[part 5 of 5: packages /POWERTRAIN to /SYSTEM]
AUTOSAR XML (schema 3.2.2)
package /POWERTRAIN  (continued)
  can cluster POWERTRAIN:  (continued)
    physical channel POWERTRAIN  (continued)
      frame NM_ECM_AR: id 0x558, from ECM, frame-length=8, can-addressing-mode=STANDARD  # Network Management
        nm pdu NM_ECM_AR: length=64, nm-cbv-position=0, nm-nid-position=8, nm-user-data-length=6  # Network Management
          signal Awake_Afterrun_Actv: start 26, 1 bit, little-endian, data-type=DC_BOOL, init-value=XDIS_h5tcyk98kzbgrc5svasomeyt/lfalse, transfer-property=PENDING  # Wachhalten für Nachlauf aktiv / Stay awake for afterrun active
          signal Awake_CCP_Actv: start 29, 1 bit, little-endian, data-type=DC_BOOL, init-value=XDIS_h5tcyk98kzbgrc5svasomeyt/lfalse, transfer-property=PENDING  # Wachhalten für CCP-Messtechnik aktiv / Stay awake for CCP measurement active
          signal Awake_Diag_Actv: start 24, 1 bit, little-endian, data-type=DC_BOOL, init-value=XDIS_h5tcyk98kzbgrc5svasomeyt/lfalse, transfer-property=PENDING  # Wachhalten für Diagnose aktiv / Stay awake for diagnostics active
          signal Awake_ECP3_Afterrun: start 30, 1 bit, little-endian, data-type=DC_BOOL, init-value=XDIS_h5tcyk98kzbgrc5svasomeyt/lfalse, transfer-property=PENDING  # Wachhalten für ECP3 Nachlauf / Stay awake for ECP3 afterrun
          signal Awake_ECP4_Afterrun: start 31, 1 bit, little-endian, data-type=DC_BOOL, init-value=XDIS_h5tcyk98kzbgrc5svasomeyt/lfalse, transfer-property=PENDING  # Wachhalten für ECP4 Nachlauf / Stay awake for ECP4 afterrun
          signal Awake_EngFan_Actv: start 27, 1 bit, little-endian, data-type=DC_BOOL, init-value=XDIS_h5tcyk98kzbgrc5svasomeyt/lfalse, transfer-property=PENDING  # Wachhalten für Motorlüfter aktiv / Stay awake for engine fan active
          signal Awake_EngRestart: start 28, 1 bit, little-endian, data-type=DC_BOOL, init-value=XDIS_h5tcyk98kzbgrc5svasomeyt/lfalse, transfer-property=PENDING  # Wachhalten für Motor-Wiederholstart / Stay awake for engine restart
          signal Awake_Ignition_On: start 25, 1 bit, little-endian, data-type=DC_BOOL, init-value=XDIS_h5tcyk98kzbgrc5svasomeyt/lfalse, transfer-property=PENDING  # Wachhalten für Zündung eingeschaltet / Stay awake for ignition on
          signal Awake_NwSt: start 34, 1 bit, little-endian, data-type=DC_BOOL, init-value=XDIS_h5tcyk98kzbgrc5svasomeyt/lfalse, transfer-property=PENDING  # Wachhalten für Netzwerkstartphase / Stay awake for network startup
          signal Awake_SensDiag_Actv: start 33, 1 bit, little-endian, data-type=DC_BOOL, init-value=XDIS_h5tcyk98kzbgrc5svasomeyt/lfalse, transfer-property=PENDING  # Wachhalten für Sensordiagnose / Stay awake for sensor diagnostics active
          signal Awake_TankPressDiag_Actv: start 32, 1 bit, little-endian, data-type=DC_BOOL, init-value=XDIS_h5tcyk98kzbgrc5svasomeyt/lfalse, transfer-property=PENDING  # Modus 15: Wachhalten für Tankpresse Diagnose aktiv / Mode 15: Stay awake for tank press diagnostics active
          signal NM_ActvWakeup: start 4, 1 bit, little-endian, data-type=XDIS_8zznnqbxnga51x5ej9fjpu597, init-value=XDIS_5un2e5dvr5cfu5m0829mn2f54/lfalse, transfer-property=PENDING  # Active Wakeup Bit
          signal NM_Coord_Id: start 1, 2 bit, little-endian, data-type=XDIS_ag9ggh2r04cqwuwmmjm5ytd7y, init-value=XDIS_9kvl7kybe3ytco3yjv5uyh4l/l0, transfer-property=PENDING  # NM Coordinator ID
          signal NM_Coord_SleepRdy: start 3, 1 bit, little-endian, data-type=XDIS_3jji6ucrc8il6b9sf0gioatpa, init-value=XDIS_bxrvh10jawmlothu6ak0oeoq1/lfalse, transfer-property=PENDING  # NM Coordinator Sleep Ready Bit
          signal NM_PartNw_Info: start 6, 1 bit, little-endian, data-type=XDIS_8anm4jlkd5rjz5a4dj8p5z2aw, init-value=XDIS_4setjwl49z8hlvz1qf446y4u9/lfalse, transfer-property=PENDING  # Partial Network Information Bit
          signal NM_RepeatMsg_Rq: start 0, 1 bit, little-endian, data-type=XDIS_ey4gzz3x4s3pbgmamj990b7l5, init-value=XDIS_28el54ybfxmt2nm5z16pi8wul/lfalse, transfer-property=PENDING  # Repeat Message Request
          signal NM_SrcNode_Id: start 8, 8 bit, little-endian, data-type=XDIS_dgxq2p852kecqaamwh1cpsgat, init-value=XDIS_atkxru0u5pzxs91gr5r6s45de/l0, transfer-property=PENDING  # Source Node Identifier
          signal WakeupRsn_ECM: start 16, 8 bit, little-endian, data-type=c08_WakeupRsn_ECM, init-value=XDIS_3y4lg9s0dpmmrleq719wxccpi/l255, transfer-property=PENDING  # Weckgrund / Wakeup reason
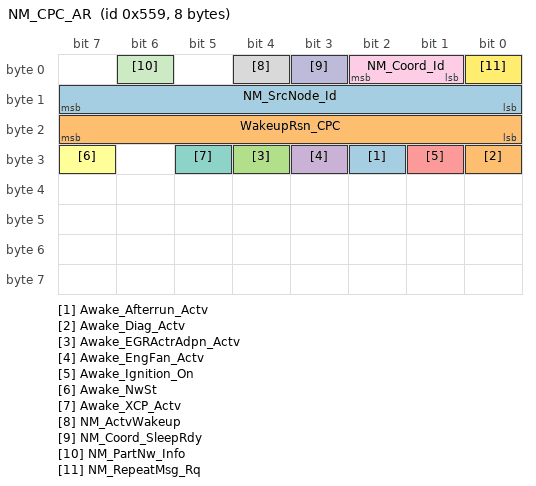
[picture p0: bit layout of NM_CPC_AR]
      frame NM_CPC_AR: id 0x559, from CPC, frame-length=8, can-addressing-mode=STANDARD  # Network Management
        nm pdu NM_CPC_AR: length=64, nm-cbv-position=0, nm-nid-position=8, nm-user-data-length=6  # Network Management
          signal Awake_Afterrun_Actv: start 26, 1 bit, little-endian, data-type=DC_BOOL, init-value=XDIS_h5tcyk98kzbgrc5svasomeyt/lfalse, transfer-property=PENDING  # Wachhalten für Nachlauf aktiv / Stay awake for afterrun active
          signal Awake_Diag_Actv: start 24, 1 bit, little-endian, data-type=DC_BOOL, init-value=XDIS_h5tcyk98kzbgrc5svasomeyt/lfalse, transfer-property=PENDING  # Wachhalten für Diagnose aktiv / Stay awake for diagnostics active
          signal Awake_EGRActrAdpn_Actv: start 28, 1 bit, little-endian, data-type=DC_BOOL, init-value=XDIS_h5tcyk98kzbgrc5svasomeyt/lfalse, transfer-property=PENDING  # Wachhalten für AGR-AktuatorAdaption aktiv / Stay awake for EGR actuator adaptation active
          signal Awake_EngFan_Actv: start 27, 1 bit, little-endian, data-type=DC_BOOL, init-value=XDIS_h5tcyk98kzbgrc5svasomeyt/lfalse, transfer-property=PENDING  # Wachhalten für Motorlüfter aktiv / Stay awake for engine fan active
          signal Awake_Ignition_On: start 25, 1 bit, little-endian, data-type=DC_BOOL, init-value=XDIS_h5tcyk98kzbgrc5svasomeyt/lfalse, transfer-property=PENDING  # Wachhalten für Zündung eingeschaltet / Stay awake for ignition on
          signal Awake_NwSt: start 31, 1 bit, little-endian, data-type=DC_BOOL, init-value=XDIS_h5tcyk98kzbgrc5svasomeyt/lfalse, transfer-property=PENDING  # Wachhalten für Netzwerkstartphase / Stay awake for network startup
          signal Awake_XCP_Actv: start 29, 1 bit, little-endian, data-type=DC_BOOL, init-value=XDIS_h5tcyk98kzbgrc5svasomeyt/lfalse, transfer-property=PENDING  # Wachhalten für XCP-Messung aktiv / Stay awake for XCP measurement active
          signal NM_ActvWakeup: start 4, 1 bit, little-endian, data-type=XDIS_8zznnqbxnga51x5ej9fjpu597, init-value=XDIS_5un2e5dvr5cfu5m0829mn2f54/lfalse, transfer-property=PENDING  # Active Wakeup Bit
          signal NM_Coord_Id: start 1, 2 bit, little-endian, data-type=XDIS_ag9ggh2r04cqwuwmmjm5ytd7y, init-value=XDIS_9kvl7kybe3ytco3yjv5uyh4l/l0, transfer-property=PENDING  # NM Coordinator ID
          signal NM_Coord_SleepRdy: start 3, 1 bit, little-endian, data-type=XDIS_3jji6ucrc8il6b9sf0gioatpa, init-value=XDIS_bxrvh10jawmlothu6ak0oeoq1/lfalse, transfer-property=PENDING  # NM Coordinator Sleep Ready Bit
          signal NM_PartNw_Info: start 6, 1 bit, little-endian, data-type=XDIS_8anm4jlkd5rjz5a4dj8p5z2aw, init-value=XDIS_4setjwl49z8hlvz1qf446y4u9/lfalse, transfer-property=PENDING  # Partial Network Information Bit
          signal NM_RepeatMsg_Rq: start 0, 1 bit, little-endian, data-type=XDIS_ey4gzz3x4s3pbgmamj990b7l5, init-value=XDIS_28el54ybfxmt2nm5z16pi8wul/lfalse, transfer-property=PENDING  # Repeat Message Request
          signal NM_SrcNode_Id: start 8, 8 bit, little-endian, data-type=XDIS_dgxq2p852kecqaamwh1cpsgat, init-value=XDIS_atkxru0u5pzxs91gr5r6s45de/l0, transfer-property=PENDING  # Source Node Identifier
          signal WakeupRsn_CPC: start 16, 8 bit, little-endian, data-type=c08_WakeupRsn_CPC, init-value=XDIS_zfdazignwfnolwf6r1u16rwh/l255, transfer-property=PENDING  # Weckgrund / Wakeup reason
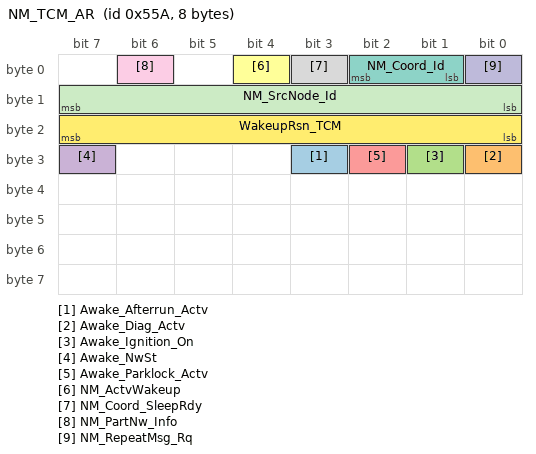
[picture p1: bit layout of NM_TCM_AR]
      frame NM_TCM_AR: id 0x55A, from TCM, frame-length=8, can-addressing-mode=STANDARD  # Network Management
        nm pdu NM_TCM_AR: length=64, nm-cbv-position=0, nm-nid-position=8, nm-user-data-length=6  # Network Management
          signal Awake_Afterrun_Actv: start 27, 1 bit, little-endian, data-type=DC_BOOL, init-value=XDIS_h5tcyk98kzbgrc5svasomeyt/lfalse, transfer-property=PENDING  # Wachhalten für Nachlauf aktiv / Stay awake for afterrun active
          signal Awake_Diag_Actv: start 24, 1 bit, little-endian, data-type=DC_BOOL, init-value=XDIS_h5tcyk98kzbgrc5svasomeyt/lfalse, transfer-property=PENDING  # Wachhalten für Diagnose aktiv / Stay awake for diagnostics active
          signal Awake_Ignition_On: start 25, 1 bit, little-endian, data-type=DC_BOOL, init-value=XDIS_h5tcyk98kzbgrc5svasomeyt/lfalse, transfer-property=PENDING  # Wachhalten für Zündung eingeschaltet / Stay awake for ignition on
          signal Awake_NwSt: start 31, 1 bit, little-endian, data-type=DC_BOOL, init-value=XDIS_h5tcyk98kzbgrc5svasomeyt/lfalse, transfer-property=PENDING  # Wachhalten für Netzwerkstartphase / Stay awake for network startup
          signal Awake_Parklock_Actv: start 26, 1 bit, little-endian, data-type=DC_BOOL, init-value=XDIS_h5tcyk98kzbgrc5svasomeyt/lfalse, transfer-property=PENDING  # Wachhalten für Parklock / Stay awake for moving the Parklock
          signal NM_ActvWakeup: start 4, 1 bit, little-endian, data-type=XDIS_8zznnqbxnga51x5ej9fjpu597, init-value=XDIS_5un2e5dvr5cfu5m0829mn2f54/lfalse, transfer-property=PENDING  # Active Wakeup Bit
          signal NM_Coord_Id: start 1, 2 bit, little-endian, data-type=XDIS_ag9ggh2r04cqwuwmmjm5ytd7y, init-value=XDIS_9kvl7kybe3ytco3yjv5uyh4l/l0, transfer-property=PENDING  # NM Coordinator ID
          signal NM_Coord_SleepRdy: start 3, 1 bit, little-endian, data-type=XDIS_3jji6ucrc8il6b9sf0gioatpa, init-value=XDIS_bxrvh10jawmlothu6ak0oeoq1/lfalse, transfer-property=PENDING  # NM Coordinator Sleep Ready Bit
          signal NM_PartNw_Info: start 6, 1 bit, little-endian, data-type=XDIS_8anm4jlkd5rjz5a4dj8p5z2aw, init-value=XDIS_4setjwl49z8hlvz1qf446y4u9/lfalse, transfer-property=PENDING  # Partial Network Information Bit
          signal NM_RepeatMsg_Rq: start 0, 1 bit, little-endian, data-type=XDIS_ey4gzz3x4s3pbgmamj990b7l5, init-value=XDIS_28el54ybfxmt2nm5z16pi8wul/lfalse, transfer-property=PENDING  # Repeat Message Request
          signal NM_SrcNode_Id: start 8, 8 bit, little-endian, data-type=XDIS_dgxq2p852kecqaamwh1cpsgat, init-value=XDIS_atkxru0u5pzxs91gr5r6s45de/l0, transfer-property=PENDING  # Source Node Identifier
          signal WakeupRsn_TCM: start 16, 8 bit, little-endian, data-type=c08_WakeupRsn_TCM, init-value=XDIS_e4uet9j8xwkldgba4oq2381xs/l255, transfer-property=PENDING  # Weckgrund / Wakeup reason
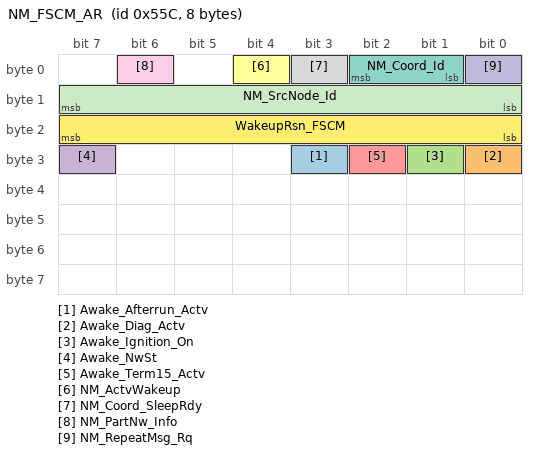
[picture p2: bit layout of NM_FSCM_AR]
      frame NM_FSCM_AR: id 0x55C, from FSCM, frame-length=8, can-addressing-mode=STANDARD  # Network Management
        nm pdu NM_FSCM_AR: length=64, nm-cbv-position=0, nm-nid-position=8, nm-user-data-length=6  # Network Management
          signal Awake_Afterrun_Actv: start 27, 1 bit, little-endian, data-type=DC_BOOL, init-value=XDIS_h5tcyk98kzbgrc5svasomeyt/lfalse, transfer-property=PENDING  # Wachhalten für Nachlauf aktiv / Stay awake for afterrun active
          signal Awake_Diag_Actv: start 24, 1 bit, little-endian, data-type=DC_BOOL, init-value=XDIS_h5tcyk98kzbgrc5svasomeyt/lfalse, transfer-property=PENDING  # Wachhalten für Diagnose aktiv / Stay awake for diagnostics active
          signal Awake_Ignition_On: start 25, 1 bit, little-endian, data-type=DC_BOOL, init-value=XDIS_h5tcyk98kzbgrc5svasomeyt/lfalse, transfer-property=PENDING  # Wachhalten für Zündung eingeschaltet / Stay awake for ignition on
          signal Awake_NwSt: start 31, 1 bit, little-endian, data-type=DC_BOOL, init-value=XDIS_h5tcyk98kzbgrc5svasomeyt/lfalse, transfer-property=PENDING  # Wachhalten für Netzwerkstartphase / Stay awake for network startup
          signal Awake_Term15_Actv: start 26, 1 bit, little-endian, data-type=DC_BOOL, init-value=XDIS_h5tcyk98kzbgrc5svasomeyt/lfalse, transfer-property=PENDING  # Wachhalten für Klemme 15 aktiv / Stay awake for terminal 15 active
          signal NM_ActvWakeup: start 4, 1 bit, little-endian, data-type=XDIS_8zznnqbxnga51x5ej9fjpu597, init-value=XDIS_5un2e5dvr5cfu5m0829mn2f54/lfalse, transfer-property=PENDING  # Active Wakeup Bit
          signal NM_Coord_Id: start 1, 2 bit, little-endian, data-type=XDIS_ag9ggh2r04cqwuwmmjm5ytd7y, init-value=XDIS_9kvl7kybe3ytco3yjv5uyh4l/l0, transfer-property=PENDING  # NM Coordinator ID
          signal NM_Coord_SleepRdy: start 3, 1 bit, little-endian, data-type=XDIS_3jji6ucrc8il6b9sf0gioatpa, init-value=XDIS_bxrvh10jawmlothu6ak0oeoq1/lfalse, transfer-property=PENDING  # NM Coordinator Sleep Ready Bit
          signal NM_PartNw_Info: start 6, 1 bit, little-endian, data-type=XDIS_8anm4jlkd5rjz5a4dj8p5z2aw, init-value=XDIS_4setjwl49z8hlvz1qf446y4u9/lfalse, transfer-property=PENDING  # Partial Network Information Bit
          signal NM_RepeatMsg_Rq: start 0, 1 bit, little-endian, data-type=XDIS_ey4gzz3x4s3pbgmamj990b7l5, init-value=XDIS_28el54ybfxmt2nm5z16pi8wul/lfalse, transfer-property=PENDING  # Repeat Message Request
          signal NM_SrcNode_Id: start 8, 8 bit, little-endian, data-type=XDIS_dgxq2p852kecqaamwh1cpsgat, init-value=XDIS_atkxru0u5pzxs91gr5r6s45de/l0, transfer-property=PENDING  # Source Node Identifier
          signal WakeupRsn_FSCM: start 16, 8 bit, little-endian, data-type=c08_WakeupRsn_FSCM, init-value=XDIS_c1uleirk2bcioplgr7prkm23d/l255, transfer-property=PENDING  # Weckgrund / Wakeup reason
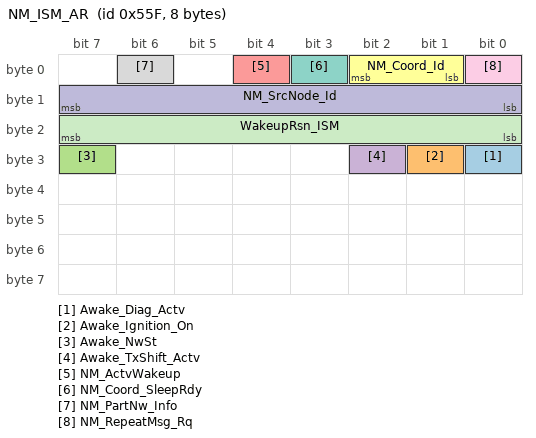
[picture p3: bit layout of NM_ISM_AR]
      frame NM_ISM_AR: id 0x55F, from ISM, frame-length=8, can-addressing-mode=STANDARD  # Network Management
        nm pdu NM_ISM_AR: length=64, nm-cbv-position=0, nm-nid-position=8, nm-user-data-length=6  # Network Management
          signal Awake_Diag_Actv: start 24, 1 bit, little-endian, data-type=DC_BOOL, init-value=XDIS_h5tcyk98kzbgrc5svasomeyt/lfalse, transfer-property=PENDING  # Wachhalten für Diagnose aktiv / Stay awake for diagnostics active
          signal Awake_Ignition_On: start 25, 1 bit, little-endian, data-type=DC_BOOL, init-value=XDIS_h5tcyk98kzbgrc5svasomeyt/lfalse, transfer-property=PENDING  # Wachhalten für Zündung eingeschaltet / Stay awake for ignition on
          signal Awake_NwSt: start 31, 1 bit, little-endian, data-type=DC_BOOL, init-value=XDIS_h5tcyk98kzbgrc5svasomeyt/lfalse, transfer-property=PENDING  # Wachhalten für Netzwerkstartphase / Stay awake for network startup
          signal Awake_TxShift_Actv: start 26, 1 bit, little-endian, data-type=DC_BOOL, init-value=XDIS_h5tcyk98kzbgrc5svasomeyt/lfalse, transfer-property=PENDING  # Wachhalten für Getriebe-Schaltvorgang aktiv / Stay awake for transmission shifting active
          signal NM_ActvWakeup: start 4, 1 bit, little-endian, data-type=XDIS_8zznnqbxnga51x5ej9fjpu597, init-value=XDIS_5un2e5dvr5cfu5m0829mn2f54/lfalse, transfer-property=PENDING  # Active Wakeup Bit
          signal NM_Coord_Id: start 1, 2 bit, little-endian, data-type=XDIS_ag9ggh2r04cqwuwmmjm5ytd7y, init-value=XDIS_9kvl7kybe3ytco3yjv5uyh4l/l0, transfer-property=PENDING  # NM Coordinator ID
          signal NM_Coord_SleepRdy: start 3, 1 bit, little-endian, data-type=XDIS_3jji6ucrc8il6b9sf0gioatpa, init-value=XDIS_bxrvh10jawmlothu6ak0oeoq1/lfalse, transfer-property=PENDING  # NM Coordinator Sleep Ready Bit
          signal NM_PartNw_Info: start 6, 1 bit, little-endian, data-type=XDIS_8anm4jlkd5rjz5a4dj8p5z2aw, init-value=XDIS_4setjwl49z8hlvz1qf446y4u9/lfalse, transfer-property=PENDING  # Partial Network Information Bit
          signal NM_RepeatMsg_Rq: start 0, 1 bit, little-endian, data-type=XDIS_ey4gzz3x4s3pbgmamj990b7l5, init-value=XDIS_28el54ybfxmt2nm5z16pi8wul/lfalse, transfer-property=PENDING  # Repeat Message Request
          signal NM_SrcNode_Id: start 8, 8 bit, little-endian, data-type=XDIS_dgxq2p852kecqaamwh1cpsgat, init-value=XDIS_atkxru0u5pzxs91gr5r6s45de/l0, transfer-property=PENDING  # Source Node Identifier
          signal WakeupRsn_ISM: start 16, 8 bit, little-endian, data-type=c08_WakeupRsn_ISM, init-value=XDIS_2o0otao352rw44tj5bta4i007/l255, transfer-property=PENDING  # Weckgrund / Wakeup reason
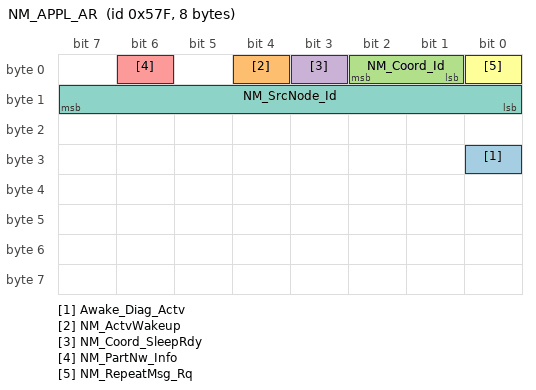
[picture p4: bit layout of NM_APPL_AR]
      frame NM_APPL_AR: id 0x57F, to ASX CPC DRVU ECM FSCM ISM TCM, frame-length=8, can-addressing-mode=STANDARD, rx-identifier-range={lower-can-id=1280, upper-can-id=1407}
        nm pdu NM_APPL_AR: length=64, nm-cbv-position=0, nm-nid-position=8, nm-user-data-length=6  # Network Management
          signal Awake_Diag_Actv: start 24, 1 bit, little-endian, data-type=DC_BOOL, init-value=XDIS_h5tcyk98kzbgrc5svasomeyt/lfalse, transfer-property=PENDING  # Wachhalten für Diagnose aktiv / Stay awake for diagnostics active
          signal NM_ActvWakeup: start 4, 1 bit, little-endian, data-type=XDIS_8zznnqbxnga51x5ej9fjpu597, init-value=XDIS_5un2e5dvr5cfu5m0829mn2f54/lfalse, transfer-property=PENDING  # Active Wakeup Bit
          signal NM_Coord_Id: start 1, 2 bit, little-endian, data-type=XDIS_ag9ggh2r04cqwuwmmjm5ytd7y, init-value=XDIS_9kvl7kybe3ytco3yjv5uyh4l/l0, transfer-property=PENDING  # NM Coordinator ID
          signal NM_Coord_SleepRdy: start 3, 1 bit, little-endian, data-type=XDIS_3jji6ucrc8il6b9sf0gioatpa, init-value=XDIS_bxrvh10jawmlothu6ak0oeoq1/lfalse, transfer-property=PENDING  # NM Coordinator Sleep Ready Bit
          signal NM_PartNw_Info: start 6, 1 bit, little-endian, data-type=XDIS_8anm4jlkd5rjz5a4dj8p5z2aw, init-value=XDIS_4setjwl49z8hlvz1qf446y4u9/lfalse, transfer-property=PENDING  # Partial Network Information Bit
          signal NM_RepeatMsg_Rq: start 0, 1 bit, little-endian, data-type=XDIS_ey4gzz3x4s3pbgmamj990b7l5, init-value=XDIS_28el54ybfxmt2nm5z16pi8wul/lfalse, transfer-property=PENDING  # Repeat Message Request
          signal NM_SrcNode_Id: start 8, 8 bit, little-endian, data-type=XDIS_dgxq2p852kecqaamwh1cpsgat, init-value=XDIS_atkxru0u5pzxs91gr5r6s45de/l0, transfer-property=PENDING  # Source Node Identifier
      frame DIAG_RS_ASX: id 0x5AA, from ASX, to CPC, frame-length=8, can-addressing-mode=STANDARD  # Diagnoseantwort / Diagnostic Response
        n pdu DIAG_RS_ASX: length=64, unused-bit-pattern=0  # Diagnose Antwort / Diagnostic Response
      frame DIAG_RS_FFAP: id 0x5DC, from FFAP_STAR_2, to CPC, frame-length=8, can-addressing-mode=STANDARD  # Diagnoseantwort / Diagnostic Response
        n pdu DIAG_RS_FFAP: length=64, unused-bit-pattern=0  # Diagnose Antwort / Diagnostic Response
      frame DIAG_RS_AWD: id 0x5DE, to CPC, frame-length=8, can-addressing-mode=STANDARD  # Diagnoseantwort / Diagnostic Response
        n pdu DIAG_RS_AWD: length=64, unused-bit-pattern=0  # Diagnose Antwort / Diagnostic Response
      frame DIAG_RS_ISM: id 0x5DF, from ISM, to CPC, frame-length=8, can-addressing-mode=STANDARD  # Diagnoseantwort / Diagnostic Response
        n pdu DIAG_RS_ISM: length=64, unused-bit-pattern=0  # Diagnose-Response / Diagnostic Response
      frame DIAG_RQ_ASX: id 0x62A, from CPC, to ASX, frame-length=8, can-addressing-mode=STANDARD  # Diagnose Anfrage / Diagnostic Request
        n pdu DIAG_RQ_ASX: length=64, unused-bit-pattern=0  # Diagnose Anfrage / Diagnostic Request
      frame DIAG_RQ_FFAP: id 0x65C, from CPC, to FFAP_STAR_2, frame-length=8, can-addressing-mode=STANDARD  # Diagnose Anfrage / Diagnostic Request
        n pdu DIAG_RQ_FFAP: length=64, unused-bit-pattern=0  # Diagnose Anfrage / Diagnostic Request
      frame DIAG_RQ_AWD: id 0x65E, from CPC, frame-length=8, can-addressing-mode=STANDARD  # Diagnose Anfrage / Diagnostic Request
        n pdu DIAG_RQ_AWD: length=64, unused-bit-pattern=0  # Diagnose Anfrage / Diagnostic Request
      frame DIAG_RQ_ISM: id 0x65F, from CPC, to ISM, frame-length=8, can-addressing-mode=STANDARD  # Diagnoseanfrage / Diagnostic Request
        n pdu DIAG_RQ_ISM: length=64, unused-bit-pattern=0  # Diagnose-Request / Diagnostic Request
      frame DIAG_RQ_TCM: id 0x7E1, from CPC, to TCM, frame-length=8, can-addressing-mode=STANDARD  # Diagnoseanfrage / Diagnostic Request
        n pdu DIAG_RQ_TCM: length=64, unused-bit-pattern=0  # Diagnoseanfrage / Diagnostic Request
      frame DIAG_RQ_FSCM: id 0x7E3, from CPC, to FSCM, frame-length=8, can-addressing-mode=STANDARD  # Diagnoseanfrage / Diagnostic Request
        n pdu DIAG_RQ_FSCM: length=64, unused-bit-pattern=0  # Diagnoseanfrage / Diagnostic Request
      frame DIAG_RS_TCM: id 0x7E9, from TCM, to CPC, frame-length=8, can-addressing-mode=STANDARD  # Diagnoseantwort / Diagnostic Response
        n pdu DIAG_RS_TCM: length=64, unused-bit-pattern=0  # Diagnoseantwort / Diagnostic Response
      frame DIAG_RS_FSCM: id 0x7EB, from FSCM, to CPC, frame-length=8, can-addressing-mode=STANDARD  # Diagnoseantwort / Diagnostic Response
        n pdu DIAG_RS_FSCM: length=64, unused-bit-pattern=0  # Diagnoseantwort / Diagnostic Response
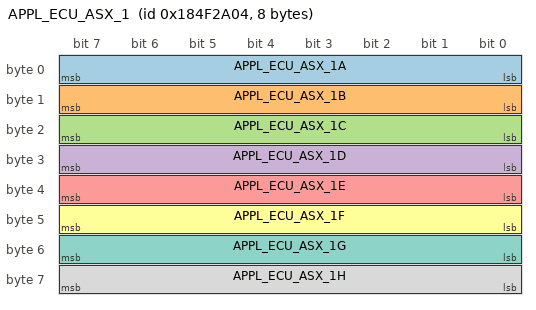
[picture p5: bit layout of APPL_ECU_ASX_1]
      frame APPL_ECU_ASX_1: id 0x184F2A04, to ASX, frame-length=8, can-addressing-mode=EXTENDED
        pdu APPL_ECU_ASX_1: length=64, unused-bit-pattern=0, event-controlled-timing=number-of-repeats=0, minimum-delay=0.0050  # Applikation zu Steuergerät / Application to ECU
          signal APPL_ECU_ASX_1A: start 0, 8 bit, little-endian, data-type=c08_UInt_SNA_na, init-value=XDIS_2kt9ss9xytkqyzr4359iyexvi/l0, to ASX  # Applikation zu Steuergerät / Application to ECU
          signal APPL_ECU_ASX_1B: start 8, 8 bit, little-endian, data-type=c08_UInt_SNA_na, init-value=XDIS_2kt9ss9xytkqyzr4359iyexvi/l0, to ASX  # Applikation zu Steuergerät / Application to ECU
          signal APPL_ECU_ASX_1C: start 16, 8 bit, little-endian, data-type=c08_UInt_SNA_na, init-value=XDIS_2kt9ss9xytkqyzr4359iyexvi/l0, to ASX  # Applikation zu Steuergerät / Application to ECU
          signal APPL_ECU_ASX_1D: start 24, 8 bit, little-endian, data-type=c08_UInt_SNA_na, init-value=XDIS_2kt9ss9xytkqyzr4359iyexvi/l0, to ASX  # Applikation zu Steuergerät / Application to ECU
          signal APPL_ECU_ASX_1E: start 32, 8 bit, little-endian, data-type=c08_UInt_SNA_na, init-value=XDIS_2kt9ss9xytkqyzr4359iyexvi/l0, to ASX  # Applikation zu Steuergerät / Application to ECU
          signal APPL_ECU_ASX_1F: start 40, 8 bit, little-endian, data-type=c08_UInt_SNA_na, init-value=XDIS_2kt9ss9xytkqyzr4359iyexvi/l0, to ASX  # Applikation zu Steuergerät / Application to ECU
          signal APPL_ECU_ASX_1G: start 48, 8 bit, little-endian, data-type=c08_UInt_SNA_na, init-value=XDIS_2kt9ss9xytkqyzr4359iyexvi/l0, to ASX  # Applikation zu Steuergerät / Application to ECU
          signal APPL_ECU_ASX_1H: start 56, 8 bit, little-endian, data-type=c08_UInt_SNA_na, init-value=XDIS_2kt9ss9xytkqyzr4359iyexvi/l0, to ASX  # Applikation zu Steuergerät / Application to ECU
          signal APPL_ECU_ASX_1_5v54k457m0s1vt3vxsj5u865a: little-endian, system-signal=[APPL_ECU_ASX_1A, APPL_ECU_ASX_1B, APPL_ECU_ASX_1C, APPL_ECU_ASX_1D, APPL_ECU_ASX_1E, APPL_ECU_ASX_1F, APPL_ECU_ASX_1G, APPL_ECU_ASX_1H], transfer-property=TRIGGERED, to ASX  # Applikation zu Steuergerät (degraded) / Application to ECU (degraded)
      frame DIAGX_RQ_TCM_OBD: id 0x18DA5AF1, from CPC, to TCM, frame-length=8, can-addressing-mode=EXTENDED  # Diagnoseanfrage OBD / Diagnostic Request OBD
        n pdu DIAGX_RQ_TCM_OBD: length=64, unused-bit-pattern=0  # Diagnoseanfrage OBD / Diagnostic Request OBD
      frame DIAGX_RQ_FSCM_OBD: id 0x18DA5CF1, from CPC, to FSCM, frame-length=8, can-addressing-mode=EXTENDED  # Diagnoseanfrage OBD / Diagnostic Request OBD
        n pdu DIAGX_RQ_FSCM_OBD: length=64, unused-bit-pattern=0  # Diagnoseanfrage OBD / Diagnostic Request OBD
      frame DIAGX_RS_TCM_OBD: id 0x18DAF15A, from TCM, to CPC, frame-length=8, can-addressing-mode=EXTENDED  # Diagnoseantwort OBD / Diagnostic Response OBD
        n pdu DIAGX_RS_TCM_OBD: length=64, unused-bit-pattern=0  # Diagnoseantwort OBD / Diagnostic Response OBD
      frame DIAGX_RS_FSCM_OBD: id 0x18DAF15C, from FSCM, to CPC, frame-length=8, can-addressing-mode=EXTENDED  # Diagnoseantwort OBD / Diagnostic Response OBD
        n pdu DIAGX_RS_FSCM_OBD: length=64, unused-bit-pattern=0  # Diagnoseantwort OBD / Diagnostic Response OBD
      frame DIAGX_RQ_GLOBAL_OBD: id 0x18DB33F1, from CPC, to FSCM TCM, frame-length=8, can-addressing-mode=EXTENDED  # Funktionale Diagnose Anfrage (OBD) / Functional Diagnostic Request (OBD)
        n pdu DIAGX_RQ_GLOBAL_OBD: length=64, unused-bit-pattern=0  # Funktionaler Diagnose-Request (OBD) / Functional Diagnostic Request (OBD)
      frame ROE_ASX: id 0x18EF2A00, from ASX, to CPC, frame-length=8, can-addressing-mode=EXTENDED  # RoE lite
        pdu ROE_ASX: length=64, unused-bit-pattern=0, event-controlled-timing=number-of-repeats=0, minimum-delay=0.2  # RoE-lite / RoE lite
          signal ROE_DTC_ASX: start 32, 24 bit, little-endian, data-type=c24_0_16777215_1_SNA_na, init-value=XDIS_d00a2pwsicon8afnf0ovtodtq/l0, to CPC  # Fehlercode RoE-lite / RoE lite diagnostic trouble code
          signal ROE_DTC_Stat_ASX: start 56, 8 bit, little-endian, data-type=c08_0_255_1_SNA_na, init-value=XDIS_e83grhz0aqm1yaa82ns55ebek/l0, to CPC  # Fehlercode-Status RoE-lite / RoE lite diagnostic trouble code state
          signal ROE_Header_ASX: start 0, 32 bit, little-endian, data-type=c32_0_4294967295_1_SNA_na, init-value=l940295, to CPC  # Header RoE-lite / RoE lite header
          signal ROE_ASX_bh0k1l31zxyeftblxvt1o8neg: little-endian, system-signal=[ROE_DTC_ASX, ROE_DTC_Stat_ASX, ROE_Header_ASX], transfer-property=TRIGGERED, to CPC  # RoE-lite (degraded) / RoE lite (degraded)
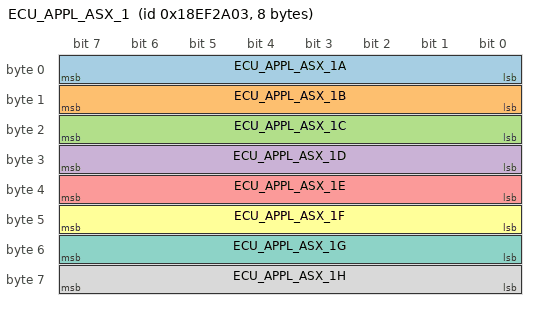
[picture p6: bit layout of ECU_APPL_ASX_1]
      frame ECU_APPL_ASX_1: id 0x18EF2A03, from ASX, frame-length=8, can-addressing-mode=EXTENDED
        pdu ECU_APPL_ASX_1: length=64, unused-bit-pattern=0, event-controlled-timing=number-of-repeats=0, minimum-delay=0.0050  # Applikation zu Steuergerät / Application to ECU
          signal ECU_APPL_ASX_1A: start 0, 8 bit, little-endian, data-type=c08_UInt_SNA_na, init-value=XDIS_2kt9ss9xytkqyzr4359iyexvi/l0  # Applikation zu Steuergerät / Application to ECU
          signal ECU_APPL_ASX_1B: start 8, 8 bit, little-endian, data-type=c08_UInt_SNA_na, init-value=XDIS_2kt9ss9xytkqyzr4359iyexvi/l0  # Applikation zu Steuergerät / Application to ECU
          signal ECU_APPL_ASX_1C: start 16, 8 bit, little-endian, data-type=c08_UInt_SNA_na, init-value=XDIS_2kt9ss9xytkqyzr4359iyexvi/l0  # Applikation zu Steuergerät / Application to ECU
          signal ECU_APPL_ASX_1D: start 24, 8 bit, little-endian, data-type=c08_UInt_SNA_na, init-value=XDIS_2kt9ss9xytkqyzr4359iyexvi/l0  # Applikation zu Steuergerät / Application to ECU
          signal ECU_APPL_ASX_1E: start 32, 8 bit, little-endian, data-type=c08_UInt_SNA_na, init-value=XDIS_2kt9ss9xytkqyzr4359iyexvi/l0  # Applikation zu Steuergerät / Application to ECU
          signal ECU_APPL_ASX_1F: start 40, 8 bit, little-endian, data-type=c08_UInt_SNA_na, init-value=XDIS_2kt9ss9xytkqyzr4359iyexvi/l0  # Applikation zu Steuergerät / Application to ECU
          signal ECU_APPL_ASX_1G: start 48, 8 bit, little-endian, data-type=c08_UInt_SNA_na, init-value=XDIS_2kt9ss9xytkqyzr4359iyexvi/l0  # Applikation zu Steuergerät / Application to ECU
          signal ECU_APPL_ASX_1H: start 56, 8 bit, little-endian, data-type=c08_UInt_SNA_na, init-value=XDIS_2kt9ss9xytkqyzr4359iyexvi/l0  # Applikation zu Steuergerät / Application to ECU
          signal ECU_APPL_ASX_1_3be5jsdyicsypdagrm44msol0: little-endian, system-signal=[ECU_APPL_ASX_1A, ECU_APPL_ASX_1B, ECU_APPL_ASX_1C, ECU_APPL_ASX_1D, ECU_APPL_ASX_1E, ECU_APPL_ASX_1F, ECU_APPL_ASX_1G, ECU_APPL_ASX_1H], transfer-property=TRIGGERED  # Applikation zu Steuergerät (degraded) / Application to ECU (degraded)
      frame ROE_TCM: id 0x18EF5A00, from TCM, to CPC, frame-length=8, can-addressing-mode=EXTENDED  # RoE lite
        pdu ROE_TCM: length=64, unused-bit-pattern=0, event-controlled-timing=number-of-repeats=0, minimum-delay=0.2  # RoE-lite / RoE lite
          signal ROE_DTC_Stat_TCM: start 56, 8 bit, little-endian, data-type=c08_0_255_1_SNA_na, init-value=XDIS_e83grhz0aqm1yaa82ns55ebek/l0, to CPC  # Fehlercode-Status RoE-lite / RoE lite diagnostic trouble code state
          signal ROE_DTC_TCM: start 32, 24 bit, little-endian, data-type=c24_0_16777215_1_SNA_na, init-value=XDIS_d00a2pwsicon8afnf0ovtodtq/l0, to CPC  # Fehlercode RoE-lite / RoE lite diagnostic trouble code
          signal ROE_Header_TCM: start 0, 32 bit, little-endian, data-type=c32_0_4294967295_1_SNA_na, init-value=l940295, to CPC  # Header RoE-lite / RoE lite header
          signal ROE_TCM_7sr2csz1sd5kgujzog3cttxu0: little-endian, system-signal=[ROE_DTC_Stat_TCM, ROE_DTC_TCM, ROE_Header_TCM], transfer-property=TRIGGERED, to CPC  # RoE-lite (degraded) / RoE lite (degraded)
      frame XCP_Rq_TCM: id 0x18EF5A01, from CPC, to TCM, frame-length=8, can-addressing-mode=EXTENDED
        user defined i pdu XCP_Rq_TCM: length=64, unused-bit-pattern=0, cdd-type=XCP  # XCP-Anforderung / Extended calibration protocol request
      frame XCP_Rs_TCM: id 0x18EF5A02, from TCM, to CPC, frame-length=8, can-addressing-mode=EXTENDED
        user defined i pdu XCP_Rs_TCM: length=64, unused-bit-pattern=0, cdd-type=XCP  # XCP-Anforderung / Extended calibration protocol response
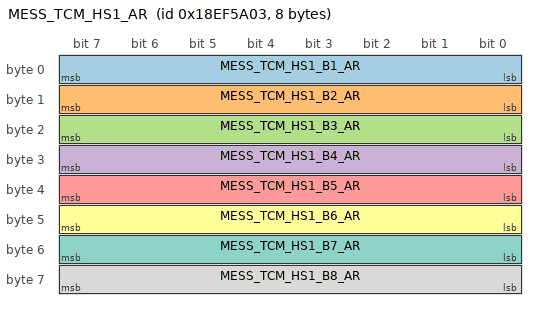
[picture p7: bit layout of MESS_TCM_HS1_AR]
      frame MESS_TCM_HS1_AR: id 0x18EF5A03, to TCM, frame-length=8, can-addressing-mode=EXTENDED  # TCM_HS1_AR
        pdu MESS_TCM_HS1_AR: length=64, unused-bit-pattern=0, event-controlled-timing=number-of-repeats=0, minimum-delay=0.0050
          signal MESS_TCM_HS1_B1_AR: start 0, 8 bit, little-endian, data-type=c08_UInt_SNA_na, init-value=XDIS_2kt9ss9xytkqyzr4359iyexvi/l0, to TCM
          signal MESS_TCM_HS1_B2_AR: start 8, 8 bit, little-endian, data-type=c08_UInt_SNA_na, init-value=XDIS_2kt9ss9xytkqyzr4359iyexvi/l0, to TCM
          signal MESS_TCM_HS1_B3_AR: start 16, 8 bit, little-endian, data-type=c08_UInt_SNA_na, init-value=XDIS_2kt9ss9xytkqyzr4359iyexvi/l0, to TCM
          signal MESS_TCM_HS1_B4_AR: start 24, 8 bit, little-endian, data-type=c08_UInt_SNA_na, init-value=XDIS_2kt9ss9xytkqyzr4359iyexvi/l0, to TCM
          signal MESS_TCM_HS1_B5_AR: start 32, 8 bit, little-endian, data-type=c08_UInt_SNA_na, init-value=XDIS_2kt9ss9xytkqyzr4359iyexvi/l0, to TCM
          signal MESS_TCM_HS1_B6_AR: start 40, 8 bit, little-endian, data-type=c08_UInt_SNA_na, init-value=XDIS_2kt9ss9xytkqyzr4359iyexvi/l0, to TCM
          signal MESS_TCM_HS1_B7_AR: start 48, 8 bit, little-endian, data-type=c08_UInt_SNA_na, init-value=XDIS_2kt9ss9xytkqyzr4359iyexvi/l0, to TCM
          signal MESS_TCM_HS1_B8_AR: start 56, 8 bit, little-endian, data-type=c08_UInt_SNA_na, init-value=XDIS_2kt9ss9xytkqyzr4359iyexvi/l0, to TCM
          signal Mess_TCM_HS1_AR_5jqztx9cjivblmvl1y06ch5be: little-endian, system-signal=[MESS_TCM_HS1_B1_AR, MESS_TCM_HS1_B2_AR, MESS_TCM_HS1_B3_AR, MESS_TCM_HS1_B4_AR, MESS_TCM_HS1_B5_AR, MESS_TCM_HS1_B6_AR, MESS_TCM_HS1_B7_AR, MESS_TCM_HS1_B8_AR], transfer-property=TRIGGERED, to TCM  # Messdaten (degraded) / Measurement data (degraded)
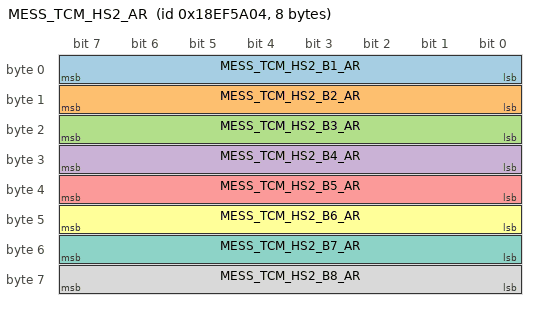
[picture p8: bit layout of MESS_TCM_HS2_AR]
      frame MESS_TCM_HS2_AR: id 0x18EF5A04, to TCM, frame-length=8, can-addressing-mode=EXTENDED  # TCM_HS2_AR
        pdu MESS_TCM_HS2_AR: length=64, unused-bit-pattern=0, event-controlled-timing=number-of-repeats=0, minimum-delay=0.0050
          signal MESS_TCM_HS2_B1_AR: start 0, 8 bit, little-endian, data-type=c08_UInt_SNA_na, init-value=XDIS_2kt9ss9xytkqyzr4359iyexvi/l0, to TCM
          signal MESS_TCM_HS2_B2_AR: start 8, 8 bit, little-endian, data-type=c08_UInt_SNA_na, init-value=XDIS_2kt9ss9xytkqyzr4359iyexvi/l0, to TCM
          signal MESS_TCM_HS2_B3_AR: start 16, 8 bit, little-endian, data-type=c08_UInt_SNA_na, init-value=XDIS_2kt9ss9xytkqyzr4359iyexvi/l0, to TCM
          signal MESS_TCM_HS2_B4_AR: start 24, 8 bit, little-endian, data-type=c08_UInt_SNA_na, init-value=XDIS_2kt9ss9xytkqyzr4359iyexvi/l0, to TCM
          signal MESS_TCM_HS2_B5_AR: start 32, 8 bit, little-endian, data-type=c08_UInt_SNA_na, init-value=XDIS_2kt9ss9xytkqyzr4359iyexvi/l0, to TCM
          signal MESS_TCM_HS2_B6_AR: start 40, 8 bit, little-endian, data-type=c08_UInt_SNA_na, init-value=XDIS_2kt9ss9xytkqyzr4359iyexvi/l0, to TCM
          signal MESS_TCM_HS2_B7_AR: start 48, 8 bit, little-endian, data-type=c08_UInt_SNA_na, init-value=XDIS_2kt9ss9xytkqyzr4359iyexvi/l0, to TCM
          signal MESS_TCM_HS2_B8_AR: start 56, 8 bit, little-endian, data-type=c08_UInt_SNA_na, init-value=XDIS_2kt9ss9xytkqyzr4359iyexvi/l0, to TCM
          signal Mess_TCM_HS2_AR_dcm84cc8pxh7e5mqxg338wu8c: little-endian, system-signal=[MESS_TCM_HS2_B1_AR, MESS_TCM_HS2_B2_AR, MESS_TCM_HS2_B3_AR, MESS_TCM_HS2_B4_AR, MESS_TCM_HS2_B5_AR, MESS_TCM_HS2_B6_AR, MESS_TCM_HS2_B7_AR, MESS_TCM_HS2_B8_AR], transfer-property=TRIGGERED, to TCM  # Messdaten (degraded) / Measurement data (degraded)
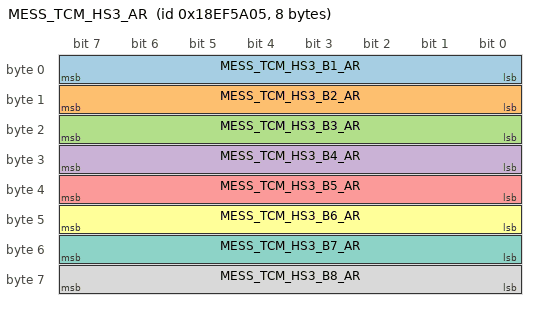
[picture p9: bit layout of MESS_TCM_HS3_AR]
      frame MESS_TCM_HS3_AR: id 0x18EF5A05, to TCM, frame-length=8, can-addressing-mode=EXTENDED  # TCM_HS3_AR
        pdu MESS_TCM_HS3_AR: length=64, unused-bit-pattern=0, event-controlled-timing=number-of-repeats=0, minimum-delay=0.0050
          signal MESS_TCM_HS3_B1_AR: start 0, 8 bit, little-endian, data-type=c08_UInt_SNA_na, init-value=XDIS_2kt9ss9xytkqyzr4359iyexvi/l0, to TCM
          signal MESS_TCM_HS3_B2_AR: start 8, 8 bit, little-endian, data-type=c08_UInt_SNA_na, init-value=XDIS_2kt9ss9xytkqyzr4359iyexvi/l0, to TCM
          signal MESS_TCM_HS3_B3_AR: start 16, 8 bit, little-endian, data-type=c08_UInt_SNA_na, init-value=XDIS_2kt9ss9xytkqyzr4359iyexvi/l0, to TCM
          signal MESS_TCM_HS3_B4_AR: start 24, 8 bit, little-endian, data-type=c08_UInt_SNA_na, init-value=XDIS_2kt9ss9xytkqyzr4359iyexvi/l0, to TCM
          signal MESS_TCM_HS3_B5_AR: start 32, 8 bit, little-endian, data-type=c08_UInt_SNA_na, init-value=XDIS_2kt9ss9xytkqyzr4359iyexvi/l0, to TCM
          signal MESS_TCM_HS3_B6_AR: start 40, 8 bit, little-endian, data-type=c08_UInt_SNA_na, init-value=XDIS_2kt9ss9xytkqyzr4359iyexvi/l0, to TCM
          signal MESS_TCM_HS3_B7_AR: start 48, 8 bit, little-endian, data-type=c08_UInt_SNA_na, init-value=XDIS_2kt9ss9xytkqyzr4359iyexvi/l0, to TCM
          signal MESS_TCM_HS3_B8_AR: start 56, 8 bit, little-endian, data-type=c08_UInt_SNA_na, init-value=XDIS_2kt9ss9xytkqyzr4359iyexvi/l0, to TCM
          signal Mess_TCM_HS3_AR_4inwpjw806k3gbdnjph7rqf10: little-endian, system-signal=[MESS_TCM_HS3_B1_AR, MESS_TCM_HS3_B2_AR, MESS_TCM_HS3_B3_AR, MESS_TCM_HS3_B4_AR, MESS_TCM_HS3_B5_AR, MESS_TCM_HS3_B6_AR, MESS_TCM_HS3_B7_AR, MESS_TCM_HS3_B8_AR], transfer-property=TRIGGERED, to TCM  # Messdaten (degraded) / Measurement data (degraded)
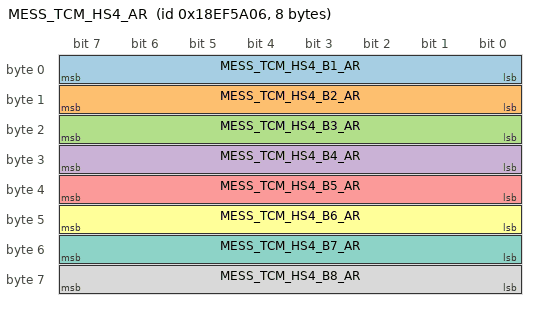
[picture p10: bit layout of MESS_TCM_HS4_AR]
      frame MESS_TCM_HS4_AR: id 0x18EF5A06, to TCM, frame-length=8, can-addressing-mode=EXTENDED  # TCM_HS4_AR
        pdu MESS_TCM_HS4_AR: length=64, unused-bit-pattern=0, event-controlled-timing=number-of-repeats=0, minimum-delay=0.0050
          signal MESS_TCM_HS4_B1_AR: start 0, 8 bit, little-endian, data-type=c08_UInt_SNA_na, init-value=XDIS_2kt9ss9xytkqyzr4359iyexvi/l0, to TCM
          signal MESS_TCM_HS4_B2_AR: start 8, 8 bit, little-endian, data-type=c08_UInt_SNA_na, init-value=XDIS_2kt9ss9xytkqyzr4359iyexvi/l0, to TCM
          signal MESS_TCM_HS4_B3_AR: start 16, 8 bit, little-endian, data-type=c08_UInt_SNA_na, init-value=XDIS_2kt9ss9xytkqyzr4359iyexvi/l0, to TCM
          signal MESS_TCM_HS4_B4_AR: start 24, 8 bit, little-endian, data-type=c08_UInt_SNA_na, init-value=XDIS_2kt9ss9xytkqyzr4359iyexvi/l0, to TCM
          signal MESS_TCM_HS4_B5_AR: start 32, 8 bit, little-endian, data-type=c08_UInt_SNA_na, init-value=XDIS_2kt9ss9xytkqyzr4359iyexvi/l0, to TCM
          signal MESS_TCM_HS4_B6_AR: start 40, 8 bit, little-endian, data-type=c08_UInt_SNA_na, init-value=XDIS_2kt9ss9xytkqyzr4359iyexvi/l0, to TCM
          signal MESS_TCM_HS4_B7_AR: start 48, 8 bit, little-endian, data-type=c08_UInt_SNA_na, init-value=XDIS_2kt9ss9xytkqyzr4359iyexvi/l0, to TCM
          signal MESS_TCM_HS4_B8_AR: start 56, 8 bit, little-endian, data-type=c08_UInt_SNA_na, init-value=XDIS_2kt9ss9xytkqyzr4359iyexvi/l0, to TCM
          signal Mess_TCM_HS4_AR_evfdhru5bsxezwntb7pz0kz0s: little-endian, system-signal=[MESS_TCM_HS4_B1_AR, MESS_TCM_HS4_B2_AR, MESS_TCM_HS4_B3_AR, MESS_TCM_HS4_B4_AR, MESS_TCM_HS4_B5_AR, MESS_TCM_HS4_B6_AR, MESS_TCM_HS4_B7_AR, MESS_TCM_HS4_B8_AR], transfer-property=TRIGGERED, to TCM  # Messdaten (degraded) / Measurement data (degraded)
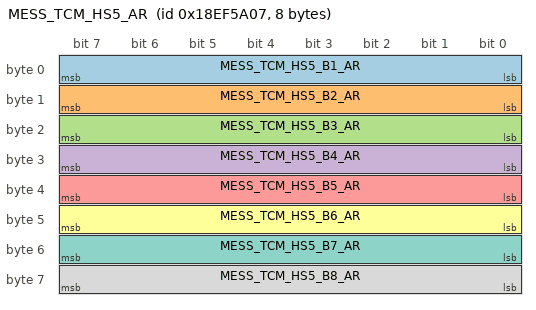
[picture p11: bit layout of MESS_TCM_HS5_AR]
      frame MESS_TCM_HS5_AR: id 0x18EF5A07, to TCM, frame-length=8, can-addressing-mode=EXTENDED  # TCM_HS5_AR
        pdu MESS_TCM_HS5_AR: length=64, unused-bit-pattern=0, event-controlled-timing=number-of-repeats=0, minimum-delay=0.0050
          signal MESS_TCM_HS5_B1_AR: start 0, 8 bit, little-endian, data-type=c08_UInt_SNA_na, init-value=XDIS_2kt9ss9xytkqyzr4359iyexvi/l0, to TCM
          signal MESS_TCM_HS5_B2_AR: start 8, 8 bit, little-endian, data-type=c08_UInt_SNA_na, init-value=XDIS_2kt9ss9xytkqyzr4359iyexvi/l0, to TCM
          signal MESS_TCM_HS5_B3_AR: start 16, 8 bit, little-endian, data-type=c08_UInt_SNA_na, init-value=XDIS_2kt9ss9xytkqyzr4359iyexvi/l0, to TCM
          signal MESS_TCM_HS5_B4_AR: start 24, 8 bit, little-endian, data-type=c08_UInt_SNA_na, init-value=XDIS_2kt9ss9xytkqyzr4359iyexvi/l0, to TCM
          signal MESS_TCM_HS5_B5_AR: start 32, 8 bit, little-endian, data-type=c08_UInt_SNA_na, init-value=XDIS_2kt9ss9xytkqyzr4359iyexvi/l0, to TCM
          signal MESS_TCM_HS5_B6_AR: start 40, 8 bit, little-endian, data-type=c08_UInt_SNA_na, init-value=XDIS_2kt9ss9xytkqyzr4359iyexvi/l0, to TCM
          signal MESS_TCM_HS5_B7_AR: start 48, 8 bit, little-endian, data-type=c08_UInt_SNA_na, init-value=XDIS_2kt9ss9xytkqyzr4359iyexvi/l0, to TCM
          signal MESS_TCM_HS5_B8_AR: start 56, 8 bit, little-endian, data-type=c08_UInt_SNA_na, init-value=XDIS_2kt9ss9xytkqyzr4359iyexvi/l0, to TCM
          signal Mess_TCM_HS5_AR_3ytjcfdv9pweydld67zsc9n63: little-endian, system-signal=[MESS_TCM_HS5_B1_AR, MESS_TCM_HS5_B2_AR, MESS_TCM_HS5_B3_AR, MESS_TCM_HS5_B4_AR, MESS_TCM_HS5_B5_AR, MESS_TCM_HS5_B6_AR, MESS_TCM_HS5_B7_AR, MESS_TCM_HS5_B8_AR], transfer-property=TRIGGERED, to TCM  # Messdaten (degraded) / Measurement data (degraded)
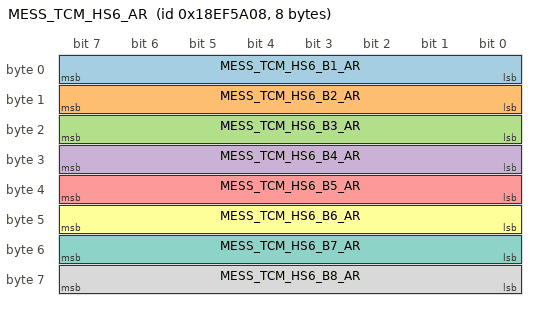
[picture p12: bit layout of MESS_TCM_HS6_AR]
      frame MESS_TCM_HS6_AR: id 0x18EF5A08, to TCM, frame-length=8, can-addressing-mode=EXTENDED  # TCM_HS6_AR
        pdu MESS_TCM_HS6_AR: length=64, unused-bit-pattern=0, event-controlled-timing=number-of-repeats=0, minimum-delay=0.0050
          signal MESS_TCM_HS6_B1_AR: start 0, 8 bit, little-endian, data-type=c08_UInt_SNA_na, init-value=XDIS_2kt9ss9xytkqyzr4359iyexvi/l0, to TCM
          signal MESS_TCM_HS6_B2_AR: start 8, 8 bit, little-endian, data-type=c08_UInt_SNA_na, init-value=XDIS_2kt9ss9xytkqyzr4359iyexvi/l0, to TCM
          signal MESS_TCM_HS6_B3_AR: start 16, 8 bit, little-endian, data-type=c08_UInt_SNA_na, init-value=XDIS_2kt9ss9xytkqyzr4359iyexvi/l0, to TCM
          signal MESS_TCM_HS6_B4_AR: start 24, 8 bit, little-endian, data-type=c08_UInt_SNA_na, init-value=XDIS_2kt9ss9xytkqyzr4359iyexvi/l0, to TCM
          signal MESS_TCM_HS6_B5_AR: start 32, 8 bit, little-endian, data-type=c08_UInt_SNA_na, init-value=XDIS_2kt9ss9xytkqyzr4359iyexvi/l0, to TCM
          signal MESS_TCM_HS6_B6_AR: start 40, 8 bit, little-endian, data-type=c08_UInt_SNA_na, init-value=XDIS_2kt9ss9xytkqyzr4359iyexvi/l0, to TCM
          signal MESS_TCM_HS6_B7_AR: start 48, 8 bit, little-endian, data-type=c08_UInt_SNA_na, init-value=XDIS_2kt9ss9xytkqyzr4359iyexvi/l0, to TCM
          signal MESS_TCM_HS6_B8_AR: start 56, 8 bit, little-endian, data-type=c08_UInt_SNA_na, init-value=XDIS_2kt9ss9xytkqyzr4359iyexvi/l0, to TCM
          signal Mess_TCM_HS6_AR_3s9ru3zfu2enkfu9f6dni9y9y: little-endian, system-signal=[MESS_TCM_HS6_B1_AR, MESS_TCM_HS6_B2_AR, MESS_TCM_HS6_B3_AR, MESS_TCM_HS6_B4_AR, MESS_TCM_HS6_B5_AR, MESS_TCM_HS6_B6_AR, MESS_TCM_HS6_B7_AR, MESS_TCM_HS6_B8_AR], transfer-property=TRIGGERED, to TCM  # Messdaten (degraded) / Measurement data (degraded)
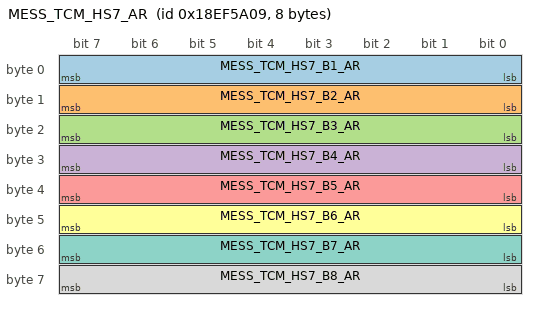
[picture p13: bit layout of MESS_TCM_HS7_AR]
      frame MESS_TCM_HS7_AR: id 0x18EF5A09, to TCM, frame-length=8, can-addressing-mode=EXTENDED  # TCM_HS7_AR
        pdu MESS_TCM_HS7_AR: length=64, unused-bit-pattern=0, event-controlled-timing=number-of-repeats=0, minimum-delay=0.0050
          signal MESS_TCM_HS7_B1_AR: start 0, 8 bit, little-endian, data-type=c08_UInt_SNA_na, init-value=XDIS_2kt9ss9xytkqyzr4359iyexvi/l0, to TCM
          signal MESS_TCM_HS7_B2_AR: start 8, 8 bit, little-endian, data-type=c08_UInt_SNA_na, init-value=XDIS_2kt9ss9xytkqyzr4359iyexvi/l0, to TCM
          signal MESS_TCM_HS7_B3_AR: start 16, 8 bit, little-endian, data-type=c08_UInt_SNA_na, init-value=XDIS_2kt9ss9xytkqyzr4359iyexvi/l0, to TCM
          signal MESS_TCM_HS7_B4_AR: start 24, 8 bit, little-endian, data-type=c08_UInt_SNA_na, init-value=XDIS_2kt9ss9xytkqyzr4359iyexvi/l0, to TCM
          signal MESS_TCM_HS7_B5_AR: start 32, 8 bit, little-endian, data-type=c08_UInt_SNA_na, init-value=XDIS_2kt9ss9xytkqyzr4359iyexvi/l0, to TCM
          signal MESS_TCM_HS7_B6_AR: start 40, 8 bit, little-endian, data-type=c08_UInt_SNA_na, init-value=XDIS_2kt9ss9xytkqyzr4359iyexvi/l0, to TCM
          signal MESS_TCM_HS7_B7_AR: start 48, 8 bit, little-endian, data-type=c08_UInt_SNA_na, init-value=XDIS_2kt9ss9xytkqyzr4359iyexvi/l0, to TCM
          signal MESS_TCM_HS7_B8_AR: start 56, 8 bit, little-endian, data-type=c08_UInt_SNA_na, init-value=XDIS_2kt9ss9xytkqyzr4359iyexvi/l0, to TCM
          signal Mess_TCM_HS7_AR_3mznt49qdhynqladaleqa672k: little-endian, system-signal=[MESS_TCM_HS7_B1_AR, MESS_TCM_HS7_B2_AR, MESS_TCM_HS7_B3_AR, MESS_TCM_HS7_B4_AR, MESS_TCM_HS7_B5_AR, MESS_TCM_HS7_B6_AR, MESS_TCM_HS7_B7_AR, MESS_TCM_HS7_B8_AR], transfer-property=TRIGGERED, to TCM  # Messdaten (degraded) / Measurement data (degraded)
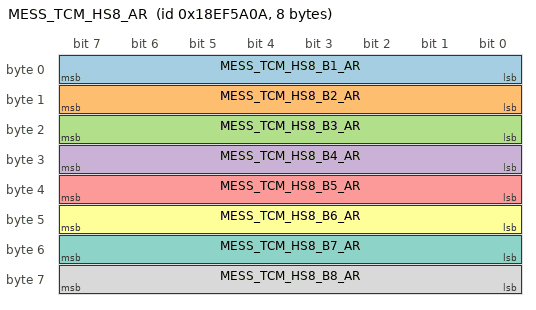
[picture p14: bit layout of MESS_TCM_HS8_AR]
      frame MESS_TCM_HS8_AR: id 0x18EF5A0A, to TCM, frame-length=8, can-addressing-mode=EXTENDED  # TCM_HS8_AR
        pdu MESS_TCM_HS8_AR: length=64, unused-bit-pattern=0, event-controlled-timing=number-of-repeats=0, minimum-delay=0.0050
          signal MESS_TCM_HS8_B1_AR: start 0, 8 bit, little-endian, data-type=c08_UInt_SNA_na, init-value=XDIS_2kt9ss9xytkqyzr4359iyexvi/l0, to TCM
          signal MESS_TCM_HS8_B2_AR: start 8, 8 bit, little-endian, data-type=c08_UInt_SNA_na, init-value=XDIS_2kt9ss9xytkqyzr4359iyexvi/l0, to TCM
          signal MESS_TCM_HS8_B3_AR: start 16, 8 bit, little-endian, data-type=c08_UInt_SNA_na, init-value=XDIS_2kt9ss9xytkqyzr4359iyexvi/l0, to TCM
          signal MESS_TCM_HS8_B4_AR: start 24, 8 bit, little-endian, data-type=c08_UInt_SNA_na, init-value=XDIS_2kt9ss9xytkqyzr4359iyexvi/l0, to TCM
          signal MESS_TCM_HS8_B5_AR: start 32, 8 bit, little-endian, data-type=c08_UInt_SNA_na, init-value=XDIS_2kt9ss9xytkqyzr4359iyexvi/l0, to TCM
          signal MESS_TCM_HS8_B6_AR: start 40, 8 bit, little-endian, data-type=c08_UInt_SNA_na, init-value=XDIS_2kt9ss9xytkqyzr4359iyexvi/l0, to TCM
          signal MESS_TCM_HS8_B7_AR: start 48, 8 bit, little-endian, data-type=c08_UInt_SNA_na, init-value=XDIS_2kt9ss9xytkqyzr4359iyexvi/l0, to TCM
          signal MESS_TCM_HS8_B8_AR: start 56, 8 bit, little-endian, data-type=c08_UInt_SNA_na, init-value=XDIS_2kt9ss9xytkqyzr4359iyexvi/l0, to TCM
          signal Mess_TCM_HS8_AR_c04hs7230v0uvdfftuf8jh4ro: little-endian, system-signal=[MESS_TCM_HS8_B1_AR, MESS_TCM_HS8_B2_AR, MESS_TCM_HS8_B3_AR, MESS_TCM_HS8_B4_AR, MESS_TCM_HS8_B5_AR, MESS_TCM_HS8_B6_AR, MESS_TCM_HS8_B7_AR, MESS_TCM_HS8_B8_AR], transfer-property=TRIGGERED, to TCM  # Messdaten (degraded) / Measurement data (degraded)
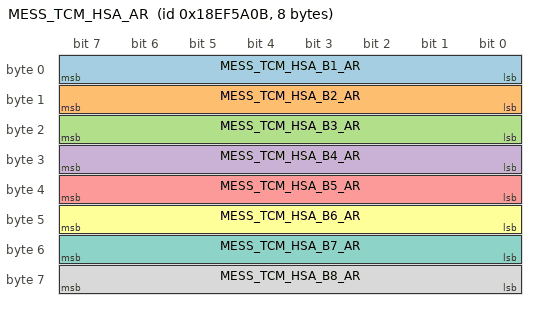
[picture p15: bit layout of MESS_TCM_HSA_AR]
      frame MESS_TCM_HSA_AR: id 0x18EF5A0B, from TCM, frame-length=8, can-addressing-mode=EXTENDED  # TCM_HSA_AR
        pdu MESS_TCM_HSA_AR: length=64, unused-bit-pattern=0, event-controlled-timing=number-of-repeats=0, minimum-delay=0.0050
          signal MESS_TCM_HSA_B1_AR: start 0, 8 bit, little-endian, data-type=c08_UInt_SNA_na, init-value=XDIS_2kt9ss9xytkqyzr4359iyexvi/l0
          signal MESS_TCM_HSA_B2_AR: start 8, 8 bit, little-endian, data-type=c08_UInt_SNA_na, init-value=XDIS_2kt9ss9xytkqyzr4359iyexvi/l0
          signal MESS_TCM_HSA_B3_AR: start 16, 8 bit, little-endian, data-type=c08_UInt_SNA_na, init-value=XDIS_2kt9ss9xytkqyzr4359iyexvi/l0
          signal MESS_TCM_HSA_B4_AR: start 24, 8 bit, little-endian, data-type=c08_UInt_SNA_na, init-value=XDIS_2kt9ss9xytkqyzr4359iyexvi/l0
          signal MESS_TCM_HSA_B5_AR: start 32, 8 bit, little-endian, data-type=c08_UInt_SNA_na, init-value=XDIS_2kt9ss9xytkqyzr4359iyexvi/l0
          signal MESS_TCM_HSA_B6_AR: start 40, 8 bit, little-endian, data-type=c08_UInt_SNA_na, init-value=XDIS_2kt9ss9xytkqyzr4359iyexvi/l0
          signal MESS_TCM_HSA_B7_AR: start 48, 8 bit, little-endian, data-type=c08_UInt_SNA_na, init-value=XDIS_2kt9ss9xytkqyzr4359iyexvi/l0
          signal MESS_TCM_HSA_B8_AR: start 56, 8 bit, little-endian, data-type=c08_UInt_SNA_na, init-value=XDIS_2kt9ss9xytkqyzr4359iyexvi/l0
          signal Mess_TCM_HSA_AR_4isll7yxbbz5hw57ubwbk9twa: little-endian, system-signal=[MESS_TCM_HSA_B1_AR, MESS_TCM_HSA_B2_AR, MESS_TCM_HSA_B3_AR, MESS_TCM_HSA_B4_AR, MESS_TCM_HSA_B5_AR, MESS_TCM_HSA_B6_AR, MESS_TCM_HSA_B7_AR, MESS_TCM_HSA_B8_AR], transfer-property=TRIGGERED  # Messdaten (degraded) / Measurement data (degraded)
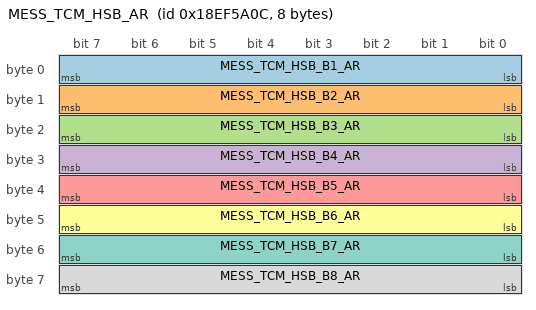
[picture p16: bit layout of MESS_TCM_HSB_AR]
      frame MESS_TCM_HSB_AR: id 0x18EF5A0C, from TCM, frame-length=8, can-addressing-mode=EXTENDED  # TCM_HSB_AR
        pdu MESS_TCM_HSB_AR: length=64, unused-bit-pattern=0, event-controlled-timing=number-of-repeats=0, minimum-delay=0.0050
          signal MESS_TCM_HSB_B1_AR: start 0, 8 bit, little-endian, data-type=c08_UInt_SNA_na, init-value=XDIS_2kt9ss9xytkqyzr4359iyexvi/l0
          signal MESS_TCM_HSB_B2_AR: start 8, 8 bit, little-endian, data-type=c08_UInt_SNA_na, init-value=XDIS_2kt9ss9xytkqyzr4359iyexvi/l0
          signal MESS_TCM_HSB_B3_AR: start 16, 8 bit, little-endian, data-type=c08_UInt_SNA_na, init-value=XDIS_2kt9ss9xytkqyzr4359iyexvi/l0
          signal MESS_TCM_HSB_B4_AR: start 24, 8 bit, little-endian, data-type=c08_UInt_SNA_na, init-value=XDIS_2kt9ss9xytkqyzr4359iyexvi/l0
          signal MESS_TCM_HSB_B5_AR: start 32, 8 bit, little-endian, data-type=c08_UInt_SNA_na, init-value=XDIS_2kt9ss9xytkqyzr4359iyexvi/l0
          signal MESS_TCM_HSB_B6_AR: start 40, 8 bit, little-endian, data-type=c08_UInt_SNA_na, init-value=XDIS_2kt9ss9xytkqyzr4359iyexvi/l0
          signal MESS_TCM_HSB_B7_AR: start 48, 8 bit, little-endian, data-type=c08_UInt_SNA_na, init-value=XDIS_2kt9ss9xytkqyzr4359iyexvi/l0
          signal MESS_TCM_HSB_B8_AR: start 56, 8 bit, little-endian, data-type=c08_UInt_SNA_na, init-value=XDIS_2kt9ss9xytkqyzr4359iyexvi/l0
          signal Mess_TCM_HSB_AR_2k40btgzi6zdukcyrsofq65p8: little-endian, system-signal=[MESS_TCM_HSB_B1_AR, MESS_TCM_HSB_B2_AR, MESS_TCM_HSB_B3_AR, MESS_TCM_HSB_B4_AR, MESS_TCM_HSB_B5_AR, MESS_TCM_HSB_B6_AR, MESS_TCM_HSB_B7_AR, MESS_TCM_HSB_B8_AR], transfer-property=TRIGGERED  # Messdaten (degraded) / Measurement data (degraded)
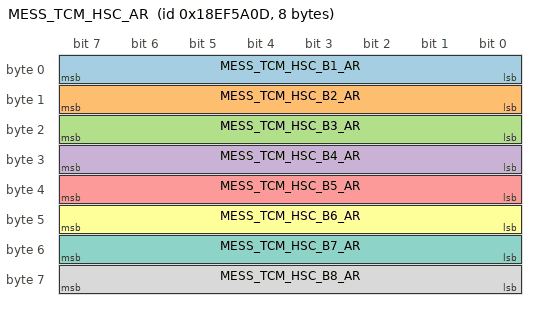
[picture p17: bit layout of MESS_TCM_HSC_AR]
      frame MESS_TCM_HSC_AR: id 0x18EF5A0D, from TCM, frame-length=8, can-addressing-mode=EXTENDED  # TCM_HSC_AR
        pdu MESS_TCM_HSC_AR: length=64, unused-bit-pattern=0, event-controlled-timing=number-of-repeats=0, minimum-delay=0.0050
          signal MESS_TCM_HSC_B1_AR: start 0, 8 bit, little-endian, data-type=c08_UInt_SNA_na, init-value=XDIS_2kt9ss9xytkqyzr4359iyexvi/l0
          signal MESS_TCM_HSC_B2_AR: start 8, 8 bit, little-endian, data-type=c08_UInt_SNA_na, init-value=XDIS_2kt9ss9xytkqyzr4359iyexvi/l0
          signal MESS_TCM_HSC_B3_AR: start 16, 8 bit, little-endian, data-type=c08_UInt_SNA_na, init-value=XDIS_2kt9ss9xytkqyzr4359iyexvi/l0
          signal MESS_TCM_HSC_B4_AR: start 24, 8 bit, little-endian, data-type=c08_UInt_SNA_na, init-value=XDIS_2kt9ss9xytkqyzr4359iyexvi/l0
          signal MESS_TCM_HSC_B5_AR: start 32, 8 bit, little-endian, data-type=c08_UInt_SNA_na, init-value=XDIS_2kt9ss9xytkqyzr4359iyexvi/l0
          signal MESS_TCM_HSC_B6_AR: start 40, 8 bit, little-endian, data-type=c08_UInt_SNA_na, init-value=XDIS_2kt9ss9xytkqyzr4359iyexvi/l0
          signal MESS_TCM_HSC_B7_AR: start 48, 8 bit, little-endian, data-type=c08_UInt_SNA_na, init-value=XDIS_2kt9ss9xytkqyzr4359iyexvi/l0
          signal MESS_TCM_HSC_B8_AR: start 56, 8 bit, little-endian, data-type=c08_UInt_SNA_na, init-value=XDIS_2kt9ss9xytkqyzr4359iyexvi/l0
          signal Mess_TCM_HSC_AR_ab1rnn2g0gzay8mfvuwu5tgn0: little-endian, system-signal=[MESS_TCM_HSC_B1_AR, MESS_TCM_HSC_B2_AR, MESS_TCM_HSC_B3_AR, MESS_TCM_HSC_B4_AR, MESS_TCM_HSC_B5_AR, MESS_TCM_HSC_B6_AR, MESS_TCM_HSC_B7_AR, MESS_TCM_HSC_B8_AR], transfer-property=TRIGGERED  # Messdaten (degraded) / Measurement data (degraded)
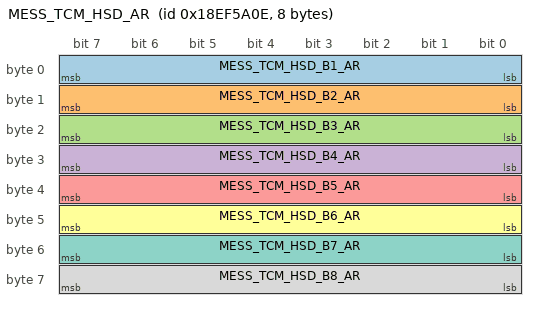
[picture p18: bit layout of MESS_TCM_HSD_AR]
      frame MESS_TCM_HSD_AR: id 0x18EF5A0E, from TCM, frame-length=8, can-addressing-mode=EXTENDED  # TCM_HSD_AR
        pdu MESS_TCM_HSD_AR: length=64, unused-bit-pattern=0, event-controlled-timing=number-of-repeats=0, minimum-delay=0.0050
          signal MESS_TCM_HSD_B1_AR: start 0, 8 bit, little-endian, data-type=c08_UInt_SNA_na, init-value=XDIS_2kt9ss9xytkqyzr4359iyexvi/l0
          signal MESS_TCM_HSD_B2_AR: start 8, 8 bit, little-endian, data-type=c08_UInt_SNA_na, init-value=XDIS_2kt9ss9xytkqyzr4359iyexvi/l0
          signal MESS_TCM_HSD_B3_AR: start 16, 8 bit, little-endian, data-type=c08_UInt_SNA_na, init-value=XDIS_2kt9ss9xytkqyzr4359iyexvi/l0
          signal MESS_TCM_HSD_B4_AR: start 24, 8 bit, little-endian, data-type=c08_UInt_SNA_na, init-value=XDIS_2kt9ss9xytkqyzr4359iyexvi/l0
          signal MESS_TCM_HSD_B5_AR: start 32, 8 bit, little-endian, data-type=c08_UInt_SNA_na, init-value=XDIS_2kt9ss9xytkqyzr4359iyexvi/l0
          signal MESS_TCM_HSD_B6_AR: start 40, 8 bit, little-endian, data-type=c08_UInt_SNA_na, init-value=XDIS_2kt9ss9xytkqyzr4359iyexvi/l0
          signal MESS_TCM_HSD_B7_AR: start 48, 8 bit, little-endian, data-type=c08_UInt_SNA_na, init-value=XDIS_2kt9ss9xytkqyzr4359iyexvi/l0
          signal MESS_TCM_HSD_B8_AR: start 56, 8 bit, little-endian, data-type=c08_UInt_SNA_na, init-value=XDIS_2kt9ss9xytkqyzr4359iyexvi/l0
          signal Mess_TCM_HSD_AR_7f2pb1wttr06fpeiwh38rx42y: little-endian, system-signal=[MESS_TCM_HSD_B1_AR, MESS_TCM_HSD_B2_AR, MESS_TCM_HSD_B3_AR, MESS_TCM_HSD_B4_AR, MESS_TCM_HSD_B5_AR, MESS_TCM_HSD_B6_AR, MESS_TCM_HSD_B7_AR, MESS_TCM_HSD_B8_AR], transfer-property=TRIGGERED  # Messdaten (degraded) / Measurement data (degraded)
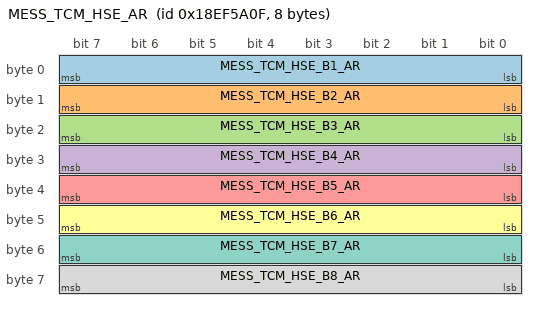
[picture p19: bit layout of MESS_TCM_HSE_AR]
      frame MESS_TCM_HSE_AR: id 0x18EF5A0F, from TCM, frame-length=8, can-addressing-mode=EXTENDED  # TCM_HSE_AR
        pdu MESS_TCM_HSE_AR: length=64, unused-bit-pattern=0, event-controlled-timing=number-of-repeats=0, minimum-delay=0.0050
          signal MESS_TCM_HSE_B1_AR: start 0, 8 bit, little-endian, data-type=c08_UInt_SNA_na, init-value=XDIS_2kt9ss9xytkqyzr4359iyexvi/l0
          signal MESS_TCM_HSE_B2_AR: start 8, 8 bit, little-endian, data-type=c08_UInt_SNA_na, init-value=XDIS_2kt9ss9xytkqyzr4359iyexvi/l0
          signal MESS_TCM_HSE_B3_AR: start 16, 8 bit, little-endian, data-type=c08_UInt_SNA_na, init-value=XDIS_2kt9ss9xytkqyzr4359iyexvi/l0
          signal MESS_TCM_HSE_B4_AR: start 24, 8 bit, little-endian, data-type=c08_UInt_SNA_na, init-value=XDIS_2kt9ss9xytkqyzr4359iyexvi/l0
          signal MESS_TCM_HSE_B5_AR: start 32, 8 bit, little-endian, data-type=c08_UInt_SNA_na, init-value=XDIS_2kt9ss9xytkqyzr4359iyexvi/l0
          signal MESS_TCM_HSE_B6_AR: start 40, 8 bit, little-endian, data-type=c08_UInt_SNA_na, init-value=XDIS_2kt9ss9xytkqyzr4359iyexvi/l0
          signal MESS_TCM_HSE_B7_AR: start 48, 8 bit, little-endian, data-type=c08_UInt_SNA_na, init-value=XDIS_2kt9ss9xytkqyzr4359iyexvi/l0
          signal MESS_TCM_HSE_B8_AR: start 56, 8 bit, little-endian, data-type=c08_UInt_SNA_na, init-value=XDIS_2kt9ss9xytkqyzr4359iyexvi/l0
          signal Mess_TCM_HSE_AR_2gcwj04mj6g9zu6m75pbzii7q: little-endian, system-signal=[MESS_TCM_HSE_B1_AR, MESS_TCM_HSE_B2_AR, MESS_TCM_HSE_B3_AR, MESS_TCM_HSE_B4_AR, MESS_TCM_HSE_B5_AR, MESS_TCM_HSE_B6_AR, MESS_TCM_HSE_B7_AR, MESS_TCM_HSE_B8_AR], transfer-property=TRIGGERED  # Messdaten (degraded) / Measurement data (degraded)
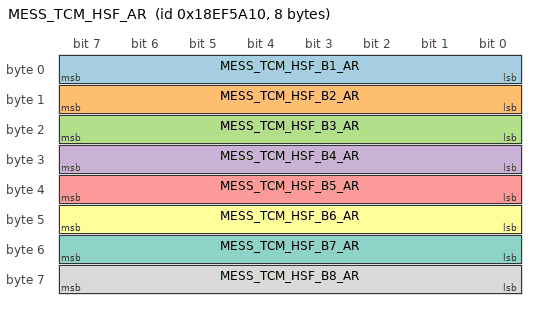
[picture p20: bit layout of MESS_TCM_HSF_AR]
      frame MESS_TCM_HSF_AR: id 0x18EF5A10, from TCM, frame-length=8, can-addressing-mode=EXTENDED  # TCM_HSF_AR
        pdu MESS_TCM_HSF_AR: length=64, unused-bit-pattern=0, event-controlled-timing=number-of-repeats=0, minimum-delay=0.0050
          signal MESS_TCM_HSF_B1_AR: start 0, 8 bit, little-endian, data-type=c08_UInt_SNA_na, init-value=XDIS_2kt9ss9xytkqyzr4359iyexvi/l0
          signal MESS_TCM_HSF_B2_AR: start 8, 8 bit, little-endian, data-type=c08_UInt_SNA_na, init-value=XDIS_2kt9ss9xytkqyzr4359iyexvi/l0
          signal MESS_TCM_HSF_B3_AR: start 16, 8 bit, little-endian, data-type=c08_UInt_SNA_na, init-value=XDIS_2kt9ss9xytkqyzr4359iyexvi/l0
          signal MESS_TCM_HSF_B4_AR: start 24, 8 bit, little-endian, data-type=c08_UInt_SNA_na, init-value=XDIS_2kt9ss9xytkqyzr4359iyexvi/l0
          signal MESS_TCM_HSF_B5_AR: start 32, 8 bit, little-endian, data-type=c08_UInt_SNA_na, init-value=XDIS_2kt9ss9xytkqyzr4359iyexvi/l0
          signal MESS_TCM_HSF_B6_AR: start 40, 8 bit, little-endian, data-type=c08_UInt_SNA_na, init-value=XDIS_2kt9ss9xytkqyzr4359iyexvi/l0
          signal MESS_TCM_HSF_B7_AR: start 48, 8 bit, little-endian, data-type=c08_UInt_SNA_na, init-value=XDIS_2kt9ss9xytkqyzr4359iyexvi/l0
          signal MESS_TCM_HSF_B8_AR: start 56, 8 bit, little-endian, data-type=c08_UInt_SNA_na, init-value=XDIS_2kt9ss9xytkqyzr4359iyexvi/l0
          signal Mess_TCM_HSF_AR_5wh6a86cve3tu93yo0uv2x00u: little-endian, system-signal=[MESS_TCM_HSF_B1_AR, MESS_TCM_HSF_B2_AR, MESS_TCM_HSF_B3_AR, MESS_TCM_HSF_B4_AR, MESS_TCM_HSF_B5_AR, MESS_TCM_HSF_B6_AR, MESS_TCM_HSF_B7_AR, MESS_TCM_HSF_B8_AR], transfer-property=TRIGGERED  # Messdaten (degraded) / Measurement data (degraded)
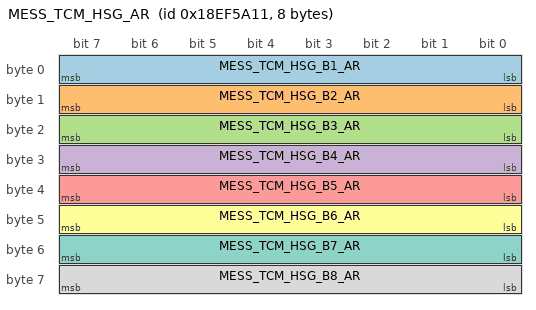
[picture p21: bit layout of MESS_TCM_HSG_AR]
      frame MESS_TCM_HSG_AR: id 0x18EF5A11, from TCM, frame-length=8, can-addressing-mode=EXTENDED  # TCM_HSG_AR
        pdu MESS_TCM_HSG_AR: length=64, unused-bit-pattern=0, event-controlled-timing=number-of-repeats=0, minimum-delay=0.0050
          signal MESS_TCM_HSG_B1_AR: start 0, 8 bit, little-endian, data-type=c08_UInt_SNA_na, init-value=XDIS_2kt9ss9xytkqyzr4359iyexvi/l0
          signal MESS_TCM_HSG_B2_AR: start 8, 8 bit, little-endian, data-type=c08_UInt_SNA_na, init-value=XDIS_2kt9ss9xytkqyzr4359iyexvi/l0
          signal MESS_TCM_HSG_B3_AR: start 16, 8 bit, little-endian, data-type=c08_UInt_SNA_na, init-value=XDIS_2kt9ss9xytkqyzr4359iyexvi/l0
          signal MESS_TCM_HSG_B4_AR: start 24, 8 bit, little-endian, data-type=c08_UInt_SNA_na, init-value=XDIS_2kt9ss9xytkqyzr4359iyexvi/l0
          signal MESS_TCM_HSG_B5_AR: start 32, 8 bit, little-endian, data-type=c08_UInt_SNA_na, init-value=XDIS_2kt9ss9xytkqyzr4359iyexvi/l0
          signal MESS_TCM_HSG_B6_AR: start 40, 8 bit, little-endian, data-type=c08_UInt_SNA_na, init-value=XDIS_2kt9ss9xytkqyzr4359iyexvi/l0
          signal MESS_TCM_HSG_B7_AR: start 48, 8 bit, little-endian, data-type=c08_UInt_SNA_na, init-value=XDIS_2kt9ss9xytkqyzr4359iyexvi/l0
          signal MESS_TCM_HSG_B8_AR: start 56, 8 bit, little-endian, data-type=c08_UInt_SNA_na, init-value=XDIS_2kt9ss9xytkqyzr4359iyexvi/l0
          signal Mess_TCM_HSG_AR_3y1jssa1j0apm73uro4je8765: little-endian, system-signal=[MESS_TCM_HSG_B1_AR, MESS_TCM_HSG_B2_AR, MESS_TCM_HSG_B3_AR, MESS_TCM_HSG_B4_AR, MESS_TCM_HSG_B5_AR, MESS_TCM_HSG_B6_AR, MESS_TCM_HSG_B7_AR, MESS_TCM_HSG_B8_AR], transfer-property=TRIGGERED  # Messdaten (degraded) / Measurement data (degraded)
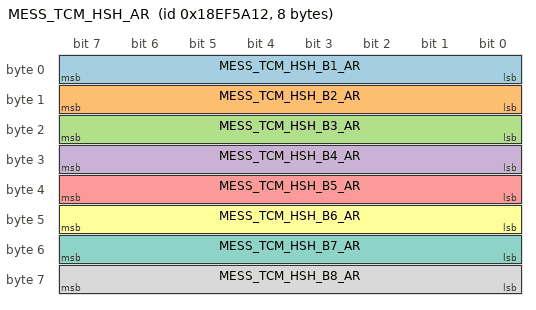
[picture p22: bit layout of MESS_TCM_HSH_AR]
      frame MESS_TCM_HSH_AR: id 0x18EF5A12, from TCM, frame-length=8, can-addressing-mode=EXTENDED  # TCM_HSH_AR
        pdu MESS_TCM_HSH_AR: length=64, unused-bit-pattern=0, event-controlled-timing=number-of-repeats=0, minimum-delay=0.0050
          signal MESS_TCM_HSH_B1_AR: start 0, 8 bit, little-endian, data-type=c08_UInt_SNA_na, init-value=XDIS_2kt9ss9xytkqyzr4359iyexvi/l0
          signal MESS_TCM_HSH_B2_AR: start 8, 8 bit, little-endian, data-type=c08_UInt_SNA_na, init-value=XDIS_2kt9ss9xytkqyzr4359iyexvi/l0
          signal MESS_TCM_HSH_B3_AR: start 16, 8 bit, little-endian, data-type=c08_UInt_SNA_na, init-value=XDIS_2kt9ss9xytkqyzr4359iyexvi/l0
          signal MESS_TCM_HSH_B4_AR: start 24, 8 bit, little-endian, data-type=c08_UInt_SNA_na, init-value=XDIS_2kt9ss9xytkqyzr4359iyexvi/l0
          signal MESS_TCM_HSH_B5_AR: start 32, 8 bit, little-endian, data-type=c08_UInt_SNA_na, init-value=XDIS_2kt9ss9xytkqyzr4359iyexvi/l0
          signal MESS_TCM_HSH_B6_AR: start 40, 8 bit, little-endian, data-type=c08_UInt_SNA_na, init-value=XDIS_2kt9ss9xytkqyzr4359iyexvi/l0
          signal MESS_TCM_HSH_B7_AR: start 48, 8 bit, little-endian, data-type=c08_UInt_SNA_na, init-value=XDIS_2kt9ss9xytkqyzr4359iyexvi/l0
          signal MESS_TCM_HSH_B8_AR: start 56, 8 bit, little-endian, data-type=c08_UInt_SNA_na, init-value=XDIS_2kt9ss9xytkqyzr4359iyexvi/l0
          signal Mess_TCM_HSH_AR_ayr108r4lfg8j9ixm2fzf87eh: little-endian, system-signal=[MESS_TCM_HSH_B1_AR, MESS_TCM_HSH_B2_AR, MESS_TCM_HSH_B3_AR, MESS_TCM_HSH_B4_AR, MESS_TCM_HSH_B5_AR, MESS_TCM_HSH_B6_AR, MESS_TCM_HSH_B7_AR, MESS_TCM_HSH_B8_AR], transfer-property=TRIGGERED  # Messdaten (degraded) / Measurement data (degraded)
      frame XCP_Rs_TCM2: id 0x18EF5A14, from TCM, frame-length=8, can-addressing-mode=EXTENDED
        user defined i pdu XCP_Rs_TCM2: length=64, unused-bit-pattern=0, cdd-type=XCP  # XCP-Anforderung / Extended calibration protocol response
      frame XCP_Rs_TCM3: id 0x18EF5A15, from TCM, frame-length=8, can-addressing-mode=EXTENDED
        user defined i pdu XCP_Rs_TCM3: length=64, unused-bit-pattern=0, cdd-type=XCP  # XCP-Anforderung / Extended calibration protocol response
      frame XCP_Rs_TCM4: id 0x18EF5A16, from TCM, frame-length=8, can-addressing-mode=EXTENDED
        user defined i pdu XCP_Rs_TCM4: length=64, unused-bit-pattern=0, cdd-type=XCP  # XCP-Anforderung / Extended calibration protocol response
      frame XCP_Rq_TCM2: id 0x18EF5A18, to TCM, frame-length=8, can-addressing-mode=EXTENDED
        user defined i pdu XCP_Rq_TCM2: length=64, unused-bit-pattern=0, cdd-type=XCP  # XCP-Anforderung / Extended calibration protocol request
      frame ROE_FSCM: id 0x18EF5C00, from FSCM, to CPC, frame-length=8, can-addressing-mode=EXTENDED  # RoE lite
        pdu ROE_FSCM: length=64, unused-bit-pattern=0, event-controlled-timing=number-of-repeats=0, minimum-delay=0.2  # RoE-lite / RoE lite
          signal ROE_DTC_FSCM: start 32, 24 bit, little-endian, data-type=c24_0_16777215_1_SNA_na, init-value=XDIS_d00a2pwsicon8afnf0ovtodtq/l0, to CPC  # Fehlercode RoE-lite / RoE lite diagnostic trouble code
          signal ROE_DTC_Stat_FSCM: start 56, 8 bit, little-endian, data-type=c08_0_255_1_SNA_na, init-value=XDIS_e83grhz0aqm1yaa82ns55ebek/l0, to CPC  # Fehlercode-Status RoE-lite / RoE lite diagnostic trouble code state
          signal ROE_Header_FSCM: start 0, 32 bit, little-endian, data-type=c32_0_4294967295_1_SNA_na, init-value=l940295, to CPC  # Header RoE-lite / RoE lite header
          signal ROE_FSCM_7tuz31puvlbck2wez2tozkmyn: little-endian, system-signal=[ROE_DTC_FSCM, ROE_DTC_Stat_FSCM, ROE_Header_FSCM], transfer-property=TRIGGERED, to CPC  # RoE-lite (degraded) / RoE lite (degraded)
      frame XCP_Rq_FSCM: id 0x18EF5C01, from CPC, to FSCM, frame-length=8, can-addressing-mode=EXTENDED
        user defined i pdu XCP_Rq_FSCM: length=64, unused-bit-pattern=0, cdd-type=XCP  # XCP-Anforderung / Extended calibration protocol request
      frame XCP_Rs_FSCM: id 0x18EF5C02, from FSCM, to CPC, frame-length=8, can-addressing-mode=EXTENDED
        user defined i pdu XCP_Rs_FSCM: length=64, unused-bit-pattern=0, cdd-type=XCP  # XCP-Anforderung / Extended calibration protocol response
      frame XCP_Rs_FSCM1: id 0x18EF5C03, from FSCM, to CPC, frame-length=8, can-addressing-mode=EXTENDED
        user defined i pdu XCP_Rs_FSCM01: length=64, unused-bit-pattern=0, cdd-type=XCP  # XCP-Anforderung / Extended calibration protocol response
      frame XCP_Rs_FSCM2: id 0x18EF5C04, from FSCM, to CPC, frame-length=8, can-addressing-mode=EXTENDED
        user defined i pdu XCP_Rs_FSCM02: length=64, unused-bit-pattern=0, cdd-type=XCP  # XCP-Anforderung / Extended calibration protocol response
      frame ROE_AWD: id 0x18EF5E00, to CPC, frame-length=8, can-addressing-mode=EXTENDED  # RoE lite
        pdu ROE_AWD: length=64, unused-bit-pattern=0, event-controlled-timing=number-of-repeats=0, minimum-delay=0.2  # RoE-lite / RoE lite
          signal ROE_DTC_AWD: start 32, 24 bit, little-endian, data-type=c24_0_16777215_1_SNA_na, init-value=XDIS_d00a2pwsicon8afnf0ovtodtq/l0, to CPC  # Fehlercode RoE-lite / RoE lite diagnostic trouble code
          signal ROE_DTC_Stat_AWD: start 56, 8 bit, little-endian, data-type=c08_0_255_1_SNA_na, init-value=XDIS_e83grhz0aqm1yaa82ns55ebek/l0, to CPC  # Fehlercode-Status RoE-lite / RoE lite diagnostic trouble code state
          signal ROE_Header_AWD: start 0, 32 bit, little-endian, data-type=c32_0_4294967295_1_SNA_na, init-value=l940295, to CPC  # Header RoE-lite / RoE lite header
          signal ROE_AWD_812ji4i2uikzhm20lz4b8lx9g: little-endian, system-signal=[ROE_DTC_AWD, ROE_DTC_Stat_AWD, ROE_Header_AWD], transfer-property=TRIGGERED, to CPC  # RoE-lite (degraded) / RoE lite (degraded)
      frame ROE_ISM: id 0x18EF5F00, from ISM, to CPC, frame-length=8, can-addressing-mode=EXTENDED  # RoE lite
        pdu ROE_ISM: length=64, unused-bit-pattern=0, event-controlled-timing=number-of-repeats=0, minimum-delay=0.2  # RoE-lite / RoE lite
          signal ROE_DTC_ISM: start 32, 24 bit, little-endian, data-type=c24_0_16777215_1_SNA_na, init-value=XDIS_d00a2pwsicon8afnf0ovtodtq/l0, to CPC  # Fehlercode RoE-lite / RoE lite diagnostic trouble code
          signal ROE_DTC_Stat_ISM: start 56, 8 bit, little-endian, data-type=c08_0_255_1_SNA_na, init-value=XDIS_e83grhz0aqm1yaa82ns55ebek/l0, to CPC  # Fehlercode-Status RoE-lite / RoE lite diagnostic trouble code state
          signal ROE_Header_ISM: start 0, 32 bit, little-endian, data-type=c32_0_4294967295_1_SNA_na, init-value=l940295, to CPC  # Header RoE-lite / RoE lite header
          signal ROE_ISM_4y9ojv7xq5khnsiewkqkkc4rx: little-endian, system-signal=[ROE_DTC_ISM, ROE_DTC_Stat_ISM, ROE_Header_ISM], transfer-property=TRIGGERED, to CPC  # RoE-lite (degraded) / RoE lite (degraded)
      frame XCP_Rq_ISM: id 0x18EF5F01, from CPC, to ISM, frame-length=8, can-addressing-mode=EXTENDED
        user defined i pdu XCP_Rq_ISM: length=64, unused-bit-pattern=0, cdd-type=XCP  # XCP-Anforderung / Extended calibration protocol request
      frame XCP_Rs_ISM: id 0x18EF5F02, from ISM, frame-length=8, can-addressing-mode=EXTENDED
        user defined i pdu XCP_Rs_ISM: length=64, unused-bit-pattern=0, cdd-type=XCP  # XCP-Anforderung / Extended calibration protocol response
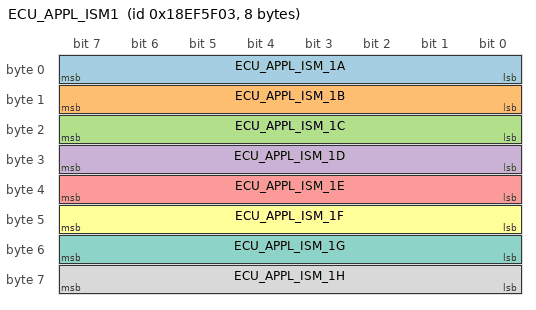
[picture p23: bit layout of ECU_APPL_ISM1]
      frame ECU_APPL_ISM1: id 0x18EF5F03, from ISM, frame-length=8, can-addressing-mode=EXTENDED  # Steuergerät zu Applikation / ECU to Application
        pdu ECU_APPL_ISM1: length=64, unused-bit-pattern=0, event-controlled-timing=number-of-repeats=0, minimum-delay=0.0050  # Steuergerät zu Applikation / ECU to Application
          signal ECU_APPL_ISM_1A: start 0, 8 bit, little-endian, data-type=c08_UInt_SNA_na, init-value=XDIS_2kt9ss9xytkqyzr4359iyexvi/l0  # Steuergerät zu Applikation / ECU to Application
          signal ECU_APPL_ISM_1B: start 8, 8 bit, little-endian, data-type=c08_UInt_SNA_na, init-value=XDIS_2kt9ss9xytkqyzr4359iyexvi/l0  # Steuergerät zu Applikation / ECU to Application
          signal ECU_APPL_ISM_1C: start 16, 8 bit, little-endian, data-type=c08_UInt_SNA_na, init-value=XDIS_2kt9ss9xytkqyzr4359iyexvi/l0  # Steuergerät zu Applikation / ECU to Application
          signal ECU_APPL_ISM_1D: start 24, 8 bit, little-endian, data-type=c08_UInt_SNA_na, init-value=XDIS_2kt9ss9xytkqyzr4359iyexvi/l0  # Steuergerät zu Applikation / ECU to Application
          signal ECU_APPL_ISM_1E: start 32, 8 bit, little-endian, data-type=c08_UInt_SNA_na, init-value=XDIS_2kt9ss9xytkqyzr4359iyexvi/l0  # Steuergerät zu Applikation / ECU to Application
          signal ECU_APPL_ISM_1F: start 40, 8 bit, little-endian, data-type=c08_UInt_SNA_na, init-value=XDIS_2kt9ss9xytkqyzr4359iyexvi/l0  # Steuergerät zu Applikation / ECU to Application
          signal ECU_APPL_ISM_1G: start 48, 8 bit, little-endian, data-type=c08_UInt_SNA_na, init-value=XDIS_2kt9ss9xytkqyzr4359iyexvi/l0  # Steuergerät zu Applikation / ECU to Application
          signal ECU_APPL_ISM_1H: start 56, 8 bit, little-endian, data-type=c08_UInt_SNA_na, init-value=XDIS_2kt9ss9xytkqyzr4359iyexvi/l0  # Steuergerät zu Applikation / ECU to Application
          signal ECU_APPL_ISM1_1g7qtpxtgfi7n74g8lc02q12d: little-endian, system-signal=[ECU_APPL_ISM_1A, ECU_APPL_ISM_1B, ECU_APPL_ISM_1C, ECU_APPL_ISM_1D, ECU_APPL_ISM_1E, ECU_APPL_ISM_1F, ECU_APPL_ISM_1G, ECU_APPL_ISM_1H], transfer-property=TRIGGERED  # Steuergerät zu Applikation (degraded) / ECU to Application (degraded)
      frame ECU_APPL_ISM2: id 0x18EF5F04, from ISM, frame-length=8, can-addressing-mode=EXTENDED  # Steuergerät zu Applikation / ECU to Application
        pdu ECU_APPL_ISM2: length=64, unused-bit-pattern=0, event-controlled-timing=number-of-repeats=0, minimum-delay=0.0050  # Steuergerät zu Applikation / ECU to Application
          signal ECU_APPL_ISM_2A: start 0, 8 bit, little-endian, data-type=c08_UInt_SNA_na, init-value=XDIS_2kt9ss9xytkqyzr4359iyexvi/l0  # Steuergerät zu Applikation / ECU to Application
          signal ECU_APPL_ISM_2B: start 8, 8 bit, little-endian, data-type=c08_UInt_SNA_na, init-value=XDIS_2kt9ss9xytkqyzr4359iyexvi/l0  # Steuergerät zu Applikation / ECU to Application
          signal ECU_APPL_ISM_2C: start 16, 8 bit, little-endian, data-type=c08_UInt_SNA_na, init-value=XDIS_2kt9ss9xytkqyzr4359iyexvi/l0  # Steuergerät zu Applikation / ECU to Application
          signal ECU_APPL_ISM_2D: start 24, 8 bit, little-endian, data-type=c08_UInt_SNA_na, init-value=XDIS_2kt9ss9xytkqyzr4359iyexvi/l0  # Steuergerät zu Applikation / ECU to Application
          signal ECU_APPL_ISM_2E: start 32, 8 bit, little-endian, data-type=c08_UInt_SNA_na, init-value=XDIS_2kt9ss9xytkqyzr4359iyexvi/l0  # Steuergerät zu Applikation / ECU to Application
          signal ECU_APPL_ISM_2F: start 40, 8 bit, little-endian, data-type=c08_UInt_SNA_na, init-value=XDIS_2kt9ss9xytkqyzr4359iyexvi/l0  # Steuergerät zu Applikation / ECU to Application
          signal ECU_APPL_ISM_2G: start 48, 8 bit, little-endian, data-type=c08_UInt_SNA_na, init-value=XDIS_2kt9ss9xytkqyzr4359iyexvi/l0  # Steuergerät zu Applikation / ECU to Application
          signal ECU_APPL_ISM_2H: start 56, 8 bit, little-endian, data-type=c08_UInt_SNA_na, init-value=XDIS_2kt9ss9xytkqyzr4359iyexvi/l0  # Steuergerät zu Applikation / ECU to Application
          signal ECU_APPL_ISM2_8va3ehzr91vpl316qv3y6y7a5: little-endian, system-signal=[ECU_APPL_ISM_2A, ECU_APPL_ISM_2B, ECU_APPL_ISM_2C, ECU_APPL_ISM_2D, ECU_APPL_ISM_2E, ECU_APPL_ISM_2F, ECU_APPL_ISM_2G, ECU_APPL_ISM_2H], transfer-property=TRIGGERED  # Steuergerät zu Applikation (degraded) / ECU to Application (degraded)
      frame ECU_APPL_ISM3: id 0x18EF5F05, from ISM, frame-length=8, can-addressing-mode=EXTENDED  # Steuergerät zu Applikation / ECU to Application
        pdu ECU_APPL_ISM3: length=64, unused-bit-pattern=0, event-controlled-timing=number-of-repeats=0, minimum-delay=0.0050  # Steuergerät zu Applikation / ECU to Application
          signal ECU_APPL_ISM_3A: start 0, 8 bit, little-endian, data-type=c08_UInt_SNA_na, init-value=XDIS_2kt9ss9xytkqyzr4359iyexvi/l0  # Steuergerät zu Applikation / ECU to Application
          signal ECU_APPL_ISM_3B: start 8, 8 bit, little-endian, data-type=c08_UInt_SNA_na, init-value=XDIS_2kt9ss9xytkqyzr4359iyexvi/l0  # Steuergerät zu Applikation / ECU to Application
          signal ECU_APPL_ISM_3C: start 16, 8 bit, little-endian, data-type=c08_UInt_SNA_na, init-value=XDIS_2kt9ss9xytkqyzr4359iyexvi/l0  # Steuergerät zu Applikation / ECU to Application
          signal ECU_APPL_ISM_3D: start 24, 8 bit, little-endian, data-type=c08_UInt_SNA_na, init-value=XDIS_2kt9ss9xytkqyzr4359iyexvi/l0  # Steuergerät zu Applikation / ECU to Application
          signal ECU_APPL_ISM_3E: start 32, 8 bit, little-endian, data-type=c08_UInt_SNA_na, init-value=XDIS_2kt9ss9xytkqyzr4359iyexvi/l0  # Steuergerät zu Applikation / ECU to Application
          signal ECU_APPL_ISM_3F: start 40, 8 bit, little-endian, data-type=c08_UInt_SNA_na, init-value=XDIS_2kt9ss9xytkqyzr4359iyexvi/l0  # Steuergerät zu Applikation / ECU to Application
          signal ECU_APPL_ISM_3G: start 48, 8 bit, little-endian, data-type=c08_UInt_SNA_na, init-value=XDIS_2kt9ss9xytkqyzr4359iyexvi/l0  # Steuergerät zu Applikation / ECU to Application
          signal ECU_APPL_ISM_3H: start 56, 8 bit, little-endian, data-type=c08_UInt_SNA_na, init-value=XDIS_2kt9ss9xytkqyzr4359iyexvi/l0  # Steuergerät zu Applikation / ECU to Application
          signal ECU_APPL_ISM3_90diuvxlz0lg45a5437kvhgbn: little-endian, system-signal=[ECU_APPL_ISM_3A, ECU_APPL_ISM_3B, ECU_APPL_ISM_3C, ECU_APPL_ISM_3D, ECU_APPL_ISM_3E, ECU_APPL_ISM_3F, ECU_APPL_ISM_3G, ECU_APPL_ISM_3H], transfer-property=TRIGGERED  # Steuergerät zu Applikation (degraded) / ECU to Application (degraded)
      frame APPL_ECU_ISM1: id 0x18EF5F06, to ISM, frame-length=8, can-addressing-mode=EXTENDED  # Applikation zu Steuergerät / Application to ECU
        pdu APPL_ECU_ISM1: length=64, unused-bit-pattern=0, event-controlled-timing=number-of-repeats=0, minimum-delay=0.0050  # Applikation zu Steuergerät / Application to ECU
          signal APPL_ECU_ISM_1A: start 0, 8 bit, little-endian, data-type=c08_UInt_SNA_na, init-value=XDIS_2kt9ss9xytkqyzr4359iyexvi/l0, to ISM  # Steuergerät zu Applikation / ECU to Application
          signal APPL_ECU_ISM_1B: start 8, 8 bit, little-endian, data-type=c08_UInt_SNA_na, init-value=XDIS_2kt9ss9xytkqyzr4359iyexvi/l0, to ISM  # Steuergerät zu Applikation / ECU to Application
          signal APPL_ECU_ISM_1C: start 16, 8 bit, little-endian, data-type=c08_UInt_SNA_na, init-value=XDIS_2kt9ss9xytkqyzr4359iyexvi/l0, to ISM  # Steuergerät zu Applikation / ECU to Application
          signal APPL_ECU_ISM_1D: start 24, 8 bit, little-endian, data-type=c08_UInt_SNA_na, init-value=XDIS_2kt9ss9xytkqyzr4359iyexvi/l0, to ISM  # Steuergerät zu Applikation / ECU to Application
          signal APPL_ECU_ISM_1E: start 32, 8 bit, little-endian, data-type=c08_UInt_SNA_na, init-value=XDIS_2kt9ss9xytkqyzr4359iyexvi/l0, to ISM  # Steuergerät zu Applikation / ECU to Application
          signal APPL_ECU_ISM_1F: start 40, 8 bit, little-endian, data-type=c08_UInt_SNA_na, init-value=XDIS_2kt9ss9xytkqyzr4359iyexvi/l0, to ISM  # Steuergerät zu Applikation / ECU to Application
          signal APPL_ECU_ISM_1G: start 48, 8 bit, little-endian, data-type=c08_UInt_SNA_na, init-value=XDIS_2kt9ss9xytkqyzr4359iyexvi/l0, to ISM  # Steuergerät zu Applikation / ECU to Application
          signal APPL_ECU_ISM_1H: start 56, 8 bit, little-endian, data-type=c08_UInt_SNA_na, init-value=XDIS_2kt9ss9xytkqyzr4359iyexvi/l0, to ISM  # Steuergerät zu Applikation / ECU to Application
          signal APPL_ECU_ISM1_886jtkw1iycgtnn3hwl0wnyvu: little-endian, system-signal=[APPL_ECU_ISM_1A, APPL_ECU_ISM_1B, APPL_ECU_ISM_1C, APPL_ECU_ISM_1D, APPL_ECU_ISM_1E, APPL_ECU_ISM_1F, APPL_ECU_ISM_1G, APPL_ECU_ISM_1H], transfer-property=TRIGGERED, to ISM  # Steuergerät zu Applikation (degraded) / ECU to Application (degraded)
      frame APPL_ECU_ISM2: id 0x18EF5F07, to ISM, frame-length=8, can-addressing-mode=EXTENDED  # Applikation zu Steuergerät / Application to ECU
        pdu APPL_ECU_ISM2: length=64, unused-bit-pattern=0, event-controlled-timing=number-of-repeats=0, minimum-delay=0.0050  # Applikation zu Steuergerät / Application to ECU
          signal APPL_ECU_ISM_2A: start 0, 8 bit, little-endian, data-type=c08_UInt_SNA_na, init-value=XDIS_2kt9ss9xytkqyzr4359iyexvi/l0, to ISM  # Steuergerät zu Applikation / ECU to Application
          signal APPL_ECU_ISM_2B: start 8, 8 bit, little-endian, data-type=c08_UInt_SNA_na, init-value=XDIS_2kt9ss9xytkqyzr4359iyexvi/l0, to ISM  # Steuergerät zu Applikation / ECU to Application
          signal APPL_ECU_ISM_2C: start 16, 8 bit, little-endian, data-type=c08_UInt_SNA_na, init-value=XDIS_2kt9ss9xytkqyzr4359iyexvi/l0, to ISM  # Steuergerät zu Applikation / ECU to Application
          signal APPL_ECU_ISM_2D: start 24, 8 bit, little-endian, data-type=c08_UInt_SNA_na, init-value=XDIS_2kt9ss9xytkqyzr4359iyexvi/l0, to ISM  # Steuergerät zu Applikation / ECU to Application
          signal APPL_ECU_ISM_2E: start 32, 8 bit, little-endian, data-type=c08_UInt_SNA_na, init-value=XDIS_2kt9ss9xytkqyzr4359iyexvi/l0, to ISM  # Steuergerät zu Applikation / ECU to Application
          signal APPL_ECU_ISM_2F: start 40, 8 bit, little-endian, data-type=c08_UInt_SNA_na, init-value=XDIS_2kt9ss9xytkqyzr4359iyexvi/l0, to ISM  # Steuergerät zu Applikation / ECU to Application
          signal APPL_ECU_ISM_2G: start 48, 8 bit, little-endian, data-type=c08_UInt_SNA_na, init-value=XDIS_2kt9ss9xytkqyzr4359iyexvi/l0, to ISM  # Steuergerät zu Applikation / ECU to Application
          signal APPL_ECU_ISM_2H: start 56, 8 bit, little-endian, data-type=c08_UInt_SNA_na, init-value=XDIS_2kt9ss9xytkqyzr4359iyexvi/l0, to ISM  # Steuergerät zu Applikation / ECU to Application
          signal APPL_ECU_ISM2_414durxpb4zkiz07ge51mu0wf: little-endian, system-signal=[APPL_ECU_ISM_2A, APPL_ECU_ISM_2B, APPL_ECU_ISM_2C, APPL_ECU_ISM_2D, APPL_ECU_ISM_2E, APPL_ECU_ISM_2F, APPL_ECU_ISM_2G, APPL_ECU_ISM_2H], transfer-property=TRIGGERED, to ISM  # Steuergerät zu Applikation (degraded) / ECU to Application (degraded)
      frame Meas_SSP: id 0x18EF603D, from SSP, frame-length=8, can-addressing-mode=EXTENDED
        pdu Meas_SSP: length=64, unused-bit-pattern=0, event-controlled-timing=number-of-repeats=0, minimum-delay=0.0050  # Messdaten / Measurement data
          signal Meas_SSP_1A: start 0, 8 bit, little-endian, data-type=c08_UInt_SNA_na, init-value=XDIS_2kt9ss9xytkqyzr4359iyexvi/l0  # Messdaten / Measurement data
          signal Meas_SSP_1B: start 8, 8 bit, little-endian, data-type=c08_UInt_SNA_na, init-value=XDIS_2kt9ss9xytkqyzr4359iyexvi/l0  # Messdaten / Measurement data
          signal Meas_SSP_1C: start 16, 8 bit, little-endian, data-type=c08_UInt_SNA_na, init-value=XDIS_2kt9ss9xytkqyzr4359iyexvi/l0  # Messdaten / Measurement data
          signal Meas_SSP_1D: start 24, 8 bit, little-endian, data-type=c08_UInt_SNA_na, init-value=XDIS_2kt9ss9xytkqyzr4359iyexvi/l0  # Messdaten / Measurement data
          signal Meas_SSP_1E: start 32, 8 bit, little-endian, data-type=c08_UInt_SNA_na, init-value=XDIS_2kt9ss9xytkqyzr4359iyexvi/l0  # Messdaten / Measurement data
          signal Meas_SSP_1F: start 40, 8 bit, little-endian, data-type=c08_UInt_SNA_na, init-value=XDIS_2kt9ss9xytkqyzr4359iyexvi/l0  # Messdaten / Measurement data
          signal Meas_SSP_1G: start 48, 8 bit, little-endian, data-type=c08_UInt_SNA_na, init-value=XDIS_2kt9ss9xytkqyzr4359iyexvi/l0  # Messdaten / Measurement data
          signal Meas_SSP_1H: start 56, 8 bit, little-endian, data-type=c08_UInt_SNA_na, init-value=XDIS_2kt9ss9xytkqyzr4359iyexvi/l0  # Messdaten / Measurement data
          signal Meas_SSP_379btqek1l385mbjtnm74j6ok: little-endian, system-signal=[Meas_SSP_1A, Meas_SSP_1B, Meas_SSP_1C, Meas_SSP_1D, Meas_SSP_1E, Meas_SSP_1F, Meas_SSP_1G, Meas_SSP_1H], transfer-property=TRIGGERED  # Messdaten (degraded) / Measurement data (degraded)
      frame APPL_ECU_SSP_1: id 0x18EF603E, to SSP, frame-length=8, can-addressing-mode=EXTENDED
        pdu APPL_ECU_SSP_1: length=64, unused-bit-pattern=0, event-controlled-timing=number-of-repeats=0, minimum-delay=0.0050  # ECU to external application
          signal APPL_ECU_SSP_1A: start 0, 8 bit, little-endian, data-type=c08_UInt_SNA_na, init-value=XDIS_2kt9ss9xytkqyzr4359iyexvi/l0, to SSP  # Steuergerät an externe Applikation / ECU to external application
          signal APPL_ECU_SSP_1B: start 8, 8 bit, little-endian, data-type=c08_UInt_SNA_na, init-value=XDIS_2kt9ss9xytkqyzr4359iyexvi/l0, to SSP  # Steuergerät an externe Applikation / ECU to external application
          signal APPL_ECU_SSP_1C: start 16, 8 bit, little-endian, data-type=c08_UInt_SNA_na, init-value=XDIS_2kt9ss9xytkqyzr4359iyexvi/l0, to SSP  # Steuergerät an externe Applikation / ECU to external application
          signal APPL_ECU_SSP_1D: start 24, 8 bit, little-endian, data-type=c08_UInt_SNA_na, init-value=XDIS_2kt9ss9xytkqyzr4359iyexvi/l0, to SSP  # Steuergerät an externe Applikation / ECU to external application
          signal APPL_ECU_SSP_1E: start 32, 8 bit, little-endian, data-type=c08_UInt_SNA_na, init-value=XDIS_2kt9ss9xytkqyzr4359iyexvi/l0, to SSP  # Steuergerät an externe Applikation / ECU to external application
          signal APPL_ECU_SSP_1F: start 40, 8 bit, little-endian, data-type=c08_UInt_SNA_na, init-value=XDIS_2kt9ss9xytkqyzr4359iyexvi/l0, to SSP  # Steuergerät an externe Applikation / ECU to external application
          signal APPL_ECU_SSP_1G: start 48, 8 bit, little-endian, data-type=c08_UInt_SNA_na, init-value=XDIS_2kt9ss9xytkqyzr4359iyexvi/l0, to SSP  # Steuergerät an externe Applikation / ECU to external application
          signal APPL_ECU_SSP_1H: start 56, 8 bit, little-endian, data-type=c08_UInt_SNA_na, init-value=XDIS_2kt9ss9xytkqyzr4359iyexvi/l0, to SSP  # Steuergerät an externe Applikation / ECU to external application
          signal APPL_ECU_SSP_1_bhdkr7ytnkqdldfnan7bi0hzl: little-endian, system-signal=[APPL_ECU_SSP_1A, APPL_ECU_SSP_1B, APPL_ECU_SSP_1C, APPL_ECU_SSP_1D, APPL_ECU_SSP_1E, APPL_ECU_SSP_1F, APPL_ECU_SSP_1G, APPL_ECU_SSP_1H], transfer-property=TRIGGERED, to SSP  # Messdaten (degraded) / Measurement data (degraded)
      frame ECU_APPL_SSP_1: id 0x18EF603F, from SSP, frame-length=8, can-addressing-mode=EXTENDED
        pdu ECU_APPL_SSP_1: length=64, unused-bit-pattern=0, event-controlled-timing=number-of-repeats=0, minimum-delay=0.0050  # ECU to external application
          signal ECU_APPL_SSP_1A: start 0, 8 bit, little-endian, data-type=c08_UInt_SNA_na, init-value=XDIS_2kt9ss9xytkqyzr4359iyexvi/l0  # Steuergerät an externe Applikation / ECU to external application
          signal ECU_APPL_SSP_1B: start 8, 8 bit, little-endian, data-type=c08_UInt_SNA_na, init-value=XDIS_2kt9ss9xytkqyzr4359iyexvi/l0  # Steuergerät an externe Applikation / ECU to external application
          signal ECU_APPL_SSP_1C: start 16, 8 bit, little-endian, data-type=c08_UInt_SNA_na, init-value=XDIS_2kt9ss9xytkqyzr4359iyexvi/l0  # Steuergerät an externe Applikation / ECU to external application
          signal ECU_APPL_SSP_1D: start 24, 8 bit, little-endian, data-type=c08_UInt_SNA_na, init-value=XDIS_2kt9ss9xytkqyzr4359iyexvi/l0  # Steuergerät an externe Applikation / ECU to external application
          signal ECU_APPL_SSP_1E: start 32, 8 bit, little-endian, data-type=c08_UInt_SNA_na, init-value=XDIS_2kt9ss9xytkqyzr4359iyexvi/l0  # Steuergerät an externe Applikation / ECU to external application
          signal ECU_APPL_SSP_1F: start 40, 8 bit, little-endian, data-type=c08_UInt_SNA_na, init-value=XDIS_2kt9ss9xytkqyzr4359iyexvi/l0  # Steuergerät an externe Applikation / ECU to external application
          signal ECU_APPL_SSP_1G: start 48, 8 bit, little-endian, data-type=c08_UInt_SNA_na, init-value=XDIS_2kt9ss9xytkqyzr4359iyexvi/l0  # Steuergerät an externe Applikation / ECU to external application
          signal ECU_APPL_SSP_1H: start 56, 8 bit, little-endian, data-type=c08_UInt_SNA_na, init-value=XDIS_2kt9ss9xytkqyzr4359iyexvi/l0  # Steuergerät an externe Applikation / ECU to external application
          signal ECU_APPL_SSP_1_cozcqf4g8wtxil74o34x10gji: little-endian, system-signal=[ECU_APPL_SSP_1A, ECU_APPL_SSP_1B, ECU_APPL_SSP_1C, ECU_APPL_SSP_1D, ECU_APPL_SSP_1E, ECU_APPL_SSP_1F, ECU_APPL_SSP_1G, ECU_APPL_SSP_1H], transfer-property=TRIGGERED  # Messdaten (degraded) / Measurement data (degraded)
      frame ROE_FFAP: id 0x18EFA100, from FFAP_STAR_2, to CPC, frame-length=8, can-addressing-mode=EXTENDED  # RoE lite
        pdu ROE_FFAP: length=64, unused-bit-pattern=0, event-controlled-timing=number-of-repeats=0, minimum-delay=0.2  # RoE-lite / RoE lite
          signal ROE_DTC_FFAP: start 32, 24 bit, little-endian, data-type=c24_0_16777215_1_SNA_na, init-value=XDIS_d00a2pwsicon8afnf0ovtodtq/l0, to CPC  # Fehlercode RoE-lite / RoE lite diagnostic trouble code
          signal ROE_DTC_Stat_FFAP: start 56, 8 bit, little-endian, data-type=c08_0_255_1_SNA_na, init-value=XDIS_e83grhz0aqm1yaa82ns55ebek/l0, to CPC  # Fehlercode-Status RoE-lite / RoE lite diagnostic trouble code state
          signal ROE_Header_FFAP: start 0, 32 bit, little-endian, data-type=c32_0_4294967295_1_SNA_na, init-value=l940295, to CPC  # Header RoE-lite / RoE lite header
          signal ROE_FFAP_8qrxhmgz4wjb2b2xcd9pf7ii7: little-endian, system-signal=[ROE_DTC_FFAP, ROE_DTC_Stat_FFAP, ROE_Header_FFAP], transfer-property=TRIGGERED, to CPC  # RoE-lite (degraded) / RoE lite (degraded)
      frame XCP_Rq_FFAP_1: id 0x18EFA101, from CPC, to FFAP_STAR_2, frame-length=8, can-addressing-mode=EXTENDED
        user defined i pdu XCP_Rq_FFAP_1: length=64, unused-bit-pattern=0, cdd-type=XCP  # XCP-Anforderung / Extended calibration protocol request
      frame XCP_Rs_FFAP_1: id 0x18EFA102, from FFAP_STAR_2, to CPC, frame-length=8, can-addressing-mode=EXTENDED
        user defined i pdu XCP_Rs_FFAP_1: length=64, unused-bit-pattern=0, cdd-type=XCP  # XCP-Antwort / Extended calibration protocol response
      frame XCP_Rs_FFAP_2: id 0x18EFA103, from FFAP_STAR_2, to CPC, frame-length=8, can-addressing-mode=EXTENDED
        user defined i pdu XCP_Rs_FFAP_2: length=64, unused-bit-pattern=0, cdd-type=XCP  # XCP-Antwort / Extended calibration protocol response
      frame XCP_Rs_TCM5: id 0x18EFA517, from TCM, frame-length=8, can-addressing-mode=EXTENDED
        user defined i pdu XCP_Rs_TCM5: length=64, unused-bit-pattern=0, cdd-type=XCP  # XCP-Anforderung / Extended calibration protocol response
      pdu triggering XDIS_1l6hxs9sd223zrdjk5xfxv92n: pdu=SDU_DIAG_RQ_ASX_POWERTRAIN, from CPC, to ASX
      pdu triggering XDIS_cd9f26djyfp92ozyhvvtvijc7: pdu=SDU_DIAG_RQ_AWD_POWERTRAIN, from CPC
      pdu triggering XDIS_419gxplgv4tlufe28ok77wh3z: pdu=SDU_DIAG_RQ_FFAP_PT, from CPC, to FFAP_STAR_2
      pdu triggering XDIS_9ul2lu3aa2eer7udm3kc0v9yv: pdu=SDU_DIAG_RQ_FSCM_PT, from CPC, to FSCM
      pdu triggering XDIS_89rclqxieb26aqm0i5d7z53sb: pdu=SDU_DIAG_RQ_GLOBAL_UDS_PT, from CPC, to ASX FFAP_STAR_2 FSCM ISM TCM
      pdu triggering XDIS_2s4aopnfhh3yrtrnuhlqpwror: pdu=SDU_DIAG_RQ_ISM_PT, from CPC, to ISM
      pdu triggering XDIS_dfub2rkr9eqtat5q81mj71vv9: pdu=SDU_DIAG_RQ_TCM_PT, from CPC, to TCM
      pdu triggering XDIS_4evbijopcl0xuwzk2q0wz6vtt: pdu=SDU_DIAG_RS_ASX_POWERTRAIN, from ASX, to CPC
      pdu triggering XDIS_orqbsuid93c0vzlalhvt8qw2: pdu=SDU_DIAG_RS_AWD_POWERTRAIN, to CPC
      pdu triggering XDIS_11evtsxagvj9onlw31fg78wuy: pdu=SDU_DIAG_RS_FFAP_PT, from FFAP_STAR_2, to CPC
      pdu triggering XDIS_1rm0o3tykh43itb5gpd1l1hrm: pdu=SDU_DIAG_RS_FSCM_PT, from FSCM, to CPC
      pdu triggering XDIS_cdsadjltfkc7k7dg7fnuyw11m: pdu=SDU_DIAG_RS_ISM_PT, from ISM, to CPC
      pdu triggering XDIS_9ypc3vr77x4q56ljl25bknklp: pdu=SDU_DIAG_RS_TCM_PT, from TCM, to CPC
      pdu triggering XDIS_5y2k2p27m97c36ze2grctplgx: pdu=SDU_DIAGX_RQ_FSCM_OBD, from CPC, to FSCM
      pdu triggering XDIS_89ul43yno3pw93hku1ry1ehhf: pdu=SDU_DIAGX_RQ_GLOBAL_OBD, from CPC, to FSCM TCM
      pdu triggering XDIS_9n1gvkbwnsne5mxujk0hkyjwo: pdu=SDU_DIAGX_RQ_TCM_OBD, from CPC, to TCM
      pdu triggering XDIS_9q7dvpnewcpipew8aneuac1w8: pdu=SDU_DIAGX_RS_FSCM_OBD, from FSCM, to CPC
      pdu triggering XDIS_exa4imkklf8tl8kohl6u37dhl: pdu=SDU_DIAGX_RS_TCM_OBD, from TCM, to CPC
      20 x tp address:
        TPA_0441h: tp-address=1089
        TPA_05aah: tp-address=1450
        TPA_05dch: tp-address=1500
        TPA_05deh: tp-address=1502
        TPA_05dfh: tp-address=1503
        TPA_062ah: tp-address=1578
        TPA_065ch: tp-address=1628
        TPA_065eh: tp-address=1630
        TPA_065fh: tp-address=1631
        TPA_07e1h: tp-address=2017
        TPA_07e3h: tp-address=2019
        TPA_07e9h: tp-address=2025
        TPA_07ebh: tp-address=2027
        TPA_0ef0h: tp-address=3824
        TPA_5affh: tp-address=23295
        TPA_5cffh: tp-address=23807
        TPA_da5ch: tp-address=55900
        TPA_daf1h: tp-address=56049
        TPA_db33h: tp-address=56115
        TPA_f1ffh: tp-address=61951
      tp-channels:
        addressing-format=STANDARD, block-size=8, channel-mode-type=FULL-DUPLEX-MODE, data-pdu=DIAG_RQ_ASX, flow-control-pdu=DIAG_RS_ASX, minimum-separation-time=0.01, multicast-addressing=false, padding-activation=true, source=XDIS_a7s8u9l16t6w185syxz05m1m7, target=XDIS_6yo0yl12r7cug9wminnxrnwyr, tp-sdu=SDU_DIAG_RQ_ASX_POWERTRAIN
        addressing-format=STANDARD, block-size=8, channel-mode-type=FULL-DUPLEX-MODE, data-pdu=DIAG_RQ_AWD, flow-control-pdu=DIAG_RS_AWD, minimum-separation-time=0.01, multicast-addressing=false, padding-activation=true, source=XDIS_a7s8u9l16t6w185syxz05m1m7, target=XDIS_9k87ams1g1kyjex43tu3ralcr, tp-sdu=SDU_DIAG_RQ_AWD_POWERTRAIN
        addressing-format=STANDARD, block-size=8, channel-mode-type=FULL-DUPLEX-MODE, data-pdu=DIAG_RQ_FFAP, flow-control-pdu=DIAG_RS_FFAP, minimum-separation-time=0.01, multicast-addressing=false, padding-activation=true, source=XDIS_a7s8u9l16t6w185syxz05m1m7, target=XDIS_6iflwqun6gv2x3wgsusluxvco, tp-sdu=SDU_DIAG_RQ_FFAP_PT
        addressing-format=STANDARD, block-size=8, channel-mode-type=FULL-DUPLEX-MODE, data-pdu=DIAG_RQ_FSCM, flow-control-pdu=DIAG_RS_FSCM, minimum-separation-time=0.01, multicast-addressing=false, padding-activation=true, source=XDIS_a7s8u9l16t6w185syxz05m1m7, target=XDIS_82e2zepienfntyxshe1hrv9b2, tp-sdu=SDU_DIAG_RQ_FSCM_PT
        addressing-format=STANDARD, block-size=8, channel-mode-type=FULL-DUPLEX-MODE, data-pdu=DIAG_RQ_GLOBAL_UDS, minimum-separation-time=0.01, multicast-addressing=true, multicast=TPA_0441h, padding-activation=true, source=XDIS_a7s8u9l16t6w185syxz05m1m7, target=[XDIS_7jp9th5i5dm3m2lg3uk4f3sr1, XDIS_9p4w5isrfrsmbrphx40c6xmoo, XDIS_c09iw5b9rurvclrwer3ld2c7n, XDIS_5c35vc6eeufus9qhhtudfftai, XDIS_ehmtyebtwe9wxbqftde5pxslq], tp-sdu=SDU_DIAG_RQ_GLOBAL_UDS_PT
        addressing-format=STANDARD, block-size=8, channel-mode-type=FULL-DUPLEX-MODE, data-pdu=DIAG_RQ_ISM, flow-control-pdu=DIAG_RS_ISM, minimum-separation-time=0.01, multicast-addressing=false, padding-activation=true, source=XDIS_a7s8u9l16t6w185syxz05m1m7, target=XDIS_djjp025zpfqfo5w9x2hp9h5ry, tp-sdu=SDU_DIAG_RQ_ISM_PT
        addressing-format=STANDARD, block-size=8, channel-mode-type=FULL-DUPLEX-MODE, data-pdu=DIAG_RQ_TCM, flow-control-pdu=DIAG_RS_TCM, minimum-separation-time=0.01, multicast-addressing=false, padding-activation=true, source=XDIS_a7s8u9l16t6w185syxz05m1m7, target=XDIS_d8ff66j8slt9we1yblcegbk74, tp-sdu=SDU_DIAG_RQ_TCM_PT
        addressing-format=STANDARD, block-size=8, channel-mode-type=FULL-DUPLEX-MODE, data-pdu=DIAG_RS_ASX, flow-control-pdu=DIAG_RQ_ASX, minimum-separation-time=0.01, multicast-addressing=false, padding-activation=true, source=XDIS_9dgbhe2pa8bkxe4qhp7oq2pv7, target=XDIS_a7s8u9l16t6w185syxz05m1m7, tp-sdu=SDU_DIAG_RS_ASX_POWERTRAIN
        addressing-format=STANDARD, block-size=8, channel-mode-type=FULL-DUPLEX-MODE, data-pdu=DIAG_RS_AWD, flow-control-pdu=DIAG_RQ_AWD, minimum-separation-time=0.01, multicast-addressing=false, padding-activation=true, source=XDIS_b6n5rl1uvcyigwjeybt5tt55t, target=XDIS_a7s8u9l16t6w185syxz05m1m7, tp-sdu=SDU_DIAG_RS_AWD_POWERTRAIN
        addressing-format=STANDARD, block-size=8, channel-mode-type=FULL-DUPLEX-MODE, data-pdu=DIAG_RS_FFAP, flow-control-pdu=DIAG_RQ_FFAP, minimum-separation-time=0.01, multicast-addressing=false, padding-activation=true, source=XDIS_f51dxmdww0mwunot9fioy0pvg, target=XDIS_a7s8u9l16t6w185syxz05m1m7, tp-sdu=SDU_DIAG_RS_FFAP_PT
        addressing-format=STANDARD, block-size=8, channel-mode-type=FULL-DUPLEX-MODE, data-pdu=DIAG_RS_FSCM, flow-control-pdu=DIAG_RQ_FSCM, minimum-separation-time=0.0, multicast-addressing=false, padding-activation=true, source=XDIS_9smfcgpyl81ac4mal0x5tpqwf, target=XDIS_a7s8u9l16t6w185syxz05m1m7, tp-sdu=SDU_DIAG_RS_FSCM_PT
        addressing-format=STANDARD, block-size=8, channel-mode-type=FULL-DUPLEX-MODE, data-pdu=DIAG_RS_ISM, flow-control-pdu=DIAG_RQ_ISM, minimum-separation-time=0.01, multicast-addressing=false, padding-activation=true, source=XDIS_797z7a4xa3n35c1ry9j5ta8le, target=XDIS_a7s8u9l16t6w185syxz05m1m7, tp-sdu=SDU_DIAG_RS_ISM_PT
        addressing-format=STANDARD, block-size=8, channel-mode-type=FULL-DUPLEX-MODE, data-pdu=DIAG_RS_TCM, flow-control-pdu=DIAG_RQ_TCM, minimum-separation-time=0.0, multicast-addressing=false, padding-activation=true, source=XDIS_abjcz6swi0htnapyzmbeuneks, target=XDIS_a7s8u9l16t6w185syxz05m1m7, tp-sdu=SDU_DIAG_RS_TCM_PT
        addressing-format=STANDARD, block-size=8, channel-mode-type=FULL-DUPLEX-MODE, data-pdu=DIAGX_RQ_FSCM_OBD, flow-control-pdu=DIAGX_RS_FSCM_OBD, minimum-separation-time=0.01, multicast-addressing=false, padding-activation=true, source=XDIS_br1dpic4v24bnll0svcqmhpgg, target=XDIS_bjuvya91bq5x6jxgl02a3tytk, tp-sdu=SDU_DIAGX_RQ_FSCM_OBD
        addressing-format=STANDARD, block-size=32, channel-mode-type=FULL-DUPLEX-MODE, data-pdu=DIAGX_RQ_GLOBAL_OBD, minimum-separation-time=0.0, multicast-addressing=true, multicast=TPA_0441h, padding-activation=true, source=XDIS_br1dpic4v24bnll0svcqmhpgg, target=[XDIS_sf2ncr9cnvb0i8rxk0zwpkwv, XDIS_7nh7ybqvbfzew69cajutisti5], tp-sdu=SDU_DIAGX_RQ_GLOBAL_OBD
        addressing-format=STANDARD, block-size=8, channel-mode-type=FULL-DUPLEX-MODE, data-pdu=DIAGX_RQ_TCM_OBD, flow-control-pdu=DIAGX_RS_TCM_OBD, minimum-separation-time=0.01, multicast-addressing=false, padding-activation=true, source=XDIS_br1dpic4v24bnll0svcqmhpgg, target=XDIS_9ibhzck86twzktiy3rwi4ka3, tp-sdu=SDU_DIAGX_RQ_TCM_OBD
        addressing-format=STANDARD, block-size=8, channel-mode-type=FULL-DUPLEX-MODE, data-pdu=DIAGX_RS_FSCM_OBD, flow-control-pdu=DIAGX_RQ_FSCM_OBD, minimum-separation-time=0.0, multicast-addressing=false, padding-activation=true, source=XDIS_m3tmqf7980k4yorveip6j2xf, target=XDIS_6p1ywgqzcace9t2kpgie29lle, tp-sdu=SDU_DIAGX_RS_FSCM_OBD
        addressing-format=STANDARD, block-size=8, channel-mode-type=FULL-DUPLEX-MODE, data-pdu=DIAGX_RS_TCM_OBD, flow-control-pdu=DIAGX_RQ_TCM_OBD, minimum-separation-time=0.0, multicast-addressing=false, padding-activation=true, source=XDIS_24awc2qxab71p9p4jokpqbcbz, target=XDIS_6p1ywgqzcace9t2kpgie29lle, tp-sdu=SDU_DIAGX_RS_TCM_OBD
      26 x can tp node:
        XDIS_7jp9th5i5dm3m2lg3uk4f3sr1: connector=XDIS_49itp1vliru6t3jfbko77gn3l, tp-address=TPA_0441h
        XDIS_9p4w5isrfrsmbrphx40c6xmoo: connector=XDIS_c72dufe5cx3e7qbatpga1hygd, tp-address=TPA_0441h
        XDIS_c09iw5b9rurvclrwer3ld2c7n: connector=XDIS_1436dbah15lq29z99i3amvzp5, tp-address=TPA_0441h
        XDIS_5c35vc6eeufus9qhhtudfftai: connector=XDIS_6bnwgewl5i1i9gxjca55filo2, tp-address=TPA_0441h
        XDIS_ehmtyebtwe9wxbqftde5pxslq: connector=XDIS_ezray0teml101xbe2qouy0iov, tp-address=TPA_0441h
        XDIS_9dgbhe2pa8bkxe4qhp7oq2pv7: connector=XDIS_49itp1vliru6t3jfbko77gn3l, tp-address=TPA_05aah
        XDIS_f51dxmdww0mwunot9fioy0pvg: connector=XDIS_c72dufe5cx3e7qbatpga1hygd, tp-address=TPA_05dch
        XDIS_b6n5rl1uvcyigwjeybt5tt55t: tp-address=TPA_05deh
        XDIS_797z7a4xa3n35c1ry9j5ta8le: connector=XDIS_6bnwgewl5i1i9gxjca55filo2, tp-address=TPA_05dfh
        XDIS_6yo0yl12r7cug9wminnxrnwyr: connector=XDIS_49itp1vliru6t3jfbko77gn3l, tp-address=TPA_062ah
        XDIS_6iflwqun6gv2x3wgsusluxvco: connector=XDIS_c72dufe5cx3e7qbatpga1hygd, tp-address=TPA_065ch
        XDIS_9k87ams1g1kyjex43tu3ralcr: tp-address=TPA_065eh
        XDIS_djjp025zpfqfo5w9x2hp9h5ry: connector=XDIS_6bnwgewl5i1i9gxjca55filo2, tp-address=TPA_065fh
        XDIS_d8ff66j8slt9we1yblcegbk74: connector=XDIS_ezray0teml101xbe2qouy0iov, tp-address=TPA_07e1h
        XDIS_82e2zepienfntyxshe1hrv9b2: connector=XDIS_1436dbah15lq29z99i3amvzp5, tp-address=TPA_07e3h
        XDIS_abjcz6swi0htnapyzmbeuneks: connector=XDIS_ezray0teml101xbe2qouy0iov, tp-address=TPA_07e9h
        XDIS_9smfcgpyl81ac4mal0x5tpqwf: connector=XDIS_1436dbah15lq29z99i3amvzp5, tp-address=TPA_07ebh
        XDIS_a7s8u9l16t6w185syxz05m1m7: connector=XDIS_3ok1kc7qnfrmoouz6zcasiq44, tp-address=TPA_0ef0h
        XDIS_24awc2qxab71p9p4jokpqbcbz: connector=XDIS_ezray0teml101xbe2qouy0iov, tp-address=TPA_5affh
        XDIS_m3tmqf7980k4yorveip6j2xf: connector=XDIS_1436dbah15lq29z99i3amvzp5, tp-address=TPA_5cffh
        XDIS_bjuvya91bq5x6jxgl02a3tytk: connector=XDIS_1436dbah15lq29z99i3amvzp5, tp-address=TPA_da5ch
        XDIS_6p1ywgqzcace9t2kpgie29lle: connector=XDIS_3ok1kc7qnfrmoouz6zcasiq44, tp-address=TPA_daf1h
        XDIS_9ibhzck86twzktiy3rwi4ka3: connector=XDIS_ezray0teml101xbe2qouy0iov, tp-address=TPA_daf1h
        XDIS_sf2ncr9cnvb0i8rxk0zwpkwv: connector=XDIS_1436dbah15lq29z99i3amvzp5, tp-address=TPA_db33h
        XDIS_7nh7ybqvbfzew69cajutisti5: connector=XDIS_ezray0teml101xbe2qouy0iov, tp-address=TPA_db33h
        XDIS_br1dpic4v24bnll0svcqmhpgg: connector=XDIS_3ok1kc7qnfrmoouz6zcasiq44, tp-address=TPA_f1ffh
package /POWERTRAIN/PKG_POWERTRAIN/PDUS
  dcm i pdu SDU_DIAG_RQ_ASX_POWERTRAIN: length=32760
  dcm i pdu SDU_DIAG_RQ_AWD_POWERTRAIN: length=32760
  dcm i pdu SDU_DIAG_RQ_FFAP_PT: length=32760
  dcm i pdu SDU_DIAG_RQ_FSCM_PT: length=32760
  dcm i pdu SDU_DIAG_RQ_GLOBAL_UDS_PT: length=32760
  dcm i pdu SDU_DIAG_RQ_ISM_PT: length=32760
  dcm i pdu SDU_DIAG_RQ_TCM_PT: length=32760
  dcm i pdu SDU_DIAG_RS_ASX_POWERTRAIN: length=32760
  dcm i pdu SDU_DIAG_RS_AWD_POWERTRAIN: length=32760
  dcm i pdu SDU_DIAG_RS_FFAP_PT: length=32760
  dcm i pdu SDU_DIAG_RS_FSCM_PT: length=32760
  dcm i pdu SDU_DIAG_RS_ISM_PT: length=32760
  dcm i pdu SDU_DIAG_RS_TCM_PT: length=32760
  dcm i pdu SDU_DIAGX_RQ_FSCM_OBD: length=32760
  dcm i pdu SDU_DIAGX_RQ_GLOBAL_OBD: length=32760
  dcm i pdu SDU_DIAGX_RQ_TCM_OBD: length=32760
  dcm i pdu SDU_DIAGX_RS_FSCM_OBD: length=32760
  dcm i pdu SDU_DIAGX_RS_TCM_OBD: length=32760
package /POWERTRAIN/PKG_POWERTRAIN/PDU_GROUPS
  24 x i pdu group:
    TxMess_ASX_POWERTRAIN: communication-direction=OUT, communication-mode=Measurement, i-pdu=ECU_APPL_ASX_1
    TxNorm_ASX_POWERTRAIN: communication-direction=OUT, communication-mode=Normal, i-pdu=[ASX_Stat_AR, ROE_ASX]
    TxNorm_CPC_POWERTRAIN:
      communication-direction=OUT
      communication-mode=Normal
      i-pdu=[AWD_TCASE_Stat1_AR2, BrkSys_Stat_AR2, CHASSIS_POWERTRAIN_R1_AR2, CHASSIS_POWERTRAIN_R2_AR2, CHASSIS_POWERTRAIN_R3_AR2, CHASSIS_POWERTRAIN_R4_AR2, CPC_PredStrat_Data_AR2, DAC4_ECM_AR, DAC4_ISM_AR, DAC4_TCM_AR, DPC_SHW_Rq2_AR2, DwnShft_Corr_AR2, EM01_Stat1_AR2, EM_PtMngmnt_Rq_AR2, Eng_Rs_1_PT_AR2, Eng_Rs_2_PT_AR2, Eng_Rs_3_AR2, EngCtrl_OBD4_AR2, EPKB_Stat_AR2, EVC_CfgBit_01_32_AR2, EVC_CfgBit_33_64_AR2, EVC_CfgBit_65_96_AR2, EVC_CfgList_01_0C_AR2, FBL_Cfg_Star2_AR, FFAP_Rq_AR, HVAC_Rs_AR2, HYBRID_POWERTRAIN_R1_AR2, IC_BasicInfo_AR2, Ign_Veh_Stat_AR2, LDC_SBW_Rq_SCCM_AR2, PARK_Drv_Rq_ESP_AR2, PN14_Stat2_AR2, PN14_Stat_AR, PT_DATA_AR2, PtMngmnt_Stat2_AR2, PW_XX_Stat_AR2, RTC_Stat1_AR2, SBW_DrvPosn_Disp_Rq_CPC_AR2, StWhl_Angl_Stat_AR2, UpShft_Corr_AR2, VehDyn_Stat1_AR2, VehDyn_Stat2_AR2, VIN_AR, Whl_Lt_Stat_AR2, Whl_Rt_Stat_AR2]
    TxRedu_CPC_POWERTRAIN: communication-direction=OUT, communication-mode=Reduced, i-pdu=[PtMngmnt_Rq_AR2, PtMngmnt_Stat_AR2]
    TxNorm_DRVU_POWERTRAIN: communication-direction=OUT, communication-mode=Normal, i-pdu=[DRVU_Stat_AR2, LDC_SBW_Rq_DRVU_AR2]
    TxNorm_ECM_POWERTRAIN: communication-direction=OUT, communication-mode=Normal, i-pdu=[ECM_DAC4_AR, Eng_Rs4_AR2, Eng_Rs_EngCtrl_AR2, EngCtrl_Eng_Stat_AR, EngCtrl_OBD1_AR, EngCtrl_Stat3_AR, EngCtrl_Stat4_AR2, EngCtrl_Stat_AR2, PT_ThermM_AR2, Tx_Rq_PtMngmnt_ECM_AR2, VehPwrMngmnt_Rq_AR]
    TxNorm_FFAP_STAR_2_POWERTRAIN: communication-direction=OUT, communication-mode=Normal, i-pdu=[FFAP_Stat_AR, ROE_FFAP]
    TxNorm_FSCM_POWERTRAIN: communication-direction=OUT, communication-mode=Normal, i-pdu=[FSCM_DTC_OBD_AR2, Fuel_Stat_AR2, FuelLvl_Stat_AR2, ROE_FSCM]
    TxMess_ISM_POWERTRAIN: communication-direction=OUT, communication-mode=Measurement, i-pdu=[ECU_APPL_ISM1, ECU_APPL_ISM2, ECU_APPL_ISM3]
    TxNorm_ISM_POWERTRAIN: communication-direction=OUT, communication-mode=Normal, i-pdu=[ISM_DAC4_AR, PARK_Drv_Rs_TCM_AR2, ROE_ISM, SBW_DrvPosn_Disp_Rq_ISM_AR2, SBW_Stat_AR2]
    TxMess_SSP_POWERTRAIN: communication-direction=OUT, communication-mode=Measurement, i-pdu=[ECU_APPL_SSP_1, Meas_SSP]
    TxNorm_SSP_POWERTRAIN: communication-direction=OUT, communication-mode=Normal, i-pdu=SSP_Rs_AR
    TxMess_TCM_POWERTRAIN: communication-direction=OUT, communication-mode=Measurement, i-pdu=[MESS_TCM_HSA_AR, MESS_TCM_HSB_AR, MESS_TCM_HSC_AR, MESS_TCM_HSD_AR, MESS_TCM_HSE_AR, MESS_TCM_HSF_AR, MESS_TCM_HSG_AR, MESS_TCM_HSH_AR]
    TxNorm_TCM_POWERTRAIN: communication-direction=OUT, communication-mode=Normal, i-pdu=[PARK_Drv_Rs_TCM_AR2, ROE_TCM, SBW_DrvPosn_Disp_Rq_TCM_AR2, SBW_Resp_TCM_AR2, SBW_Stat_AR2, TCM_DAC4_AR, TCM_Data2_AR2, TCM_Data3_AR2, TCM_Data4_AR2, TCM_Data5_AR2, TCM_Disp_Rq_AMG_AR, TCM_EngIntrvntn2_AR2, TCM_EngIntrvntn_AR2, TCM_Rq1_AR, TCM_State3_AR2, TCM_WDC_Data_AR2]
    RxNorm_ASX_POWERTRAIN:
      communication-direction=IN
      communication-mode=Normal
      i-pdu=[APPL_ECU_ASX_1, CHASSIS_POWERTRAIN_R2_AR2, CHASSIS_POWERTRAIN_R3_AR2, CHASSIS_POWERTRAIN_R4_AR2, DRVU_Stat_AR2, Eng_Rs_2_PT_AR2, Eng_Rs_3_AR2, Eng_Rs_EngCtrl_AR2, EngCtrl_Stat_AR2, EVC_CfgBit_33_64_AR2, EVC_CfgList_01_0C_AR2, IC_BasicInfo_AR2, Ign_Veh_Stat_AR2, PN14_Stat_AR, PtMngmnt_Rq_AR2, PtMngmnt_Stat_AR2, PW_XX_Stat_AR2, TCM_Data2_AR2, TCM_EngIntrvntn_AR2, VIN_AR]
    RxNorm_CPC_POWERTRAIN:
      communication-direction=IN
      communication-mode=Normal
      i-pdu=[ASX_Stat_AR, ECM_DAC4_AR, Eng_Rs4_AR2, Eng_Rs_EngCtrl_AR2, EngCtrl_Eng_Stat_AR, EngCtrl_OBD1_AR, EngCtrl_Stat4_AR2, EngCtrl_Stat_AR2, FFAP_Stat_AR, FuelLvl_Stat_AR2, ISM_DAC4_AR, LDC_SBW_Rq_DRVU_AR2, PARK_Drv_Rs_TCM_AR2, PT_ThermM_AR2, ROE_ASX, ROE_AWD, ROE_FFAP, ROE_FSCM, ROE_ISM, ROE_TCM, SBW_DrvPosn_Disp_Rq_ISM_AR2, SBW_DrvPosn_Disp_Rq_TCM_AR2, SBW_Stat_AR2, TCM_DAC4_AR, TCM_Data2_AR2, TCM_Data3_AR2, TCM_Data4_AR2, TCM_Data5_AR2, TCM_Disp_Rq_AMG_AR, TCM_EngIntrvntn2_AR2, TCM_EngIntrvntn_AR2, TCM_State3_AR2, TCM_WDC_Data_AR2, Tx_Rq_PtMngmnt_ECM_AR2, VehPwrMngmnt_Rq_AR]
    RxNorm_DRVU_POWERTRAIN: communication-direction=IN, communication-mode=Normal, i-pdu=[Eng_Rs_1_PT_AR2, Eng_Rs_3_AR2, Eng_Rs_EngCtrl_AR2, PtMngmnt_Rq_AR2, PtMngmnt_Stat_AR2, SBW_DrvPosn_Disp_Rq_ISM_AR2, SBW_DrvPosn_Disp_Rq_TCM_AR2, TCM_Data2_AR2, TCM_Data3_AR2, TCM_Disp_Rq_AMG_AR, TCM_EngIntrvntn_AR2, TCM_State3_AR2, TCM_WDC_Data_AR2]
    RxNorm_ECM_POWERTRAIN:
      communication-direction=IN
      communication-mode=Normal
      i-pdu=[AWD_TCASE_Stat1_AR2, BrkSys_Stat_AR2, CHASSIS_POWERTRAIN_R1_AR2, CHASSIS_POWERTRAIN_R2_AR2, DAC4_ECM_AR, DRVU_Stat_AR2, EM01_Stat1_AR2, EM_PtMngmnt_Rq_AR2, Eng_Rs_2_PT_AR2, Eng_Rs_3_AR2, EngCtrl_OBD4_AR2, EPKB_Stat_AR2, EVC_CfgBit_01_32_AR2, EVC_CfgList_01_0C_AR2, FBL_Cfg_Star2_AR, FSCM_DTC_OBD_AR2, Fuel_Stat_AR2, FuelLvl_Stat_AR2, HVAC_Rs_AR2, IC_BasicInfo_AR2, Ign_Veh_Stat_AR2, LDC_SBW_Rq_SCCM_AR2, PARK_Drv_Rq_ESP_AR2, PN14_Stat2_AR2, PN14_Stat_AR, PT_DATA_AR2, PtMngmnt_Rq_AR2, PtMngmnt_Stat2_AR2, PtMngmnt_Stat_AR2, RTC_Stat1_AR2, SBW_DrvPosn_Disp_Rq_TCM_AR2, SBW_Stat_AR2, TCM_Data2_AR2, TCM_Data3_AR2, TCM_EngIntrvntn2_AR2, TCM_EngIntrvntn_AR2, TCM_State3_AR2, TCM_WDC_Data_AR2, VehDyn_Stat1_AR2, VehDyn_Stat2_AR2, Whl_Lt_Stat_AR2, Whl_Rt_Stat_AR2]
    RxNorm_FFAP_STAR_2_POWERTRAIN: communication-direction=IN, communication-mode=Normal, i-pdu=[BrkSys_Stat_AR2, Eng_Rs_3_AR2, Eng_Rs_EngCtrl_AR2, FFAP_Rq_AR, IC_BasicInfo_AR2, Ign_Veh_Stat_AR2, PN14_Stat_AR]
    RxNorm_FSCM_POWERTRAIN: communication-direction=IN, communication-mode=Normal, i-pdu=[Eng_Rs_2_PT_AR2, Eng_Rs_EngCtrl_AR2, EngCtrl_Eng_Stat_AR, EngCtrl_OBD1_AR, EngCtrl_OBD4_AR2, EngCtrl_Stat3_AR, EngCtrl_Stat4_AR2, EngCtrl_Stat_AR2, IC_BasicInfo_AR2, Ign_Veh_Stat_AR2, PN14_Stat2_AR2, PN14_Stat_AR, PT_ThermM_AR2, PtMngmnt_Stat_AR2, RTC_Stat1_AR2, VehDyn_Stat1_AR2, VIN_AR]
    RxNorm_ISM_POWERTRAIN:
      communication-direction=IN
      communication-mode=Normal
      i-pdu=[APPL_ECU_ISM1, APPL_ECU_ISM2, BrkSys_Stat_AR2, CHASSIS_POWERTRAIN_R1_AR2, CPC_PredStrat_Data_AR2, DAC4_ISM_AR, Eng_Rs_EngCtrl_AR2, EPKB_Stat_AR2, IC_BasicInfo_AR2, Ign_Veh_Stat_AR2, LDC_SBW_Rq_DRVU_AR2, LDC_SBW_Rq_SCCM_AR2, PARK_Drv_Rq_ESP_AR2, PN14_Stat_AR, PtMngmnt_Stat_AR2, SBW_Resp_TCM_AR2, Tx_Rq_PtMngmnt_ECM_AR2, VehDyn_Stat1_AR2, VehDyn_Stat2_AR2, Whl_Lt_Stat_AR2, Whl_Rt_Stat_AR2]
    RxNorm_SSP_POWERTRAIN: communication-direction=IN, communication-mode=Normal, i-pdu=[APPL_ECU_SSP_1, TCM_Rq1_AR]
    RxNorm_TCM_POWERTRAIN:
      communication-direction=IN
      communication-mode=Normal
      i-pdu=[AWD_TCASE_Stat1_AR2, BrkSys_Stat_AR2, CHASSIS_POWERTRAIN_R1_AR2, CHASSIS_POWERTRAIN_R2_AR2, CHASSIS_POWERTRAIN_R3_AR2, CHASSIS_POWERTRAIN_R4_AR2, CPC_PredStrat_Data_AR2, DAC4_TCM_AR, DPC_SHW_Rq2_AR2, DwnShft_Corr_AR2, EM01_Stat1_AR2, EM_PtMngmnt_Rq_AR2, Eng_Rs4_AR2, Eng_Rs_1_PT_AR2, Eng_Rs_2_PT_AR2, Eng_Rs_3_AR2, Eng_Rs_EngCtrl_AR2, EngCtrl_Eng_Stat_AR, EngCtrl_OBD1_AR, EngCtrl_OBD4_AR2, EngCtrl_Stat4_AR2, EngCtrl_Stat_AR2, EPKB_Stat_AR2, EVC_CfgBit_01_32_AR2, EVC_CfgBit_65_96_AR2, EVC_CfgList_01_0C_AR2, FFAP_Rq_AR, HVAC_Rs_AR2, HYBRID_POWERTRAIN_R1_AR2, IC_BasicInfo_AR2, Ign_Veh_Stat_AR2, LDC_SBW_Rq_DRVU_AR2, LDC_SBW_Rq_SCCM_AR2, MESS_TCM_HS1_AR, MESS_TCM_HS2_AR, MESS_TCM_HS3_AR, MESS_TCM_HS4_AR, MESS_TCM_HS5_AR, MESS_TCM_HS6_AR, MESS_TCM_HS7_AR, MESS_TCM_HS8_AR, PARK_Drv_Rq_ESP_AR2, PN14_Stat2_AR2, PN14_Stat_AR, PT_DATA_AR2, PT_ThermM_AR2, PtMngmnt_Rq_AR2, PtMngmnt_Stat2_AR2, PtMngmnt_Stat_AR2, RTC_Stat1_AR2, SBW_DrvPosn_Disp_Rq_CPC_AR2, SBW_Stat_AR2, SSP_Rs_AR, StWhl_Angl_Stat_AR2, Tx_Rq_PtMngmnt_ECM_AR2, UpShft_Corr_AR2, VehDyn_Stat1_AR2, VehDyn_Stat2_AR2, VehPwrMngmnt_Rq_AR, VIN_AR, Whl_Lt_Stat_AR2, Whl_Rt_Stat_AR2]
    RxNorm_TGW_POWERTRAIN: communication-direction=IN, communication-mode=Normal, i-pdu=[Eng_Rs_2_PT_AR2, Eng_Rs_EngCtrl_AR2, PtMngmnt_Rq_AR2, PtMngmnt_Stat_AR2, PW_XX_Stat_AR2, TCM_EngIntrvntn_AR2]
package /END_2_END_PROTECTION
  end to end protection set END_2END_PROTECTION_SET
    44 x end to end protection:
      XDIS_584DE62B509A3D04807969D0645B229E: end-to-end-profile={category=PROFILE_02, data-ids=[9, 59, 109, 159, 209, 8, 58, 108, 158, 208, 7, 57, 107, 157, 207, 6], data-length=40, max-delta-counter-init=15}, end-to-end-protection-i-signal-i-pdu{data-offset=0, i-signal-group=AWD_TCASE_Stat1_Pr2_3ufw8rot8ihm8nnppmgv2dnz0, i-signal-i-pdu=AWD_TCASE_Stat1_AR2}
      XDIS_B819E09A5B1E307586374EE5A558E197: end-to-end-profile={category=PROFILE_02, data-ids=[61, 57, 53, 49, 45, 41, 37, 33, 29, 25, 21, 17, 13, 9, 5, 252], data-length=64, max-delta-counter-init=15, max-no-new-or-repeated-data=15, sync-counter-init=0}, end-to-end-protection-i-signal-i-pdu{data-offset=0, i-signal-group=BrkSys_Stat_Pr2_7r9ilu941lyckw1hfocaygals, i-signal-i-pdu=BrkSys_Stat_AR2}
      XDIS_BC02E6A3405A337287BFF16E09DEF840: end-to-end-profile={category=PROFILE_02, data-ids=[39, 136, 233, 79, 176, 22, 119, 216, 62, 159, 5, 102, 199, 45, 142, 239], data-length=32, max-delta-counter-init=15, max-no-new-or-repeated-data=15, sync-counter-init=0}, end-to-end-protection-i-signal-i-pdu{data-offset=0, i-signal-group=ParkCfg_Stat_Pr2_5onkeem8aikyiyd802x686qlp, i-signal-i-pdu=CHASSIS_POWERTRAIN_R2_AR2}
      XDIS_EDC38ED693563F0F82E4A8DD26648227: end-to-end-profile={category=PROFILE_02, data-ids=[127, 132, 137, 142, 147, 152, 157, 162, 167, 172, 177, 182, 187, 192, 197, 202], data-length=48, max-delta-counter-init=15}, end-to-end-protection-i-signal-i-pdu{data-offset=0, i-signal-group=SHW_Rq2_Pr2_25eo2jxdt9eomhrgzz8hck6us, i-signal-i-pdu=DPC_SHW_Rq2_AR2}
      XDIS_83977DD6F24E3386860CAD1F6CABBA95: end-to-end-profile={category=PROFILE_02, data-ids=[117, 59, 252, 194, 136, 78, 20, 213, 155, 97, 39, 232, 174, 116, 58, 251], data-length=64, max-delta-counter-init=15, max-no-new-or-repeated-data=15, sync-counter-init=0}, end-to-end-protection-i-signal-i-pdu{data-offset=0, i-signal-group=EM01_Stat1_Pr2_4hvri6w0u2vqjawx4ll81022i, i-signal-i-pdu=EM01_Stat1_AR2}
      XDIS_78A64F32F3A23537B2ACB4E11B3618FE: end-to-end-profile={category=PROFILE_02, data-ids=[76, 178, 29, 131, 233, 84, 186, 37, 139, 241, 92, 194, 45, 147, 249, 100], data-length=64, max-delta-counter-init=15, max-no-new-or-repeated-data=15, sync-counter-init=0}, end-to-end-protection-i-signal-i-pdu{data-offset=0, i-signal-group=EM_PtMngmnt_Pr2_3wxzgy1jeqdhai2x3bxoim0oa, i-signal-i-pdu=EM_PtMngmnt_Rq_AR2}
      XDIS_C2BBA60EA5AA39C0ACAC23E113139C88: end-to-end-profile={category=PROFILE_02, data-ids=[33, 212, 140, 68, 247, 175, 103, 31, 210, 138, 66, 245, 173, 101, 29, 208], data-length=64, max-delta-counter-init=15}, end-to-end-protection-i-signal-i-pdu{data-offset=0, i-signal-group=Eng_Rs4_Pr2_dg8les6g8bd4zh1pem3ucc29t, i-signal-i-pdu=Eng_Rs4_AR2}
      XDIS_A0655A7E59DA3DA2BEEFBE789A06ECD1: end-to-end-profile={category=PROFILE_02, data-ids=[93, 200, 56, 163, 19, 126, 233, 89, 196, 52, 159, 15, 122, 229, 85, 192], data-length=64, max-delta-counter-init=15, max-no-new-or-repeated-data=15, sync-counter-init=0}, end-to-end-protection-i-signal-i-pdu{data-offset=0, i-signal-group=Eng_Rs1_PT_Pr2_cf9mw3gecnkesr53zjhm61sph, i-signal-i-pdu=Eng_Rs_1_PT_AR2}
      XDIS_59E1DF7F3ED63DF38708A231FE1EAD1E: end-to-end-profile={category=PROFILE_02, data-ids=[211, 83, 206, 78, 201, 73, 196, 68, 191, 63, 186, 58, 181, 53, 176, 48], data-length=64, max-delta-counter-init=15, max-no-new-or-repeated-data=15, sync-counter-init=0}, end-to-end-protection-i-signal-i-pdu{data-offset=0, i-signal-group=Eng_Rs2_PT_Pr2_a8h33xdavwvlmc583w9zxcagw, i-signal-i-pdu=Eng_Rs_2_PT_AR2}
      XDIS_AFB202DF31C0341D91045DD9B141DD4F: end-to-end-profile={category=PROFILE_02, data-ids=[185, 143, 101, 59, 17, 226, 184, 142, 100, 58, 16, 225, 183, 141, 99, 57], data-length=40, max-delta-counter-init=15, max-no-new-or-repeated-data=15, sync-counter-init=0}, end-to-end-protection-i-signal-i-pdu{data-offset=0, i-signal-group=Eng_Rs3_Pr2_dbt1hpurrces52skcqo6f7f6g, i-signal-i-pdu=Eng_Rs_3_AR2}
      XDIS_C0D29C43F09B31D4AC97FF0EC6BBB4A7: end-to-end-profile={category=PROFILE_02, data-ids=[199, 227, 4, 32, 60, 88, 116, 144, 172, 200, 228, 5, 33, 61, 89, 117], data-length=64, max-delta-counter-init=15, max-no-new-or-repeated-data=15, sync-counter-init=0}, end-to-end-protection-i-signal-i-pdu{data-offset=0, i-signal-group=Eng_Rs_EngCtrl_Pr2_1g6e1wh7aspfj509n9mt9fl55, i-signal-i-pdu=Eng_Rs_EngCtrl_AR2}
      XDIS_008D6A41CC003F4B9A48E0E34F1B0BEC: end-to-end-profile={category=PROFILE_02, data-ids=[130, 125, 120, 115, 110, 105, 100, 95, 90, 85, 80, 75, 70, 65, 60, 55], data-length=32, max-delta-counter-init=15, max-no-new-or-repeated-data=15, sync-counter-init=0}, end-to-end-protection-i-signal-i-pdu{data-offset=0, i-signal-group=Fuel_Rq_Pr2_eypyqep6qt2njcbx8m8j4hfby, i-signal-i-pdu=EngCtrl_Stat4_AR2}
      XDIS_2D0B7E08E12D302593416700C9A4A1EF: end-to-end-profile={category=PROFILE_02, data-ids=[27, 58, 89, 120, 151, 182, 213, 244, 24, 55, 86, 117, 148, 179, 210, 241], data-length=64, max-delta-counter-init=15, max-no-new-or-repeated-data=15, sync-counter-init=0}, end-to-end-protection-i-signal-i-pdu{data-offset=0, i-signal-group=EPKB_Stat_Pr2_9vocfbztwmx64yya8hopavqwq, i-signal-i-pdu=EPKB_Stat_AR2}
      XDIS_A948C9D9B0B6346895A00F71D52A4CC5: end-to-end-profile={category=PROFILE_02, data-ids=[153, 210, 16, 73, 130, 187, 244, 50, 107, 164, 221, 27, 84, 141, 198, 4], data-length=64, max-delta-counter-init=15, max-no-new-or-repeated-data=15, sync-counter-init=0}, end-to-end-protection-i-signal-i-pdu{data-offset=0, i-signal-group=EVC_CfgBit_01_32_Pr2_bczisb61ims7titum6cc8o5oq, i-signal-i-pdu=EVC_CfgBit_01_32_AR2}
      XDIS_D4EA50CB3A323273A3D88A158B856AB5: end-to-end-profile={category=PROFILE_02, data-ids=[83, 104, 125, 146, 167, 188, 209, 230, 251, 21, 42, 63, 84, 105, 126, 147], data-length=64, max-delta-counter-init=15, max-no-new-or-repeated-data=15, sync-counter-init=0}, end-to-end-protection-i-signal-i-pdu{data-offset=0, i-signal-group=EVC_CfgBit_33_64_Pr2_6j1ey0vfxblk9wf2gvnbh92fe, i-signal-i-pdu=EVC_CfgBit_33_64_AR2}
      XDIS_FACC06C001AD30DBB97271698296AD9C: end-to-end-profile={category=PROFILE_02, data-ids=[35, 85, 135, 185, 235, 34, 84, 134, 184, 234, 33, 83, 133, 183, 233, 32], data-length=64, max-delta-counter-init=15, max-no-new-or-repeated-data=15, sync-counter-init=0}, end-to-end-protection-i-signal-i-pdu{data-offset=0, i-signal-group=EVC_CfgBit_65_96_Pr2_av2hye5lktbglj5y8o60nsl17, i-signal-i-pdu=EVC_CfgBit_65_96_AR2}
      XDIS_F4686C44C31E302C8D042AAE9E30DF3E: end-to-end-profile={category=PROFILE_02, data-ids=[198, 92, 237, 131, 25, 170, 64, 209, 103, 248, 142, 36, 181, 75, 220, 114], data-length=64, max-delta-counter-init=15, max-no-new-or-repeated-data=15, sync-counter-init=0}, end-to-end-protection-i-signal-i-pdu{data-offset=0, i-signal-group=EVC_CfgList_01_0C_Pr2_3qvfhaj56jpqdd0izhj6fs0z3, i-signal-i-pdu=EVC_CfgList_01_0C_AR2}
      XDIS_3C4ED191150E3C7B81C6574A8B0AF7CC: end-to-end-profile={category=PROFILE_02, data-ids=[114, 24, 185, 95, 5, 166, 76, 237, 147, 57, 218, 128, 38, 199, 109, 19], data-length=24, max-delta-counter-init=15, max-no-new-or-repeated-data=15, sync-counter-init=0}, end-to-end-protection-i-signal-i-pdu{data-offset=0, i-signal-group=HVAC_CompTrq_Pr2_c82iy4u15nkwuh8st1cqydegx, i-signal-i-pdu=HVAC_Rs_AR2}
      XDIS_D7411B8793DE3F2BBF659D00E19585C7: end-to-end-profile={category=PROFILE_02, data-ids=[167, 211, 4, 48, 92, 136, 180, 224, 17, 61, 105, 149, 193, 237, 30, 74], data-length=32, max-delta-counter-init=15, max-no-new-or-repeated-data=15, sync-counter-init=0}, end-to-end-protection-i-signal-i-pdu{data-offset=0, i-signal-group=Ign_Stat_Pr2_457i75qk4uen9ahb37ecxdhxz, i-signal-i-pdu=Ign_Veh_Stat_AR2}
      XDIS_A7626236DB343751B6BE0422320A7994: end-to-end-profile={category=PROFILE_02, data-ids=[155, 237, 68, 150, 232, 63, 145, 227, 58, 140, 222, 53, 135, 217, 48, 130], data-length=32, max-delta-counter-init=15, max-no-new-or-repeated-data=15, sync-counter-init=0}, end-to-end-protection-i-signal-i-pdu{data-offset=0, i-signal-group=SBW_Rq_DRVU_Pr2_71okqqkd28hyyebm190lxt3vd, i-signal-i-pdu=LDC_SBW_Rq_DRVU_AR2}
      XDIS_2B03E4A7A9ED3B6DB84F9F4393575832: end-to-end-profile={category=PROFILE_02, data-ids=[178, 38, 149, 9, 120, 231, 91, 202, 62, 173, 33, 144, 4, 115, 226, 86], data-length=32, max-delta-counter-init=15, max-no-new-or-repeated-data=15, sync-counter-init=0}, end-to-end-protection-i-signal-i-pdu{data-offset=0, i-signal-group=LDC_Rq_SCCM_Pr2_1urxjv3xbtzkrxlqmdhowxf5n, i-signal-i-pdu=LDC_SBW_Rq_SCCM_AR2}
      XDIS_727DDEEBC3643D938ADE31F579ED8353: end-to-end-profile={category=PROFILE_02, data-ids=[124, 182, 240, 47, 105, 163, 221, 28, 86, 144, 202, 9, 67, 125, 183, 241], data-length=32, max-delta-counter-init=15, max-no-new-or-repeated-data=15, sync-counter-init=0}, end-to-end-protection-i-signal-i-pdu{data-offset=32, i-signal-group=SBW_Rq_SCCM_Pr2_1bw4xg1pomod9nov43ee8m7kx, i-signal-i-pdu=LDC_SBW_Rq_SCCM_AR2}
      XDIS_FDA78246E363375692A462412E018959: end-to-end-profile={category=PROFILE_02, data-ids=[126, 20, 165, 59, 204, 98, 243, 137, 31, 176, 70, 215, 109, 3, 148, 42], data-length=64, max-delta-counter-init=15, max-no-new-or-repeated-data=15, sync-counter-init=0}, end-to-end-protection-i-signal-i-pdu{data-offset=0, i-signal-group=PARK_Drv_Rq_ESP_Pr2_156rahkn2e7mmvc2542gbao5u, i-signal-i-pdu=PARK_Drv_Rq_ESP_AR2}
      XDIS_AAEDF81195293335A5391C5BDFC0F28D: end-to-end-profile={category=PROFILE_02, data-ids=[205, 189, 173, 157, 141, 125, 109, 93, 77, 61, 45, 29, 13, 248, 232, 216], data-length=40, max-delta-counter-init=15, max-no-new-or-repeated-data=15, sync-counter-init=0}, end-to-end-protection-i-signal-i-pdu{data-offset=0, i-signal-group=PARK_Drv_Rs_TCM_Pr2_oe4nkdc61vmdsai3dvff2tvs, i-signal-i-pdu=PARK_Drv_Rs_TCM_AR2}
      XDIS_B84BE269F8DA3496839C8E8A725B96D9: end-to-end-profile={category=PROFILE_02, data-ids=[93, 49, 5, 212, 168, 124, 80, 36, 243, 199, 155, 111, 67, 23, 230, 186], data-length=40, max-delta-counter-init=15, max-no-new-or-repeated-data=15, sync-counter-init=0}, end-to-end-protection-i-signal-i-pdu{data-offset=0, i-signal-group=PtMngmnt_Rq_Pr2_czcqfhcxlfzoeyleoslpc91wg, i-signal-i-pdu=PtMngmnt_Rq_AR2}
      XDIS_D54B20E9D1FD3CBF9C0744458D3BA48E: end-to-end-profile={category=PROFILE_02, data-ids=[214, 144, 74, 4, 185, 115, 45, 226, 156, 86, 16, 197, 127, 57, 238, 168], data-length=48, max-delta-counter-init=15, max-no-new-or-repeated-data=15, sync-counter-init=0}, end-to-end-protection-i-signal-i-pdu{data-offset=0, i-signal-group=PtMngmnt_Stat2_Pr2_52pi4z2we5iyfdnzwhqxb6f78, i-signal-i-pdu=PtMngmnt_Stat2_AR2}
      XDIS_E4967D71367837F9BDF3322D0D041F19: end-to-end-profile={category=PROFILE_02, data-ids=[18, 46, 74, 102, 130, 158, 186, 214, 242, 19, 47, 75, 103, 131, 159, 187], data-length=16, max-delta-counter-init=15, max-no-new-or-repeated-data=15, sync-counter-init=0}, end-to-end-protection-i-signal-i-pdu{data-offset=48, i-signal-group=PT_Stat_Pr2_3par937a8yr160hqtiylu66k8, i-signal-i-pdu=PtMngmnt_Stat_AR2}
      XDIS_B0F65F5BDF123FFFA0202ACA718E8829: end-to-end-profile={category=PROFILE_02, data-ids=[216, 129, 42, 206, 119, 32, 196, 109, 22, 186, 99, 12, 176, 89, 253, 166], data-length=32, max-delta-counter-init=15, max-no-new-or-repeated-data=15, sync-counter-init=0}, end-to-end-protection-i-signal-i-pdu{data-offset=0, i-signal-group=SBW_Drv_Pk_Posn_CPC_Pr2_acd3oordbhg0yjkmuwx4u8jib, i-signal-i-pdu=SBW_DrvPosn_Disp_Rq_CPC_AR2}
      XDIS_ED67F6B7066D3D93A59D6A3C729A7717: end-to-end-profile={category=PROFILE_02, data-ids=[97, 226, 104, 233, 111, 240, 118, 247, 125, 3, 132, 10, 139, 17, 146, 24], data-length=24, max-delta-counter-init=15, max-no-new-or-repeated-data=15, sync-counter-init=0}, end-to-end-protection-i-signal-i-pdu{data-offset=0, i-signal-group=ISM_TxDrvPosn_Disp_Rq_Pr2_epuwuk6swsjmfffk3fikh4w52, i-signal-i-pdu=SBW_DrvPosn_Disp_Rq_ISM_AR2}
      XDIS_2C2220C8C1113AEB8ABF2F5E2D8A4868: end-to-end-profile={category=PROFILE_02, data-ids=[239, 121, 3, 136, 18, 151, 33, 166, 48, 181, 63, 196, 78, 211, 93, 226], data-length=24, max-delta-counter-init=15, max-no-new-or-repeated-data=15, sync-counter-init=0}, end-to-end-protection-i-signal-i-pdu{data-offset=0, i-signal-group=SBW_Drv_Pk_Posn_TCM_Pr2_87jwxqxlzqql6r2vkjah89c7p, i-signal-i-pdu=SBW_DrvPosn_Disp_Rq_TCM_AR2}
      XDIS_E661F36CEAB13411BBA9336B319BD510: end-to-end-profile={category=PROFILE_02, data-ids=[96, 229, 111, 244, 126, 8, 141, 23, 156, 38, 171, 53, 186, 68, 201, 83], data-length=40, max-delta-counter-init=15, max-no-new-or-repeated-data=15, sync-counter-init=0}, end-to-end-protection-i-signal-i-pdu{data-offset=0, i-signal-group=SBW_Rs_TCM_Pr2_dym3b88zatlkmtnb9qcuvfn90, i-signal-i-pdu=SBW_Resp_TCM_AR2}
      XDIS_99D3EADDF54E3CE19EC8B52F2B7A81CA: end-to-end-profile={category=PROFILE_02, data-ids=[216, 66, 167, 17, 118, 219, 69, 170, 20, 121, 222, 72, 173, 23, 124, 225], data-length=64, max-delta-counter-init=15, max-no-new-or-repeated-data=15, sync-counter-init=0}, end-to-end-protection-i-signal-i-pdu{data-offset=0, i-signal-group=SBW_Stat_Pr2_ecnxwrof0tv45hxypgialh6k2, i-signal-i-pdu=SBW_Stat_AR2}
      XDIS_7D53386FBC613F5AACC2748266F011BF: end-to-end-profile={category=PROFILE_02, data-ids=[39, 7, 226, 194, 162, 130, 98, 66, 34, 253, 221, 189, 157, 125, 93, 61], data-length=64, max-delta-counter-init=15, max-no-new-or-repeated-data=15, sync-counter-init=0}, end-to-end-protection-i-signal-i-pdu{data-offset=0, i-signal-group=StWhl_Angl_Stat_Pr2_c4qb7b59jfa5oc3ih83ubw184, i-signal-i-pdu=StWhl_Angl_Stat_AR2}
      XDIS_2296754C4D3E3E48AC5A2CBCD37A209F: end-to-end-profile={category=PROFILE_02, data-ids=[54, 199, 93, 238, 132, 26, 171, 65, 210, 104, 249, 143, 37, 182, 76, 221], data-length=64, max-delta-counter-init=15, max-no-new-or-repeated-data=15, sync-counter-init=0}, end-to-end-protection-i-signal-i-pdu{data-offset=0, i-signal-group=TCM_Data2_Pr2_3aes4m38p3xyalmhl6p5hhgww, i-signal-i-pdu=TCM_Data2_AR2}
      XDIS_B1716C00BBE032A390A1EE79BA5DBCD6: end-to-end-profile={category=PROFILE_02, data-ids=[246, 18, 41, 64, 87, 110, 133, 156, 179, 202, 225, 248, 20, 43, 66, 89], data-length=40, max-delta-counter-init=15, max-no-new-or-repeated-data=15, sync-counter-init=0}, end-to-end-protection-i-signal-i-pdu{data-offset=0, i-signal-group=TCM_Data3_Pr2_4mdu2ave4pajazfn4q4pmyvzw, i-signal-i-pdu=TCM_Data3_AR2}
      XDIS_146880DDDE4835AA9EAD02449E95A9A4: end-to-end-profile={category=PROFILE_02, data-ids=[122, 66, 10, 205, 149, 93, 37, 232, 176, 120, 64, 8, 203, 147, 91, 35], data-length=24, max-delta-counter-init=15, max-no-new-or-repeated-data=15, sync-counter-init=0}, end-to-end-protection-i-signal-i-pdu{data-offset=0, i-signal-group=TCM_Data5_Pr2_c73komxr1qix41zrytxs0vhwu, i-signal-i-pdu=TCM_Data5_AR2}
      XDIS_64E70CE376F1339EAD7797C1E85AF4D3: end-to-end-profile={category=PROFILE_02, data-ids=[17, 156, 44, 183, 71, 210, 98, 237, 125, 13, 152, 40, 179, 67, 206, 94], data-length=32, max-delta-counter-init=15}, end-to-end-protection-i-signal-i-pdu{data-offset=0, i-signal-group=TrqConv_Pr2_d41hb9de6igapvaa0xr920t3b, i-signal-i-pdu=TCM_EngIntrvntn2_AR2}
      XDIS_58C0262C5E6938F2BAD319868B2672B1: end-to-end-profile={category=PROFILE_02, data-ids=[86, 94, 102, 110, 118, 126, 134, 142, 150, 158, 166, 174, 182, 190, 198, 206], data-length=64, max-delta-counter-init=15, max-no-new-or-repeated-data=15, sync-counter-init=0}, end-to-end-protection-i-signal-i-pdu{data-offset=0, i-signal-group=TCM_EngIntrvntn_Pr2_3yr5mxltfyr8h8xlszlge0nzx, i-signal-i-pdu=TCM_EngIntrvntn_AR2}
      XDIS_857BF6DCBEED3016B576C4B84F9AAF3A: end-to-end-profile={category=PROFILE_02, data-ids=[36, 198, 109, 20, 182, 93, 4, 166, 77, 239, 150, 61, 223, 134, 45, 207], data-length=64, max-delta-counter-init=15, max-no-new-or-repeated-data=15, sync-counter-init=0}, end-to-end-protection-i-signal-i-pdu{data-offset=0, i-signal-group=TCM_WDC_Data_Pr2_cdb1pod9rsur54rd7agdaayel, i-signal-i-pdu=TCM_WDC_Data_AR2}
      XDIS_FA1D625816D53E49948768CDE85200F5: end-to-end-profile={category=PROFILE_02, data-ids=[181, 91, 252, 162, 72, 233, 143, 53, 214, 124, 34, 195, 105, 15, 176, 86], data-length=40, max-delta-counter-init=15, max-no-new-or-repeated-data=15, sync-counter-init=0}, end-to-end-protection-i-signal-i-pdu{data-offset=0, i-signal-group=Tx_Rq_PtMngmnt_ECM_Pr2_esuvr5ltdwin8dor1y7m13584, i-signal-i-pdu=Tx_Rq_PtMngmnt_ECM_AR2}
      XDIS_5891B7BBE20733F3BE86630D1BE484FB: end-to-end-profile={category=PROFILE_02, data-ids=[124, 120, 116, 112, 108, 104, 100, 96, 92, 88, 84, 80, 76, 72, 68, 64], data-length=64, max-delta-counter-init=15, max-no-new-or-repeated-data=15, sync-counter-init=0}, end-to-end-protection-i-signal-i-pdu{data-offset=0, i-signal-group=VehDyn_Stat1_Pr2_b566uuutl7t3vy8bytjwtuogy, i-signal-i-pdu=VehDyn_Stat1_AR2}
      XDIS_2F76567C9E4F3EADAC414D05A6BC56ED: end-to-end-profile={category=PROFILE_02, data-ids=[163, 16, 120, 224, 77, 181, 34, 138, 242, 95, 199, 52, 156, 9, 113, 217], data-length=64, max-delta-counter-init=15, max-no-new-or-repeated-data=15, sync-counter-init=0}, end-to-end-protection-i-signal-i-pdu{data-offset=0, i-signal-group=VehDyn_Stat2_Pr2_10f6ms25t3ycbau4qljpm984z, i-signal-i-pdu=VehDyn_Stat2_AR2}
      XDIS_945CA3C9B10739568F588B6FEFDE2C47: end-to-end-profile={category=PROFILE_02, data-ids=[135, 212, 38, 115, 192, 18, 95, 172, 249, 75, 152, 229, 55, 132, 209, 35], data-length=64, max-delta-counter-init=15, max-no-new-or-repeated-data=15, sync-counter-init=0}, end-to-end-protection-i-signal-i-pdu{data-offset=0, i-signal-group=Whl_Lt_Stat_Pr2_s0yl1k4cam60smahrd06qo1g, i-signal-i-pdu=Whl_Lt_Stat_AR2}
      XDIS_DD9398D1E4003FCDB711566768314FDD: end-to-end-profile={category=PROFILE_02, data-ids=[39, 128, 217, 55, 144, 233, 71, 160, 249, 87, 176, 14, 103, 192, 30, 119], data-length=64, max-delta-counter-init=15, max-no-new-or-repeated-data=15, sync-counter-init=0}, end-to-end-protection-i-signal-i-pdu{data-offset=0, i-signal-group=Whl_Rt_Stat_Pr2_5rdhw8834wvrtpb3zqsdx2byz, i-signal-i-pdu=Whl_Rt_Stat_AR2}
package /SYSTEM
  system SYSTEM_XDIS: fibex-element=[ASX, CPC, DRVU, ECM, FFAP_STAR_2, FSCM, ISM, SSP, TCM, TGW, APPL_ECU_ASX_1, APPL_ECU_ISM1, APPL_ECU_ISM2, APPL_ECU_SSP_1, ASX_Stat_AR, AWD_TCASE_Stat1_AR2, BrkSys_Stat_AR2, CHASSIS_POWERTRAIN_R1_AR2, CHASSIS_POWERTRAIN_R2_AR2, CHASSIS_POWERTRAIN_R3_AR2, CHASSIS_POWERTRAIN_R4_AR2, CPC_PredStrat_Data_AR2, DAC4_ECM_AR, DAC4_ISM_AR, DAC4_TCM_AR, DIAG_RQ_ASX, DIAG_RQ_AWD, DIAG_RQ_FFAP, DIAG_RQ_FSCM, DIAG_RQ_GLOBAL_UDS, DIAG_RQ_ISM, DIAG_RQ_TCM, DIAG_RS_ASX, DIAG_RS_AWD, DIAG_RS_FFAP, DIAG_RS_FSCM, DIAG_RS_ISM, DIAG_RS_TCM, DIAGX_RQ_FSCM_OBD, DIAGX_RQ_GLOBAL_OBD, DIAGX_RQ_TCM_OBD, DIAGX_RS_FSCM_OBD, DIAGX_RS_TCM_OBD, DPC_SHW_Rq2_AR2, DRVU_Stat_AR2, DwnShft_Corr_AR2, ECM_DAC4_AR, ECU_APPL_ASX_1, ECU_APPL_ISM1, ECU_APPL_ISM2, ECU_APPL_ISM3, ECU_APPL_SSP_1, EM01_Stat1_AR2, EM_PtMngmnt_Rq_AR2, Eng_Rs1_PT_AR2, Eng_Rs2_PT_AR2, Eng_Rs3_AR2, Eng_Rs4_AR2, Eng_Rs_EngCtrl_AR2, EngCtrl_Eng_Stat_AR, EngCtrl_OBD1_AR, EngCtrl_OBD4_AR2, EngCtrl_Stat3_AR, EngCtrl_Stat4_AR2, EngCtrl_Stat_AR2, EPKB_Stat_AR2, EVC_CfgBit_01_32_AR2, EVC_CfgBit_33_64_AR2, EVC_CfgBit_65_96_AR2, EVC_CfgList_01_0C_AR2, FBL_CFG_Star2_AR, FFAP_RQ_AR, FFAP_Stat_AR, FSCM_DTC_OBD_AR2, Fuel_Stat_AR2, FuelLvl_Stat_AR2, HVAC_Rs_AR2, HYBRID_POWERTRAIN_R1_AR2, IC_BasicInfo_AR2, Ign_Veh_Stat_AR2, ISM_DAC4_AR, LDC_SBW_Rq_DRVU_AR2, LDC_SBW_Rq_SCCM_AR2, Meas_SSP, MESS_TCM_HS1_AR, MESS_TCM_HS2_AR, MESS_TCM_HS3_AR, MESS_TCM_HS4_AR, MESS_TCM_HS5_AR, MESS_TCM_HS6_AR, MESS_TCM_HS7_AR, MESS_TCM_HS8_AR, MESS_TCM_HSA_AR, MESS_TCM_HSB_AR, MESS_TCM_HSC_AR, MESS_TCM_HSD_AR, MESS_TCM_HSE_AR, MESS_TCM_HSF_AR, MESS_TCM_HSG_AR, MESS_TCM_HSH_AR, NM_APPL_AR, NM_ASX_AR, NM_CPC_AR, NM_DRVU_AR, NM_ECM_AR, NM_FSCM_AR, NM_ISM_AR, NM_TCM_AR, PARK_Drv_Rq_ESP_AR2, PARK_Drv_Rs_TCM_AR2, PN14_Stat2_AR2, PN14_Stat_AR, PT_DATA_AR2, PT_ThermM_AR2, PtMngmnt_Rq_AR2, PtMngmnt_Stat2_AR2, PtMngmnt_Stat_AR2, PW_XX_Stat_AR2, ROE_ASX, ROE_AWD, ROE_FFAP, ROE_FSCM, ROE_ISM, ROE_TCM, RTC_Stat1_AR2, SBW_DrvPosn_Disp_Rq_CPC_AR2, SBW_DrvPosn_Disp_Rq_ISM_AR2, SBW_DrvPosn_Disp_Rq_TCM_AR2, SBW_Rs_TCM_AR2, SBW_Stat_AR2, SSP_RS_AR, StWhl_Angl_Stat_AR2, TCM_DAC4_AR, TCM_Data2_AR2, TCM_Data3_AR2, TCM_Data4_AR2, TCM_Data5_AR2, TCM_Disp_Rq_AMG_AR, TCM_EngIntrvntn2_AR2, TCM_EngIntrvntn_AR2, TCM_Rq1_AR, TCM_State3_AR2, TCM_WDC_Data_AR2, Tx_Rq_PtMngmnt_ECM_AR2, UpShft_Corr_AR2, VehDyn_Stat1_AR2, VehDyn_Stat2_AR2, VehPwrMngmnt_Rq_AR, VIN_AR, Whl_Lt_Stat_AR2, Whl_Rt_Stat_AR2, XCP_Rq_FFAP_1, XCP_Rq_FSCM, XCP_Rq_ISM, XCP_Rq_TCM, XCP_Rq_TCM2, XCP_Rs_FFAP_1, XCP_Rs_FFAP_2, XCP_Rs_FSCM, XCP_Rs_FSCM1, XCP_Rs_FSCM2, XCP_Rs_ISM, XCP_Rs_TCM, XCP_Rs_TCM2, XCP_Rs_TCM3, XCP_Rs_TCM4, XCP_Rs_TCM5, APPL_ECU_ASX_1, APPL_ECU_ISM1, APPL_ECU_ISM2, APPL_ECU_SSP_1, ASX_Stat_AR, AWD_TCASE_Stat1_AR2, BrkSys_Stat_AR2, CHASSIS_POWERTRAIN_R1_AR2, CHASSIS_POWERTRAIN_R2_AR2, CHASSIS_POWERTRAIN_R3_AR2, CHASSIS_POWERTRAIN_R4_AR2, CPC_PredStrat_Data_AR2, DAC4_ECM_AR, DAC4_ISM_AR, DAC4_TCM_AR, DPC_SHW_Rq2_AR2, DRVU_Stat_AR2, DwnShft_Corr_AR2, ECM_DAC4_AR, ECU_APPL_ASX_1, ECU_APPL_ISM1, ECU_APPL_ISM2, ECU_APPL_ISM3, ECU_APPL_SSP_1, EM01_Stat1_AR2, EM_PtMngmnt_Rq_AR2, Eng_Rs4_AR2, Eng_Rs_1_PT_AR2, Eng_Rs_2_PT_AR2, Eng_Rs_3_AR2, Eng_Rs_EngCtrl_AR2, EngCtrl_Eng_Stat_AR, EngCtrl_OBD1_AR, EngCtrl_OBD4_AR2, EngCtrl_Stat3_AR, EngCtrl_Stat4_AR2, EngCtrl_Stat_AR2, EPKB_Stat_AR2, EVC_CfgBit_01_32_AR2, EVC_CfgBit_33_64_AR2, EVC_CfgBit_65_96_AR2, EVC_CfgList_01_0C_AR2, FBL_Cfg_Star2_AR, FFAP_Rq_AR, FFAP_Stat_AR, FSCM_DTC_OBD_AR2, Fuel_Stat_AR2, FuelLvl_Stat_AR2, HVAC_Rs_AR2, HYBRID_POWERTRAIN_R1_AR2, IC_BasicInfo_AR2, Ign_Veh_Stat_AR2, ISM_DAC4_AR, LDC_SBW_Rq_DRVU_AR2, LDC_SBW_Rq_SCCM_AR2, Meas_SSP, MESS_TCM_HS1_AR, MESS_TCM_HS2_AR, MESS_TCM_HS3_AR, MESS_TCM_HS4_AR, MESS_TCM_HS5_AR, MESS_TCM_HS6_AR, MESS_TCM_HS7_AR, MESS_TCM_HS8_AR, MESS_TCM_HSA_AR, MESS_TCM_HSB_AR, MESS_TCM_HSC_AR, MESS_TCM_HSD_AR, MESS_TCM_HSE_AR, MESS_TCM_HSF_AR, MESS_TCM_HSG_AR, MESS_TCM_HSH_AR, PARK_Drv_Rq_ESP_AR2, PARK_Drv_Rs_TCM_AR2, PN14_Stat2_AR2, PN14_Stat_AR, PT_DATA_AR2, PT_ThermM_AR2, PtMngmnt_Rq_AR2, PtMngmnt_Stat2_AR2, PtMngmnt_Stat_AR2, PW_XX_Stat_AR2, ROE_ASX, ROE_AWD, ROE_FFAP, ROE_FSCM, ROE_ISM, ROE_TCM, RTC_Stat1_AR2, SBW_DrvPosn_Disp_Rq_CPC_AR2, SBW_DrvPosn_Disp_Rq_ISM_AR2, SBW_DrvPosn_Disp_Rq_TCM_AR2, SBW_Resp_TCM_AR2, SBW_Stat_AR2, SSP_Rs_AR, StWhl_Angl_Stat_AR2, TCM_DAC4_AR, TCM_Data2_AR2, TCM_Data3_AR2, TCM_Data4_AR2, TCM_Data5_AR2, TCM_Disp_Rq_AMG_AR, TCM_EngIntrvntn2_AR2, TCM_EngIntrvntn_AR2, TCM_Rq1_AR, TCM_State3_AR2, TCM_WDC_Data_AR2, Tx_Rq_PtMngmnt_ECM_AR2, UpShft_Corr_AR2, VehDyn_Stat1_AR2, VehDyn_Stat2_AR2, VehPwrMngmnt_Rq_AR, VIN_AR, Whl_Lt_Stat_AR2, Whl_Rt_Stat_AR2, SDU_DIAG_RQ_ASX_POWERTRAIN, SDU_DIAG_RQ_AWD_POWERTRAIN, SDU_DIAG_RQ_FFAP_PT, SDU_DIAG_RQ_FSCM_PT, SDU_DIAG_RQ_GLOBAL_UDS_PT, SDU_DIAG_RQ_ISM_PT, SDU_DIAG_RQ_TCM_PT, SDU_DIAG_RS_ASX_POWERTRAIN, SDU_DIAG_RS_AWD_POWERTRAIN, SDU_DIAG_RS_FFAP_PT, SDU_DIAG_RS_FSCM_PT, SDU_DIAG_RS_ISM_PT, SDU_DIAG_RS_TCM_PT, SDU_DIAGX_RQ_FSCM_OBD, SDU_DIAGX_RQ_GLOBAL_OBD, SDU_DIAGX_RQ_TCM_OBD, SDU_DIAGX_RS_FSCM_OBD, SDU_DIAGX_RS_TCM_OBD, NM_APPL_AR, NM_ASX_AR, NM_CPC_AR, NM_DRVU_AR, NM_ECM_AR, NM_FSCM_AR, NM_ISM_AR, NM_TCM_AR, DIAG_RQ_ASX, DIAG_RQ_AWD, DIAG_RQ_FFAP, DIAG_RQ_FSCM, DIAG_RQ_GLOBAL_UDS, DIAG_RQ_ISM, DIAG_RQ_TCM, DIAG_RS_ASX, DIAG_RS_AWD, DIAG_RS_FFAP, DIAG_RS_FSCM, DIAG_RS_ISM, DIAG_RS_TCM, DIAGX_RQ_FSCM_OBD, DIAGX_RQ_GLOBAL_OBD, DIAGX_RQ_TCM_OBD, DIAGX_RS_FSCM_OBD, DIAGX_RS_TCM_OBD, APPL_ECU_ASX_1_5v54k457m0s1vt3vxsj5u865a, APPL_ECU_ASX_1A, APPL_ECU_ASX_1B, APPL_ECU_ASX_1C, APPL_ECU_ASX_1D, APPL_ECU_ASX_1E, APPL_ECU_ASX_1F, APPL_ECU_ASX_1G, APPL_ECU_ASX_1H, APPL_ECU_ISM1_886jtkw1iycgtnn3hwl0wnyvu, APPL_ECU_ISM_1A, APPL_ECU_ISM_1B, APPL_ECU_ISM_1C, APPL_ECU_ISM_1D, APPL_ECU_ISM_1E, APPL_ECU_ISM_1F, APPL_ECU_ISM_1G, APPL_ECU_ISM_1H, APPL_ECU_ISM2_414durxpb4zkiz07ge51mu0wf, APPL_ECU_ISM_2A, APPL_ECU_ISM_2B, APPL_ECU_ISM_2C, APPL_ECU_ISM_2D, APPL_ECU_ISM_2E, APPL_ECU_ISM_2F, APPL_ECU_ISM_2G, APPL_ECU_ISM_2H, APPL_ECU_SSP_1_bhdkr7ytnkqdldfnan7bi0hzl, APPL_ECU_SSP_1A, APPL_ECU_SSP_1B, APPL_ECU_SSP_1C, APPL_ECU_SSP_1D, APPL_ECU_SSP_1E, APPL_ECU_SSP_1F, APPL_ECU_SSP_1G, APPL_ECU_SSP_1H, ASX_Stat, DPC_Md_ASX_Rs_CPC, AWD_Clutch_Stat, AWD_Err_Stat_V2, AWD_OprtnMd, AWD_TCASE_Stat1_Pr2_3ufw8rot8ihm8nnppmgv2dnz0, CRC_AWD_TCASE_Stat1_Pr2, ESP_Md_Rq_AWD, Gr_TCASE_V2, LkTrq_Estim_AWD_V2, RearGrTemp_Estim_AWD, Rsrv1_AWD_TCASE_Stat1_Pr2, SQC_AWD_TCASE_Stat1_Pr2, Brk_Stat, BrkIntrvntn_Actv_AS, BrkIntrvntn_Actv_CWA, BrkIntrvntn_Actv_EPKB, BrkIntrvntn_Actv_ESP, BrkPdl_Stat, BrkRq_PT_Enbl, BrkSys_Stat_Pr2_7r9ilu941lyckw1hfocaygals, BrkTrq_D_V2, BrkTrq_V2, CRC_BrkSys_Stat_Pr2, DSR_Actv, DSR_Sys_Flt, EmgBrk_Actv, ESP_Oprtn_Stat_AS_V2, ESP_Sys_Stat_V2, FTW_PressDrop_Stat, FullBrk_Actv, Rsrv5_BrkSys_Stat_Pr2, SQC_BrkSys_Stat_Pr2, SSA_EmgBrk_Actv, ABC_PmpTrq, ActvDnShift_Rq_AS, ADC_SwLED_Rq_V2, AirTemp_Outsd, DynFLDS_Supp_Rq_AS, Eng_Rq_ABC_Pr2_6os4g52vhw32mgg7rkesn49tl, EngRPM_Rq_ABC, EngTrqMin_Rq_RBS, GrMax_Rq_ESP_V2, GrMin_Rq_ESP_V2, GrMinMax_Rq_DTR, PlugInHyb_OprtnMd_V2, PT_Rq_ESP_Pr2_7zyc9ptgtwt6c0u4cmgedic39, PwrFreeD_Supp_Rq_AS, ShftChrDsp_Rq_AS, SSA_ECO_Sw_LED_On_Rq, Term54_Actv, VehDrvProg_M_Rq_PT, VehDrvProg_M_Rq_PT_Avl, VehDrvProgSw_Psd, CRC_ParkCfg_Stat_Pr2, DPC_GlobalMd_Rq, DPC_Master_Rq_Pr2_6xpghgrxfn5z4r5iojjh5y496, DPC_Md_PT_Rq, DPC_Md_PwrFreeD_Plus_Rq, DPC_Md_Tx_Rq, ParkCfg_Stat_Pr2_5onkeem8aikyiyd802x686qlp, ParkGuid_Stat, ParkStyle_V2, RemTank_Unlk_Stat, Rsrv1_ParkCfg_Stat_Pr2, Rsrv2_ParkCfg_Stat_Pr2, SQC_ParkCfg_Stat_Pr2, Trlr_Stat, OC_P_Fast_ORC, OC_P_Flt_ORC, OC_P_ORC, OC_P_ORC_Stat_b88mnsk10wi9igll55wkw677g, CHASSIS_POWERTRAIN_R3_AR2/PW_FL_Posn_Stat, PW_FL_Stat_V2_6v70rlaz165e71dnyncul6g95, CHASSIS_POWERTRAIN_R3_AR2/PW_FR_Posn_Stat, PW_FR_Stat_V2_2x3udh0wjaxzx1twouxqkpy52, CHASSIS_POWERTRAIN_R3_AR2/PW_RL_Posn_Stat, PW_RL_Stat_V2_dgy4a11dbcs3i53xerhwo9yp0, CHASSIS_POWERTRAIN_R3_AR2/PW_RR_Posn_Stat, PW_RR_Stat_V2_adyzba63i840bap88qsx59309, TSSR_Ft_Stat, TSSR_Stat_3s1wz4y3oqhndwn553g3cyqdy, VehDrvProg_M_Rq_HU, AWD_TCASE_Rq_ESP_Pr2_6zte6z0zjmd0zcj41mtuz08ph, CT_Stat, ESP_Disp_Rq_Pr2_39wzgvb26pwujef2adbohryly, ESP_FricCoeff_Stat, ESP_Md_Rq_Ack, LDC_Disp_Rq_ESP_8w7vdtj2cn0be26e2qunelq4k, LDC_Disp_Rq_RDU_V2_37596z9a6jee3gfi1bkb9wjtb, LDC_Spd_Dsr, LDC_Spd_Dsr_RDU, Act_DynFct_Rq_DS, CoastMd_Rq_CPC, CPC_PredStrat_Data_AR2_gtq6klj4fn801tl507uvamgb, Funct_GrShft_Rq_DS, GrShft_Rq_DS, PhsGrShiftStrt_CPC, Pred_EngCoolTemp, Pred_Radar_DS_Stat, Pred_Slope_DS, Pred_VehAccel_Y_DS, RadarBsd_GrShft_Rq_DS, TrafficFlow_Info_DS, DAC_ECM_Data1, DAC_ECM_Data2, DAC_ECM_Data3, DAC_ECM_Data4, DAC_ECM_Data5, DAC_ECM_Data6, DAC_ECM_Data7, DAC_ECM_Data8, DAC_ECM_Data_2al2wd1ekctisq83jz37brera, DAC_ISM_Data1, DAC_ISM_Data2, DAC_ISM_Data3, DAC_ISM_Data4, DAC_ISM_Data5, DAC_ISM_Data6, DAC_ISM_Data7, DAC_ISM_Data8, DAC_ISM_Data_a00gd8sscucoi8oddzqtfrwxy, DAC_TCM_Data1, DAC_TCM_Data2, DAC_TCM_Data3, DAC_TCM_Data4, DAC_TCM_Data5, DAC_TCM_Data6, DAC_TCM_Data7, DAC_TCM_Data8, DAC_TCM_Data_2bwrxx3jxcrr8ui2py52ml14h, CRC_SHW_Rq2_Pr2, DPC_Md_PT_Rs, DPC_Md_PwrFreeD_Plus_Rs_CPC, DPC_Md_Tx_Rs_CPC, Key_P_Enbl_CPC, PARK_DrvDir_Stat_CPC, Rsrv0_SHW_Rq2_Pr2, ShW_DrvPosn_PRND_Lever_CPC, SHW_Emg_P_Path_Rq, SHW_MnTrctAxl_D_Allowed, SHW_MnTrctAxl_DrvPosn_Imm_Rq, SHW_MnTrctAxl_DrvPosn_N_Actv_Rq, SHW_MnTrctAxl_DrvPosn_Target_Rq, SHW_MnTrctAxl_N_Allowed, SHW_MnTrctAxl_P_Allowed, SHW_MnTrctAxl_R_Allowed, ShW_MnTrctAxl_ShiftLk_Stat, SHW_Rq2_Pr2_25eo2jxdt9eomhrgzz8hck6us, SPCR_Dsabl_Rq_CPC, SQC_SHW_Rq2_Pr2, TxDrvProgMan_Actv_CPC, TxLHOM_Stat_Rq_CPC, AMG_MenuSw_Psd, AMG_StartSw_Psd, DiffLk_M_LkTrq_Rq_AMG, DiffLk_Trq_Rq_AMG, DRVU_LastMd_Disp_Rq_AMG, EDIFF_MsgDisp_Rq_AMG, EngMountCtrl_Hard, EngMountCtrl_Stat, ESP_Md_Rq_AMG, ExhstFlap_Stg_Rq_AMG, ExhstFlap_SwLED_Rq_AMG, IC_SpdLimit_MsgDisp_Rq, SpdLimit_MsgDisp_TrgRq_AMG, Spoil_R_MsgDisp_Rq_AMG, Spoil_R_Posn_AMG, Susp_StatMsg_Disp_Rq_AMG, DwnShft_Corr_G2_G1, DwnShft_Corr_G3_G2, DwnShft_Corr_G4_G3, DwnShft_Corr_G5_G4, DwnShft_Corr_G6_G5, DwnShft_Corr_G7_G6, DwnShft_Corr_G8_G7, DwnShft_Corr_G9_G8, DwnShft_Corr_Tx_Trgr, ECM_DAC_Data1, ECM_DAC_Data2, ECM_DAC_Data3, ECM_DAC_Data4, ECM_DAC_Data5, ECM_DAC_Data6, ECM_DAC_Data7, ECM_DAC_Data8, ECM_DAC_Data_evokyfu54wz1o08tpk616zohb, ECU_APPL_ASX_1_3be5jsdyicsypdagrm44msol0, ECU_APPL_ASX_1A, ECU_APPL_ASX_1B, ECU_APPL_ASX_1C, ECU_APPL_ASX_1D, ECU_APPL_ASX_1E, ECU_APPL_ASX_1F, ECU_APPL_ASX_1G, ECU_APPL_ASX_1H, ECU_APPL_ISM1_1g7qtpxtgfi7n74g8lc02q12d, ECU_APPL_ISM_1A, ECU_APPL_ISM_1B, ECU_APPL_ISM_1C, ECU_APPL_ISM_1D, ECU_APPL_ISM_1E, ECU_APPL_ISM_1F, ECU_APPL_ISM_1G, ECU_APPL_ISM_1H, ECU_APPL_ISM2_8va3ehzr91vpl316qv3y6y7a5, ECU_APPL_ISM_2A, ECU_APPL_ISM_2B, ECU_APPL_ISM_2C, ECU_APPL_ISM_2D, ECU_APPL_ISM_2E, ECU_APPL_ISM_2F, ECU_APPL_ISM_2G, ECU_APPL_ISM_2H, ECU_APPL_ISM3_90diuvxlz0lg45a5437kvhgbn, ECU_APPL_ISM_3A, ECU_APPL_ISM_3B, ECU_APPL_ISM_3C, ECU_APPL_ISM_3D, ECU_APPL_ISM_3E, ECU_APPL_ISM_3F, ECU_APPL_ISM_3G, ECU_APPL_ISM_3H, ECU_APPL_SSP_1_cozcqf4g8wtxil74o34x10gji, ECU_APPL_SSP_1A, ECU_APPL_SSP_1B, ECU_APPL_SSP_1C, ECU_APPL_SSP_1D, ECU_APPL_SSP_1E, ECU_APPL_SSP_1F, ECU_APPL_SSP_1G, ECU_APPL_SSP_1H, CRC_EM01_Stat1_Pr2, EM01_DC_Volt, EM01_Emg_Rq, EM01_NegTrq_Rs, EM01_PerfLim_Rq, EM01_RotDir, EM01_RPM, EM01_Stat1_Pr2_4hvri6w0u2vqjawx4ll81022i, EM01_Trq, EM01_VehImmobSyst_Actv_Md, Rsrv1_EM01_Stat1_Pr2, SQC_EM01_Stat1_Pr2, CRC_EM_PtMngmnt_Pr2, ElecBoost_Avl, EM_PtMngmnt_Pr2_3wxzgy1jeqdhai2x3bxoim0oa, HDC_Md_Rq_EM01_V2, HDC_Slip_Rq_TCC, HDC_Trq_Rq_TCC, HDC_TxInRpm_Min_Rq, Recup_Avl, Rsrv1_EM_PtMngmnt_Rq_Pr2, Rsrv2_EM_PtMngmnt_Rq_Pr2, Rsrv3_EM_PtMngmnt_Rq_Pr2, SQC_EM_PtMngmnt_Pr2, TxHybDrvMd_Rq_ECM_V2, TxPkPosn_Rq_PNHV, CRC_Eng_Rs4_Pr2, Eng_Rs4_Pr2_dg8les6g8bd4zh1pem3ucc29t, EngTrq_DynOffset, EngTrqMinDyn_TTC, Rsrv0_Eng_Rs4_Pr2, Rsrv1_Eng_Rs4_Pr2, SQC_Eng_Rs4_Pr2, CRC_Eng_Rs1_PT_Pr2, Eng_Rs1_PT_Pr2_cf9mw3gecnkesr53zjhm61sph, EngRPM_Enbl_Rq_TCM, EngTrq_Ack_ECM, EngTrq_Enbl_Rq_TCM, EngTrqSel_AS_TTC_V2, EngTrqSel_D_TTC_V2, EngTrqSel_ESP_TTC_V2, EngTrqTrgtGr, Rsrv1_Eng_Rs1_PT_Pr2, SQC_Eng_Rs1_PT_Pr2, TrqCoord_Ifc_CPC_TCM, CRC_Eng_Rs2_PT_Pr2, Eng_Rs2_PT_Pr2_a8h33xdavwvlmc583w9zxcagw, EngTrqMaxETC_V2, EngTrqMaxETCStatic, EngTrqMinTTC_V2, EngTrqStatic_PT_V2, Rsrv1_Eng_Rs2_PT_Pr2, Rsrv2_Eng_Rs2_PT_Pr2, Rsrv3_Eng_Rs2_PT_Pr2, SQC_Eng_Rs2_PT_Pr2, AccelPdlPosn, AccelPdlPosn_D_Raw, AccelPdlPosn_Raw, AccelPdlPosnSens_Flt, CRC_Eng_Rs3_Pr2, DrvAwaySpd_Rq_TCM, Eng_Rs3_Pr2_dbt1hpurrces52skcqo6f7f6g, KickDnSw_Psd, Rsrv2_Eng_Rs3_Pr2, SQC_Eng_Rs3_Pr2, StartBrk_Rq_ECM, Tcc_Trq_Adpn_Rq, AddPwrCnsmr_On_Rq, CRC_Eng_Rs_EngCtrl_Pr2, Eng_Rs_EngCtrl_Pr2_1g6e1wh7aspfj509n9mt9fl55, EngRPM, EngRPM_Sens_LHOM, EngRun_Stat, EngStyle, EngTrq, EngTrqLmtd_Misfire, EngTrqMaxCorrFctr, OFC_Stat_PT, Rsrv2_Eng_Rs_EngCtrl_Pr2, SQC_Eng_Rs_EngCtrl_Pr2, Eng_SoftWarmUp_Actv, EngRunTm_PTO_OBD, EngCtrl_Eng_Stat_AR/EngShutOffTm, EngSt_Remain, FuelCoagu_Dtct, FuelPressHold_Rq, FuelTemp_ECM, EngCtrl_Eng_Stat_AR/TC_Start_Reset_Trgr, AirFlowRate, AirPress_Manifold, AirTemp_Outsd_Sens_Flt, ECM_OBD_6qh6mjv6xjqli5tjiuho3zgjz, EngLoad_OBD, FuelPress_OBD, OBD_Clr_Rq, OBD_ColdStartDenCond_Stat, OBD_ColdStartERS_Actv, OBD_DrvCycCond_Stat, OBD_GnrlDenCond_PDTC_Del, OBD_GnrlDenCond_Stat, OBD_IgnCycCond_Stat, OBD_IgnCycCondICE_Stat, OBD_Md04_enbl, OBD_WarmupCond_Actv, AccelPdlPosn_OBD, AccelPdlPosn_Red_OBD, OBD_ColdStartERS_EMTrqRng_Rq, PdlPosn_OBD_c3ryvzr3q34rn6bg9vzbp6trj, FuelPress_Diff, FuelVlv_Opn, CRC_Fuel_Rq_Pr2, EngIdleRPM_Dsr_V2, EngShutOffTm_Flt_ECM, Fuel_Rq_Pr2_eypyqep6qt2njcbx8m8j4hfby, FuelLowPress_Sys_Rq, FuelPress_In, FuelPress_Rq, FuelVolFlow_Rq, ParticleFltrCorrOffset, Rsrv1_Fuel_Rq_Pr2, Rsrv2_Fuel_Rq_Pr2, SQC_Fuel_Rq_Pr2, AirPress_Outsd, CylCutoff_Stat, EngCoolTemp, EngOilQual, FuelCons, IntkAirTemp, PN14_EHC_Prio_Rq, PreHt_Stat, BatCplSw_Rq_EPKB, BrkLgt_On_Rq, CRC_EPKB_Stat_Pr2, DynBrkMd, EPKB_Stat_Pr2_9vocfbztwmx64yya8hopavqwq, EPkBrk_Stat, ESP_Enbl_Rq_EPKB, PkBrk_Stat, PkBrkSw_Stat, Rsrv1_EPKB_Stat_Pr2, Rsrv2_EPKB_Stat_Pr2, Rsrv3_EPKB_Stat_Pr2, Rsrv4_EPKB_Stat_Pr2, SQC_EPKB_Stat_Pr2, TxPkPosn_Rq_EPKB, CRC_EVC_CfgBit_01_32_Pr2, EVC_01_Ver_USA_Avl, EVC_02_Ver_Mexico_Avl, EVC_03_Ver_Japan_Avl, EVC_04_Ver_GulfStates_Avl, EVC_05_Ver_Australia_Avl, EVC_06_Ver_China_Avl, EVC_07_Ver_S_Korea_Avl, EVC_08_Ver_Canada_Avl, EVC_09_FullHyb_Avl, EVC_0A_Hyb_20kW_Avl, EVC_0B_PlugInHyb_80kW_Avl, EVC_0C_AllWheelDr_Avl, EVC_0D_4x2Drive_Avl, EVC_0E_Presf_Avl, EVC_0F_TrlrHtch_Avl, EVC_10_KG_Avl, EVC_11_AutTrunkLid_Avl, EVC_12_AutRearDr_Avl, EVC_13_PwrCls_Avl, EVC_14_RainSens_Avl, EVC_15_DRLt_Avl, EVC_16_FogLmp_Avl, EVC_17_IL_Pk_Avl, EVC_18_AmbLgt_Avl, EVC_19_ElDrPosnSel_Avl, EVC_1A_IntSfProt_Avl, EVC_1B_VTA_Avl, EVC_1C_HghVTP_Avl, EVC_1D_SecurityVer_Avl, EVC_1E_GuardLvl_B4_Avl, EVC_1F_GuardLvl_B6_Avl, EVC_20_GuardLvl_B7_Avl, EVC_21_Pullman_Avl, EVC_22_SpecClos_Avl, EVC_23_PASS_Avl, EVC_24_ICH_Avl, EVC_25_HVAC_R_Avl, EVC_26_SSA_Avl, EVC_27_HandsFreeAcc_Avl, EVC_28_PlugInHyb_50kW_Avl, EVC_29_Hyb_30kW_Avl, EVC_2A_SeatElAdj_F_OprtnR_Avl, EVC_2B_DSI_Sel_Avl, EVC_2C_WC_VEDA_Avl, EVC_2D_AutoSpdCtrl_Avl, EVC_2E_AddEquipBlock_Avl, EVC_2F_AddEquip_Avl, EVC_30_AddEquip_Avl, EVC_31_AddEquip_Avl, EVC_32_AddEquip_Avl, EVC_CfgBit_01_32_Pr2_bczisb61ims7titum6cc8o5oq, EVC_CfgBit_01_32_Stat, SQC_EVC_CfgBit_01_32_Pr2, CRC_EVC_CfgBit_33_64_Pr2, EVC_33_EmgOpn_F_Avl, EVC_34_Curtain_F_Avl, EVC_35_EmgOpn_Inact, EVC_36_SpecVehPW_FL_Avl, EVC_37_SpecVehPW_FR_Avl, EVC_38_SpecVehPW_RL_Avl, EVC_39_SpecVehPW_RR_Avl, EVC_3A_RB_F_Avl, EVC_3B_RB_R_Avl, EVC_3C_SeatDrvDyn_Ft_Avl, EVC_3D_ComfHdRst_Ft_Avl, EVC_3E_SeatMultiCont_Ft_Avl, EVC_3F_SeatHt_Ft_Avl, EVC_40_SeatClim_Ft_Avl, EVC_41_SeatMem_LHD_Avl, EVC_42_SeatMem_RHD_Avl, EVC_43_SeatMemPk_Avl, EVC_44_ReclSeat_Avl, EVC_45_SeatMultiCont_R_Avl, EVC_46_SeatBkRstAdj_R_Avl, EVC_47_SeatHt_R_Avl, EVC_48_SeatClim_R_Avl, EVC_49_WShWashHt_Avl, EVC_4A_TaxiPwrSup_Avl, EVC_4B_TaxiRoofLmpCon_Avl, EVC_4C_TaxiEmgAlm_Avl, EVC_4D_RadioHdFree_Avl, EVC_4E_GAS_Avl, EVC_4F_CtrlU_MultiFunc_Avl, EVC_50_TaxInMirr_Avl, EVC_51_DistRecInMirr_Avl, EVC_52_PreInstRad_Avl, EVC_53_VehHandi_Avl, EVC_54_PanelHt_Ft_Avl, EVC_55_SeatComfHt_Ft_Avl, EVC_56_SeatComfHt_R_Avl, EVC_57_IntFoldHdRst_Ft_Avl, EVC_58_SeatInd_R_Avl, EVC_59_SeatChauffPos_P_Avl, EVC_5A_SeatMContMass_Ft_Avl, EVC_5B_PanelHt_R_Avl, EVC_5C_Airscarf_Ft_Avl, EVC_5D_SeatLimit_P_Avl, EVC_5E_TaxiRoofLmp_Avl, EVC_5F_SeatElAdj_LHD_Avl, EVC_60_SeatElAdj_RHD_Avl, EVC_61_AMGPerfSusp_Avl, EVC_62_ShiftExhstSys_Avl, EVC_63_ActvLDA_MPC_Avl, EVC_64_EAS_Avl, EVC_CfgBit_33_64_Pr2_6j1ey0vfxblk9wf2gvnbh92fe, EVC_CfgBit_33_64_Stat, SQC_EVC_CfgBit_33_64_Pr2, CRC_EVC_CfgBit_65_96_Pr2, EVC_65_CruiseCtrl_Avl, EVC_66_OffRoadPk_Avl, EVC_67_CMS_Avl, EVC_68_CMS_R_Avl, EVC_69_BrkEngg_PP_Avl, EVC_6A_BasExtd_Avl, EVC_6B_MirrFld_Avl, EVC_6C_BSM_Avl, EVC_6D_ActvBSM_Avl, EVC_6E_TurnAss_Avl, EVC_6F_ADTR_Avl, EVC_70_DTR_Pro_Avl, EVC_71_ALS_Avl, EVC_72_ActvLDA_Avl, EVC_73_FCW_Avl, EVC_74_LaneRec_Avl, EVC_75_NV_Avl, EVC_76_RoadSignDtct_Avl, EVC_77_RVC_Avl, EVC_78_SurrView_Avl, EVC_79_PTS_Avl, EVC_7A_APG_Avl, EVC_7B_ActPKAS_Avl, EVC_7C_IHC_Avl, EVC_7D_IHC_Plus_Avl, EVC_7E_BasPlusQ_Avl, EVC_7F_ECO_St_Avl, EVC_80_PSTS_Avl, EVC_81_ABC_Avl, EVC_82_SteelAirSusp_Avl, EVC_83_AirSemiActv_Susp_Avl, EVC_84_SportSusp_Avl, EVC_85_SportPk_AMG_Avl, EVC_86_SportPk_Avl, EVC_87_SportPk_Ext_Avl, EVC_88_DualView_Avl, EVC_89_Entertain_R_Avl, EVC_8A_DigTV_Avl, EVC_8B_DAB_Tun_Avl, EVC_8C_MTUS_Avl, EVC_8D_UCI_Avl, EVC_8E_SndSys_Avl, EVC_8F_WShViewWin_Avl, EVC_90_WSh_Clr_Avl, EVC_91_WSh_Ht_Avl, EVC_92_WShBL_Prot_Avl, EVC_93_WSh_Ht_Lcut_Avl, EVC_94_OptPack_Clas_Avl, EVC_95_OptPack_Avan_Avl, EVC_96_OptPack_Eleg_Avl, EVC_CfgBit_65_96_Pr2_av2hye5lktbglj5y8o60nsl17, EVC_CfgBit_65_96_Stat, SQC_EVC_CfgBit_65_96_Pr2, CRC_EVC_CfgList_01_0C_Pr2, EVC_CfgList_01_0C_Pr2_3qvfhaj56jpqdd0izhj6fs0z3, EVC_CfgList_01_0C_Stat, EVC_List01_StStyle, EVC_List02_BodyStyle, EVC_List03_RoofStyle, EVC_List04_HL_Style, EVC_List05_TxStyle, EVC_List06_VehLineYear, EVC_List07_HVAC_Style, EVC_List08_Country, EVC_List09_HU_Style, EVC_List0A_TPM_Style, EVC_List0B_AddEquip, EVC_List0C_VehLine, SQC_EVC_CfgList_01_0C_Pr2, Platform_Stat_Star2, FFAP_AccelPdlPosn_Rq, FFAP_ActvMd_Rq, FFAP_AmpliFctr_Rq, FFAP_DbPls_IntrmLgth_Rq, FFAP_DbPls_Rq_e3ruoxgpxxjtw75hktbk3o88g, FFAP_DbPlsI_Force_Max_Rq, FFAP_DbPlsTrgr_Rq, FFAP_Force_Max_Rq, FFAP_Freq_Rq, FFAP_SigFormat_Rq, FFAP_SignalAttr_Rq_apxko4gwe2i7ye3haduu5o5qj, FFAP_ActPosn_Corr, FFAP_CurCtrl_Stat, FFAP_CurrCons, FFAP_DbPls_Actv, FFAP_EcuTemp, FFAP_Rdy, FFAP_SurfTemp, FSCM_CALID_CVN_ErrNum, FSCM_CALID_Data, FSCM_CVN_Tx_Actv, FSCM_DTC1_Idx, FSCM_DTC1_Stat, ElectricFuelPmp_Curr, ElectricFuelPmp_RPM, ElectricFuelPmp_Stat, EthanolConcent, FuelPmpDtyCyc, FuelPress, FSCM_FuelRefillEvent_Dtct, FSCM_TankLvl_Min_50, Fuel_Lvl_Critic, FuelTemp, MIL_On_Rq_FSCM, TankLvl, TankLvl_Disp_V2, TankLvl_Max, TankLvl_Min, TankRes, AddWtrPmp_Actv, AddWtrPmp_Err, CRC_HVAC_CompTrq_Pr2, EngFanRPM_Rq_HVAC, FrntGrllBlnd_Opn_Rq, HtPwr_Ft_Rq, HVAC_Comp_Ft_On, HVAC_CompTrq_Ft, HVAC_CompTrq_Pr2_c82iy4u15nkwuh8st1cqydegx, HVAC_CoolCirc_Actv, HVAC_CoolFan_Rq, HVAC_CoolVlv_Rq, HVAC_EngIdleRPM_Inc_Rq, HVAC_FrntGrllBlnd_Low_Rq, HVAC_FrntGrllBlnd_Up_Rq, HVAC_MaxCool_Rq, HVAC_Ref_Circ_NA, HVAC_TxShftPoint_Inc_Rq, HVAC_TxShftPointHt_Inc_Rq, Rsrv1_HVAC_Comp_Trq_Pr2, SQC_HVAC_CompTrq_Pr2, SSA_Enbl_Rq_HVAC, EM01_OilCool_Rotor_Rq, EM01_OilCool_Stator_Rq, EM01_RotorObsrv_Temp, AirTemp_Outsd_Disp, IC_TP_Alive, Odo, UnitVehSpd, VehSpd_Disp, BusFlt_PrmntActv, ContEngRun_Stat, CRC_Ign_Stat_Pr2, DidA_ExtTest_Pres, EngSt_Enbl_Rq_KG, ESL_Lk_Rq, Ign_On_StartProc_Inact, Ign_Stat_Pr2_457i75qk4uen9ahb37ecxdhxz, ISw_Stat, KG_IgnCtrl_Actv, KG_StartSw_Psd, Mobile_Chrg_Rq_EIS, RemSt_IgnCtrl_Actv, RemSt_IgnCtrl_Info, RevGr_Engg, SPCR_AcustWarn_Rq_EIS, SPCR_Conf_EIS, SPCR_Flt_EIS, SQC_Ign_Stat_Pr2, TxPkPosn_Emg_Rq, TxPkPosn_Rq, TxPkPosn_Rq_SPCR_Enbl, TxPkPosnAuto_Enbl, ISM_DAC_Data1, ISM_DAC_Data2, ISM_DAC_Data3, ISM_DAC_Data4, ISM_DAC_Data5, ISM_DAC_Data6, ISM_DAC_Data7, ISM_DAC_Data8, ISM_DAC_Data_7p6mfdvzdjn83yje572o4gwnl, CRC_SBW_Rq_DRVU_Pr2, Rsrv1_SBW_Rq_DRVU_Pr2, Rsrv2_SBW_Rq_DRVU_Pr2, SBW_Rq_DRVU_Pr2_71okqqkd28hyyebm190lxt3vd, SQC_SBW_Rq_DRVU_Pr2, StW_Sw_Stat3_DRVU, TSL_P_Psd_StW_DRVU, TSL_RND_Posn_StW_DRVU, TxmtId_SBW_Rq_DRVU, CRC_LDC_Rq_SCCM_Pr2, CRC_SBW_Rq_SCCM_Pr2, DTR_Dist_Rq, LDC_Rq_SCCM_Pr2_1urxjv3xbtzkrxlqmdhowxf5n, Rsrv1_LDC_Rq_SCCM_Pr2, Rsrv1_SBW_Rq_SCCM_Pr2, Rsrv2_LDC_Rq_SCCM_Pr2, Rsrv2_SBW_Rq_SCCM_Pr2, SBW_Rq_SCCM_Pr2_1bw4xg1pomod9nov43ee8m7kx, SpdCtrlLvr_Stat_V3, SQC_LDC_Rq_SCCM_Pr2, SQC_SBW_Rq_SCCM_Pr2, StWhl_Sw_Stat3, TSL_P_Psd_StW, TSL_RND_Posn_StW, TxmtId_SBW_Rq_SCCM, VSL_Enbl_Rq, Meas_SSP_1A, Meas_SSP_1B, Meas_SSP_1C, Meas_SSP_1D, Meas_SSP_1E, Meas_SSP_1F, Meas_SSP_1G, Meas_SSP_1H, Meas_SSP_379btqek1l385mbjtnm74j6ok, Mess_TCM_HS1_AR_5jqztx9cjivblmvl1y06ch5be, MESS_TCM_HS1_B1_AR, MESS_TCM_HS1_B2_AR, MESS_TCM_HS1_B3_AR, MESS_TCM_HS1_B4_AR, MESS_TCM_HS1_B5_AR, MESS_TCM_HS1_B6_AR, MESS_TCM_HS1_B7_AR, MESS_TCM_HS1_B8_AR, Mess_TCM_HS2_AR_dcm84cc8pxh7e5mqxg338wu8c, MESS_TCM_HS2_B1_AR, MESS_TCM_HS2_B2_AR, MESS_TCM_HS2_B3_AR, MESS_TCM_HS2_B4_AR, MESS_TCM_HS2_B5_AR, MESS_TCM_HS2_B6_AR, MESS_TCM_HS2_B7_AR, MESS_TCM_HS2_B8_AR, Mess_TCM_HS3_AR_4inwpjw806k3gbdnjph7rqf10, MESS_TCM_HS3_B1_AR, MESS_TCM_HS3_B2_AR, MESS_TCM_HS3_B3_AR, MESS_TCM_HS3_B4_AR, MESS_TCM_HS3_B5_AR, MESS_TCM_HS3_B6_AR, MESS_TCM_HS3_B7_AR, MESS_TCM_HS3_B8_AR, Mess_TCM_HS4_AR_evfdhru5bsxezwntb7pz0kz0s, MESS_TCM_HS4_B1_AR, MESS_TCM_HS4_B2_AR, MESS_TCM_HS4_B3_AR, MESS_TCM_HS4_B4_AR, MESS_TCM_HS4_B5_AR, MESS_TCM_HS4_B6_AR, MESS_TCM_HS4_B7_AR, MESS_TCM_HS4_B8_AR, Mess_TCM_HS5_AR_3ytjcfdv9pweydld67zsc9n63, MESS_TCM_HS5_B1_AR, MESS_TCM_HS5_B2_AR, MESS_TCM_HS5_B3_AR, MESS_TCM_HS5_B4_AR, MESS_TCM_HS5_B5_AR, MESS_TCM_HS5_B6_AR, MESS_TCM_HS5_B7_AR, MESS_TCM_HS5_B8_AR, Mess_TCM_HS6_AR_3s9ru3zfu2enkfu9f6dni9y9y, MESS_TCM_HS6_B1_AR, MESS_TCM_HS6_B2_AR, MESS_TCM_HS6_B3_AR, MESS_TCM_HS6_B4_AR, MESS_TCM_HS6_B5_AR, MESS_TCM_HS6_B6_AR, MESS_TCM_HS6_B7_AR, MESS_TCM_HS6_B8_AR, Mess_TCM_HS7_AR_3mznt49qdhynqladaleqa672k, MESS_TCM_HS7_B1_AR, MESS_TCM_HS7_B2_AR, MESS_TCM_HS7_B3_AR, MESS_TCM_HS7_B4_AR, MESS_TCM_HS7_B5_AR, MESS_TCM_HS7_B6_AR, MESS_TCM_HS7_B7_AR, MESS_TCM_HS7_B8_AR, Mess_TCM_HS8_AR_c04hs7230v0uvdfftuf8jh4ro, MESS_TCM_HS8_B1_AR, MESS_TCM_HS8_B2_AR, MESS_TCM_HS8_B3_AR, MESS_TCM_HS8_B4_AR, MESS_TCM_HS8_B5_AR, MESS_TCM_HS8_B6_AR, MESS_TCM_HS8_B7_AR, MESS_TCM_HS8_B8_AR, Mess_TCM_HSA_AR_4isll7yxbbz5hw57ubwbk9twa, MESS_TCM_HSA_B1_AR, MESS_TCM_HSA_B2_AR, MESS_TCM_HSA_B3_AR, MESS_TCM_HSA_B4_AR, MESS_TCM_HSA_B5_AR, MESS_TCM_HSA_B6_AR, MESS_TCM_HSA_B7_AR, MESS_TCM_HSA_B8_AR, Mess_TCM_HSB_AR_2k40btgzi6zdukcyrsofq65p8, MESS_TCM_HSB_B1_AR, MESS_TCM_HSB_B2_AR, MESS_TCM_HSB_B3_AR, MESS_TCM_HSB_B4_AR, MESS_TCM_HSB_B5_AR, MESS_TCM_HSB_B6_AR, MESS_TCM_HSB_B7_AR, MESS_TCM_HSB_B8_AR, Mess_TCM_HSC_AR_ab1rnn2g0gzay8mfvuwu5tgn0, MESS_TCM_HSC_B1_AR, MESS_TCM_HSC_B2_AR, MESS_TCM_HSC_B3_AR, MESS_TCM_HSC_B4_AR, MESS_TCM_HSC_B5_AR, MESS_TCM_HSC_B6_AR, MESS_TCM_HSC_B7_AR, MESS_TCM_HSC_B8_AR, Mess_TCM_HSD_AR_7f2pb1wttr06fpeiwh38rx42y, MESS_TCM_HSD_B1_AR, MESS_TCM_HSD_B2_AR, MESS_TCM_HSD_B3_AR, MESS_TCM_HSD_B4_AR, MESS_TCM_HSD_B5_AR, MESS_TCM_HSD_B6_AR, MESS_TCM_HSD_B7_AR, MESS_TCM_HSD_B8_AR, Mess_TCM_HSE_AR_2gcwj04mj6g9zu6m75pbzii7q, MESS_TCM_HSE_B1_AR, MESS_TCM_HSE_B2_AR, MESS_TCM_HSE_B3_AR, MESS_TCM_HSE_B4_AR, MESS_TCM_HSE_B5_AR, MESS_TCM_HSE_B6_AR, MESS_TCM_HSE_B7_AR, MESS_TCM_HSE_B8_AR, Mess_TCM_HSF_AR_5wh6a86cve3tu93yo0uv2x00u, MESS_TCM_HSF_B1_AR, MESS_TCM_HSF_B2_AR, MESS_TCM_HSF_B3_AR, MESS_TCM_HSF_B4_AR, MESS_TCM_HSF_B5_AR, MESS_TCM_HSF_B6_AR, MESS_TCM_HSF_B7_AR, MESS_TCM_HSF_B8_AR, Mess_TCM_HSG_AR_3y1jssa1j0apm73uro4je8765, MESS_TCM_HSG_B1_AR, MESS_TCM_HSG_B2_AR, MESS_TCM_HSG_B3_AR, MESS_TCM_HSG_B4_AR, MESS_TCM_HSG_B5_AR, MESS_TCM_HSG_B6_AR, MESS_TCM_HSG_B7_AR, MESS_TCM_HSG_B8_AR, Mess_TCM_HSH_AR_ayr108r4lfg8j9ixm2fzf87eh, MESS_TCM_HSH_B1_AR, MESS_TCM_HSH_B2_AR, MESS_TCM_HSH_B3_AR, MESS_TCM_HSH_B4_AR, MESS_TCM_HSH_B5_AR, MESS_TCM_HSH_B6_AR, MESS_TCM_HSH_B7_AR, MESS_TCM_HSH_B8_AR, NM_APPL_AR/Awake_Diag_Actv, NM_APPL_AR/NM_ActvWakeup, NM_APPL_AR/NM_Coord_Id, NM_APPL_AR/NM_Coord_SleepRdy, NM_APPL_AR/NM_PartNw_Info, NM_APPL_AR/NM_RepeatMsg_Rq, NM_APPL_AR/NM_SrcNode_Id, NM_ASX_AR/Awake_Diag_Actv, NM_ASX_AR/Awake_Ignition_On, NM_ASX_AR/Awake_NwSt, NM_ASX_AR/NM_ActvWakeup, NM_ASX_AR/NM_Coord_Id, NM_ASX_AR/NM_Coord_SleepRdy, NM_ASX_AR/NM_PartNw_Info, NM_ASX_AR/NM_RepeatMsg_Rq, NM_ASX_AR/NM_SrcNode_Id, WakeupRsn_ASX, NM_CPC_AR/Awake_Afterrun_Actv, NM_CPC_AR/Awake_Diag_Actv, Awake_EGRActrAdpn_Actv, NM_CPC_AR/Awake_EngFan_Actv, NM_CPC_AR/Awake_Ignition_On, NM_CPC_AR/Awake_NwSt, Awake_XCP_Actv, NM_CPC_AR/NM_ActvWakeup, NM_CPC_AR/NM_Coord_Id, NM_CPC_AR/NM_Coord_SleepRdy, NM_CPC_AR/NM_PartNw_Info, NM_CPC_AR/NM_RepeatMsg_Rq, NM_CPC_AR/NM_SrcNode_Id, WakeupRsn_CPC, NM_DRVU_AR/Awake_Diag_Actv, Awake_EF_Actv, NM_DRVU_AR/Awake_Ignition_On, NM_DRVU_AR/Awake_NwSt, Awake_StartSw_Psd, Awake_SwIllLvl, Awake_Voice_Call_Actv, NM_DRVU_AR/NM_ActvWakeup, NM_DRVU_AR/NM_Coord_Id, NM_DRVU_AR/NM_Coord_SleepRdy, NM_DRVU_AR/NM_PartNw_Info, NM_DRVU_AR/NM_RepeatMsg_Rq, NM_DRVU_AR/NM_SrcNode_Id, WakeupRsn_DRVU, NM_ECM_AR/Awake_Afterrun_Actv, Awake_CCP_Actv, NM_ECM_AR/Awake_Diag_Actv, Awake_ECP3_Afterrun, Awake_ECP4_Afterrun, NM_ECM_AR/Awake_EngFan_Actv, Awake_EngRestart, NM_ECM_AR/Awake_Ignition_On, NM_ECM_AR/Awake_NwSt, Awake_SensDiag_Actv, Awake_TankPressDiag_Actv, NM_ECM_AR/NM_ActvWakeup, NM_ECM_AR/NM_Coord_Id, NM_ECM_AR/NM_Coord_SleepRdy, NM_ECM_AR/NM_PartNw_Info, NM_ECM_AR/NM_RepeatMsg_Rq, NM_ECM_AR/NM_SrcNode_Id, WakeupRsn_ECM, NM_FSCM_AR/Awake_Afterrun_Actv, NM_FSCM_AR/Awake_Diag_Actv, NM_FSCM_AR/Awake_Ignition_On, NM_FSCM_AR/Awake_NwSt, Awake_Term15_Actv, NM_FSCM_AR/NM_ActvWakeup, NM_FSCM_AR/NM_Coord_Id, NM_FSCM_AR/NM_Coord_SleepRdy, NM_FSCM_AR/NM_PartNw_Info, NM_FSCM_AR/NM_RepeatMsg_Rq, NM_FSCM_AR/NM_SrcNode_Id, WakeupRsn_FSCM, NM_ISM_AR/Awake_Diag_Actv, NM_ISM_AR/Awake_Ignition_On, NM_ISM_AR/Awake_NwSt, Awake_TxShift_Actv, NM_ISM_AR/NM_ActvWakeup, NM_ISM_AR/NM_Coord_Id, NM_ISM_AR/NM_Coord_SleepRdy, NM_ISM_AR/NM_PartNw_Info, NM_ISM_AR/NM_RepeatMsg_Rq, NM_ISM_AR/NM_SrcNode_Id, WakeupRsn_ISM, NM_TCM_AR/Awake_Afterrun_Actv, NM_TCM_AR/Awake_Diag_Actv, NM_TCM_AR/Awake_Ignition_On, NM_TCM_AR/Awake_NwSt, Awake_Parklock_Actv, NM_TCM_AR/NM_ActvWakeup, NM_TCM_AR/NM_Coord_Id, NM_TCM_AR/NM_Coord_SleepRdy, NM_TCM_AR/NM_PartNw_Info, NM_TCM_AR/NM_RepeatMsg_Rq, NM_TCM_AR/NM_SrcNode_Id, WakeupRsn_TCM, CRC_PARK_Drv_Rq_ESP_Pr2, PARK_Drv_Rq_ESP_Pr2_156rahkn2e7mmvc2542gbao5u, PARK_DrvDir_Rq_ESP, PARK_DrvDir_Stat_ESP, PARK_ShiftLk_Rq_ESP, PT_AS_Actv, Rsrv1_PARK_Drv_Rq_ESP_Pr2, Rsrv2_PARK_Drv_Rq_ESP_Pr2, Rsrv3_PARK_Drv_Rq_ESP_Pr2, Rsrv4_PARK_Drv_Rq_ESP_Pr2, SQC_PARK_Drv_Rq_ESP_Pr2, CRC_PARK_Drv_Rs_TCM_Pr2, PARK_Drv_Rs_TCM_Pr2_oe4nkdc61vmdsai3dvff2tvs, PARK_DrvDir_Stat_TCM, Rsrv1_PARK_Drv_Rs_TCM_Pr2, Rsrv2_PARK_Drv_Rs_TCM_Pr2, SQC_PARK_Drv_Rs_TCM_Pr2, TCM_Dir_Stat, IBS_Bat_Curr_Max, PN14_CycleIndex, PN14_ExtBoost_Avl, PN14_Hibern_Md_Flt, PN14_Hibern_Md_Stat, PN14_Hibern_StdbyTm, PN14_RemSt_Bat_Stat, PN14_SolVent_Enbl, PN14_SolVent_Pwr_Max, PN14_SolVent_Updt_Rq, PN14_TDP_PreWarn_Tm, PN14_TDP_Stat_7ug3myfadyinv3s4lvtfvpcqb, PN14_TDP_Sw_Stat, DPM_ExtMd_Enbl_Rq, DPM_MdLmt_Rq, LHC_ComfSys_Rq, LHC_CoolBox_R_Rq, LHC_EBL_Rq, LHC_EngFan_50_Rq, LHC_ICH_Rq, LHC_IntFan_F_50_Rq, LHC_IntFan_R_0_Rq, LHC_IntFan_R_50_Rq, LHC_MirrHt_Rq, LHC_PkLmp_Rq, LHC_PosnLmp_Rq, LHC_PT_Stg1_Rq, LHC_PT_Stg2_Rq, LHC_PTC1_Rq, LHC_PTC2_Rq, LHC_PTC3_Rq, LHC_PTC4_Rq, LHC_PTC5_Rq, LHC_PTC6_Rq, LHC_RHU_Rq, LHC_SeatHtStg1_Rq, LHC_SeatHtStg2_Rq, LHC_SeatHtStg3_Rq, LHC_SeatVn_Rq, LHC_StW_Ht_Rq, LHC_Taxi_Rq, LHC_Tlm_Rq, LHC_TrkSock_Rq, LHC_TrlrSock_Rq, LHC_WprPkHt_Rq, LHC_WShHt_50_Rq, LHC_WShHt_Rq, PN14_eHeV_Enbl, PN14_LHC_Actv, PN14_SupBat_Curr, PN14_SupBat_Stat_aleu8fy7bsux9kh42xfztkzmi, PN14_SupBat_Volt, PN14_SupBatCutSw_Stat, PN14_TransMd_Stat, PN14_TransMd_Updt_Rq, SSA_EngRestart_Actv, EMM_PNHV_Bat_SOC_LoRsltn, EngOilTemp, HtPwr_Stat, CRC_PtMngmnt_Rq_Pr2, ECM_Creep_Abort_Stat, ESP_Intrvntn_Stat_ECM, ExhstFlap_Stg_AMG, GrMax_Rq_ECM_V2, GrMin_Rq_ECM_V2, PtMngmnt_Rq_Pr2_czcqfhcxlfzoeyleoslpc91wg, PwrFreeD_Rq_ECM, Recup_Dsabl_Rq_PT, Rsrv1_PtMngmnt_Rq_Pr2, Rsrv2_PtMngmnt_Rq_Pr2, SQC_PtMngmnt_Rq_Pr2, SSA_EngSp, SSA_Sp_Warn, TCC_Opn_RemainTm_HDC, TCM_DHill_ShftChrDsp_Rq, TxPkPosn_Rq_ECM, WDC_Intrvntn_ECM, CRC_PtMngmnt_Stat2_Pr2, EM2_BoostTrqMax_TCM, HDC_EM01_Err, HDC_GrdntMd_Rq_WDC, HDC_NoShiftDwn_Rq, Hyb_ActvCmbstEng_Start, Hyb_GrChg_Rq, HybDrv_Md, HybStartMd_ECM, HybSys_Actv, PtMngmnt_Stat2_Pr2_52pi4z2we5iyfdnzwhqxb6f78, PushStrtCtl_Rq_CPC, Rsrv1_PtMngmnt_Stat2_Pr2, SQC_PtMngmnt_Stat2_Pr2, SSA_Start_Warn, TrqSetIgnInjShutOff_TCM_Rq, WDC_OutTrq_Rq_ECM_V3, Clutch_Disengg, CoastMd_Disp_Rq, CRC_PT_Stat_Pr2, DL_AllDr_Stat_CPC, DPC_GlobalMd_TrgRq_CPC, DPC_Md_ASX_Rq_CPC, DPC_Md_eDrv_Rs, DPC_Md_ExhstFlap_Rs, DPC_Md_SSA_Rs, EngRun_Edrive_Stat, EngTrq_Ctrl_PT_Actv, EngTrqInc_Enbl_TCM, EngTrqIncChk_Avl, GrN_Engg_MTX, HVAC_CompOff_Rq, HVAC_CompTrq_Max, LowFuelQual_Dtct, PT_Rdy_V2, PT_Stat_Pr2_3par937a8yr160hqtiylu66k8, RevGr_Engg_MTX_ECM, SQC_PT_Stat_Pr2, SSA_Standby_Stat, SSP_Pwr_Rq, TargetRPM_TCM_Ack_Lmtd, PtMngmnt_Stat_AR2/TC_Start_Reset_Trgr, VehFixMaxSpd_V2, PW_FL_Norm, PW_XX_Stat_AR2/PW_FL_Posn_Stat, PW_FL_Posn_V2, PW_FL_Stat_V2_6cv3doeps2jg8qalnshxlbd6j, PW_FR_Norm, PW_XX_Stat_AR2/PW_FR_Posn_Stat, PW_FR_Posn_V2, PW_FR_Stat_V2_br9vsxm9a7yjl7yworl3ulwat, PW_RL_Norm, PW_XX_Stat_AR2/PW_RL_Posn_Stat, PW_RL_Posn_V2, PW_RL_Stat_V2_19hnhwdw4d7qgho1t244h23m6, PW_RR_Norm, PW_XX_Stat_AR2/PW_RR_Posn_Stat, PW_RR_Posn_V2, PW_RR_Stat_V2_300ewz00spt7h0y32xvjjityz, ROE_ASX_bh0k1l31zxyeftblxvt1o8neg, ROE_DTC_ASX, ROE_DTC_Stat_ASX, ROE_Header_ASX, ROE_AWD_812ji4i2uikzhm20lz4b8lx9g, ROE_DTC_AWD, ROE_DTC_Stat_AWD, ROE_Header_AWD, ROE_DTC_FFAP, ROE_DTC_Stat_FFAP, ROE_FFAP_8qrxhmgz4wjb2b2xcd9pf7ii7, ROE_Header_FFAP, ROE_DTC_FSCM, ROE_DTC_Stat_FSCM, ROE_FSCM_7tuz31puvlbck2wez2tozkmyn, ROE_Header_FSCM, ROE_DTC_ISM, ROE_DTC_Stat_ISM, ROE_Header_ISM, ROE_ISM_4y9ojv7xq5khnsiewkqkkc4rx, ROE_DTC_Stat_TCM, ROE_DTC_TCM, ROE_Header_TCM, ROE_TCM_7sr2csz1sd5kgujzog3cttxu0, DayCnt, RTC_Stat1_AR2/EngShutOffTm, HVAC_Vprzr_DryVnTmr_Stat, PT_ShutOffTm, CRC_SBW_Drv_Pk_Posn_CPC_Pr2, Rsrv0_SBW_Drv_Pk_Posn_CPC_Pr2, Rsrv1_SBW_Drv_Pk_Posn_CPC_Pr2, SBW_Drv_Pk_Posn_CPC_Pr2_acd3oordbhg0yjkmuwx4u8jib, SBW_Msg_Disp_Rq_CPC, SBW_ShiftLk_Msg_RevGr_CPC, SQC_SBW_Drv_Pk_Posn_CPC_Pr2, TCM_PkPosn_Flt_Stat_CPC, TSL_MtnLk1_Disp_Rq_CPC_V2, TSL_MtnLk2_Disp_Rq_CPC_V2, TSL_MtnLk3_Disp_Rq_CPC_V2, TxDrvPosn_Disp_Rq_CPC, CRC_ISM_TxDrvPosn_Disp_Rq_Pr2, ISM_TxDrvPosn_Disp_Rq_Pr2_epuwuk6swsjmfffk3fikh4w52, Rsrv3_ISM_TxDrvPosn_Disp_Rq_Pr2, SBW_Msg_Disp_Rq_ISM, SBW_ShiftLk_Msg_RevGr_ISM, SQC_ISM_TxDrvPosn_Disp_Rq_Pr2, TSL_MtnLk1_Disp_Rq_ISM_V2, TSL_MtnLk2_Disp_Rq_ISM_V2, TSL_MtnLk3_Disp_Rq_ISM_V2, TxDrvPosn_Disp_Rq_ISM, CRC_SBW_Drv_Pk_Posn_TCM_Pr2, Gr_Target_Disp_Rq_V2, RaceStartMd_Disp_Rq_AMG, SBW_Drv_Pk_Posn_TCM_Pr2_87jwxqxlzqql6r2vkjah89c7p, SBW_Msg_Disp_Rq_TCM, SBW_ShiftLk_Msg_RevGr_TCM, SQC_SBW_Drv_Pk_Posn_TCM_Pr2, TCM_LHOM_Stat, TCM_PkPosn_Flt_Stat, TCM_Temp_Flt_Stat, TSL_MtnLk1_Disp_Rq_TCM_V2, TSL_MtnLk2_Disp_Rq_TCM_V2, TSL_MtnLk3_Disp_Rq_TCM_V2, TxDrvPosn_Disp_Rq_TCM, TxDrvProg_Disp_Rq_TCM, TxShiftRcmmnd_Disp_Rq_TCM, CRC_SBW_Rs_TCM_Pr2, Rsrv1_SBW_Rs_TCM_Pr2, Rsrv2_SBW_Rs_TCM_Pr2, SBW_Ext_RevGr_Rq, SBW_Rs_TCM_Pr2_dym3b88zatlkmtnb9qcuvfn90, SBW_ShiftLk_RevGr, SQC_SBW_Rs_TCM_Pr2, StartLkSw, TSL_Posn_Rq, TxmtId_SBW_Rs_TCM, TxSelVlvPosn, CRC_SBW_Stat_Pr2, EmgPath_Enbl, EmgPath_Volt, ISM_LHOM, Key_P_Enbl, Rsrv1_SBW_Stat_Pr2, SBW_Stat_Pr2_ecnxwrof0tv45hxypgialh6k2, SHW_MnTrctAxl_D_DrvPosn_Enbl, SHW_MnTrctAxl_DrvPosn_Tgt_Rq_TCM, SHW_MnTrctAxl_Flt1, SHW_MnTrctAxl_Flt2, SHW_MnTrctAxl_Flt3, SHW_MnTrctAxl_Flt4, SHW_MnTrctAxl_Flt5, SHW_MnTrctAxl_Flt6, SHW_MnTrctAxl_Flt7, SHW_MnTrctAxl_Flt8, SHW_MnTrctAxl_N_DrvPosn_Enbl, SHW_MnTrctAxl_P_DrvPosn_Enbl, SHW_MnTrctAxl_R_DrvPosn_Enbl, SPCR_Dsabl_Rq_ISM, SQC_SBW_Stat_Pr2, TSL_Posn_ISM, TSL_Posn_ISM_Init, TSL_Posn_P_ISM, TSL_Posn_Target, TSL_ShiftLk_Stat, TxN_Posn_Rq_D_V2, TxPkPosn_Emg_Actv, CurrDtyCyc_Actl, SSP_Diag_Stat, CRC_StWhl_Angl_Stat_Pr2, Rsrv2_StWhl_Angl_Stat_Pr2, Rsrv3_StWhl_Angl_Stat_Pr2, SQC_StWhl_Angl_Stat_Pr2, StWhl_Angl, StWhl_Angl_Stat_Pr2_c4qb7b59jfa5oc3ih83ubw184, StWhl_AnglSens_Id, StWhl_AnglSens_Stat, StWhl_AnglSensVld_Stat, StWhl_AnglSpd, TCM_DAC_Data1, TCM_DAC_Data2, TCM_DAC_Data3, TCM_DAC_Data4, TCM_DAC_Data5, TCM_DAC_Data6, TCM_DAC_Data7, TCM_DAC_Data8, TCM_DAC_Data_4hn6jksl9jdh5r8zfj9p3zrj0, CRC_TCM_Data2_Pr2, EM_BoostTrq_Rq_TCM, EngWhlTrqRatio_TCM, Gr, Gr_Target, SQC_TCM_Data2_Pr2, SSA_Enbl_Rq_TCM, SSA_Enbl_Stat_TCM, TCM_Data2_Pr2_3aes4m38p3xyalmhl6p5hhgww, TSL_Posn_TCM, TxDrvTrqAbsVal, Clutch_Actv_Stat, Clutch_Stat, CRC_TCM_Data3_Pr2, EM_Trq_RecupGrdnt_Max, TCM_Data3_AR2/EngTrqMax_Rq_TCM, TCM_Data3_AR2/EngTrqMin_Rq_TCM, Gr_Target_TxShiftRcmmnd, PwrFreeD_Actv, Ratio_Chg_Actv, Ratio_Chg_Cont_Actv, SQC_TCM_Data3_Pr2, StartBrk_Rq_TCM, TCC_NoLoad, TCM_Data3_Pr2_4mdu2ave4pajazfn4q4pmyvzw, TCM_EngIdleRPM_Lvl_Rq, TCM_Data3_AR2/Tx_Safe_Cls, TCM_Data3_AR2/TxOutRPM_Plaus, TxOutRPM_V2, TxRatioChgRq_Actv, TxTurbineRPM_V2, ClutchTemp_Model_K0, DPC_Md_TCM_Rs, PhsGrShiftStrt_TCM, SSP_Curr, StrtVarAvl_Stat_TCM, TCM_ECU_Temp, TractUnitOilCool_CoolFlow, TxInertia_EngStrt_Idx, TxOutOilCool_CoolFlow, TxTrqConv_OilOutTemp, Bas_ShftProg_Actv_Idx, CRC_TCM_Data5_Pr2, EM_Drv_DS_TCM_Actv, Rsrv0_TCM_Data5_Pr2, Slope_DS_TCM_Fltrd, SQC_TCM_Data5_Pr2, Stgy_ShftProg_Actv_Idx, TCM_Data5_Pr2_c73komxr1qix41zrytxs0vhwu, TCM_VehImmobSyst_Actv_Md, Trq_Offset_Temp_PT_Ovl, TxDrvProgLim, WarmUp_ShftProg_Actv_Idx, TCM_Disp_Rq_AMG_a2nvzdcsqucauph6dn6priuij, TCM_TxLED_Disp_Rq, TCM_TxShift_Disp_Rq, Tx_OptmzFullLoad_Rq, TxBurnOut_Stat, CRC_TrqConv_Pr2, EngTrqRes_Rq_TCM, FuelBlindOutCtrl_Rq_TCM, Rsrv0_TrqConv_Pr2, SQC_TrqConv_Pr2, TrqConv_Amp_Fact, TrqConv_Pmp_Trq, TrqConv_Pr2_d41hb9de6igapvaa0xr920t3b, BrkRq_TCM, CRC_TCM_EngIntrvntn_Pr2, EngRPM_Ctrl_Rq, EngRPM_Rq_TCM, EngSt_Enbl_Rq_TCM, EngTrq_Rq_TCM_V2, TCM_EngIntrvntn_AR2/EngTrqMax_Rq_TCM, TCM_EngIntrvntn_AR2/EngTrqMin_Rq_TCM, IntrvntnMd_TCM, SQC_TCM_EngIntrvntn_Pr2, SSA_Clutch_Stat, TC_Trq, TccPushStrtCtl_TCM, TCM_EngIntrvntn_Pr2_3yr5mxltfyr8h8xlszlge0nzx, TCM_EngIntrvntn_AR2/Tx_Safe_Cls, TxHybDrvMd_Sync_Actv, TxHybDrvMd_V2, TCM_EngIntrvntn_AR2/TxOutRPM_Plaus, WDC_Boost_Dsabl, AuxOilPmp_Mess_Enbl, CurrDtyCyc_Rq, Adap_K0, Adap_KUEB, AdapTrq_Rq, BasShftProg_Ok, CoastMd_Stat_TCM, CylCutoff_Enbl_TCM, CylCutoff_Shift_Enbl, DPC_Md_PwrFreeD_Plus_Rs, DPC_Md_Tx_Rs, DrvAwElmtAdap_Rq, DrvRst_Hi, MIL_On_Rq_TCM, TCC_Opn_RemainTm_TCM, TCC_Opn_Trgr, Tx_Agility_Stat, TxDrvProgMan_Actv, TxDrvProgManTemp_Actv, TxLHOM2_Gr_Hold, TxLHOM2_Gr_Lock, TxLHOM2_Stat_api97m3bibe3r5flh3ubeb8ji, TxLHOM2_Stat_Clutch, TxLHOM2_Stat_Hybrid, TxLHOM2_Stat_OilPump, TxLHOM2_TX_Hydr, TxLHOM2_TX_PwrFree, TxLHOM2_TX_Tractn, TxMechStyle_V2, TxOffRd_Actv, TxOil_Recirc_Rq, TxOilTemp, TxShiftStyle_V2, TxTemp_Excess, VehDrvProg_TCM_V3, Converter_TempCritic, CRC_TCM_WDC_Data_Pr2, DrvAccelMax_Stat, EngTrqMax_WDC_Rq_TCM, EngTrqMin_WDC_Rq_TCM, EngTrqWDC_Rq_TCM_V2, Rsrv3_TCM_WDC_Data_Pr2, SQC_TCM_WDC_Data_Pr2, TCC_TempCritic, TCM_WDC_Data_Pr2_cdb1pod9rsur54rd7agdaayel, TxSlp_Stat, VehCreep_Actv, WDC_IntrvntnMd_TCM, WDC_Stat, WDC_TempCritic, WDC_Trq_V2, WDC_TrqPreCtrl, ActvDnShift_Rq_ECM, CoastMd_Dsabl_Rq_ECM, CRC_Tx_Rq_PtMngmnt_ECM_Pr2, Creep_Off_Rq, ECM_LHOM_Stat, EngExhstAfterTreat_Actv, EngIdleRPM_Lvl, EngTrq_Unstbl_Stat, EngTrqMaxNxtGr, Gr1_Rq_ECM, OFC_Decel_Rdy, PtTrq_noTCMIntrvntn, Rsrv4_Tx_Rq_PtMngmnt_ECM_Pr2, ShftChrDsp_Rq, SQC_Tx_Rq_PtMngmnt_ECM_Pr2, SSA_Dsabl_Eng, TCC_Rq, Tx_Rq_PtMngmnt_ECM_Pr2_esuvr5ltdwin8dor1y7m13584, UpShft_Corr_G1_G2, UpShft_Corr_G2_G3, UpShft_Corr_G3_G4, UpShft_Corr_G4_G5, UpShft_Corr_G5_G6, UpShft_Corr_G6_G7, UpShft_Corr_G7_G8, UpShft_Corr_G8_G9, UpShft_Corr_Tx_Trgr, CRC_VehDyn_Stat1_Pr2, Rsrv1_VehDyn_Stat1_Pr2, SPCR_Excpt_Rq_V2, SPCR_Md, SPCR_Sp_Stat, SQC_VehDyn_Stat1_Pr2, VehAccel_X_Offset, VehAccel_X_Qual, VehAccel_X_V2, VehAccel_Y_Offset, VehAccel_Y_Qual, VehAccel_Y_V2, VehDyn_Stat1_Pr2_b566uuutl7t3vy8bytjwtuogy, BrkTrq_R, CRC_VehDyn_Stat2_Pr2, EPKB_Enbl_Rq, HSA_Sys_Flt, PkBrk_Rq_SPCR, SPCR_AS_Dsabl, SPCR_AS_Off_Rq, SPCR_Style, SPCR_Veh_Immo, SQC_VehDyn_Stat2_Pr2, TxPkPosn_Rq_SPCR, VehDyn_Stat2_Pr2_10f6ms25t3ycbau4qljpm984z, VehYawRate_Raw, VehYawRate_Raw_Qual, VehYawRateOffset_V2, EM_OutDC_Curr_ECM, EM_OutDC_Volt_ECM, GenLoad, PN14_Gen_Stat_9qi9lgyawpnfo9d10zylnfnr0, PN14_GenExctCurr, PN14_GenStyle, VIN_401s6nk38eqdoqdeo893qnj2y, VIN_Data1, VIN_Data2, VIN_Data3, VIN_Data4, VIN_Data5, VIN_Data6, VIN_Data7, VIN_MsgPart, CRC_Whl_Lt_Stat_Pr2, SQC_Whl_Lt_Stat_Pr2, Whl_Lt_Stat_Pr2_s0yl1k4cam60smahrd06qo1g, WhlDir_FL_Stat, WhlDir_RL_Stat, WhlPlsCnt_FL, WhlPlsCnt_RL, WhlRPM_FL, WhlRPM_FL_Qual, WhlRPM_RL, WhlRPM_RL_Qual, CRC_Whl_Rt_Stat_Pr2, SQC_Whl_Rt_Stat_Pr2, Whl_Rt_Stat_Pr2_5rdhw8834wvrtpb3zqsdx2byz, WhlDir_FR_Stat, WhlDir_RR_Stat, WhlPlsCnt_FR, WhlPlsCnt_RR, WhlRPM_FR, WhlRPM_FR_Qual, WhlRPM_RR, WhlRPM_RR_Qual, RxNorm_ASX_POWERTRAIN, RxNorm_CPC_POWERTRAIN, RxNorm_DRVU_POWERTRAIN, RxNorm_ECM_POWERTRAIN, RxNorm_FFAP_STAR_2_POWERTRAIN, RxNorm_FSCM_POWERTRAIN, RxNorm_ISM_POWERTRAIN, RxNorm_SSP_POWERTRAIN, RxNorm_TCM_POWERTRAIN, RxNorm_TGW_POWERTRAIN, TxMess_ASX_POWERTRAIN, TxMess_ISM_POWERTRAIN, TxMess_SSP_POWERTRAIN, TxMess_TCM_POWERTRAIN, TxNorm_ASX_POWERTRAIN, TxNorm_CPC_POWERTRAIN, TxNorm_DRVU_POWERTRAIN, TxNorm_ECM_POWERTRAIN, TxNorm_FFAP_STAR_2_POWERTRAIN, TxNorm_FSCM_POWERTRAIN, TxNorm_ISM_POWERTRAIN, TxNorm_SSP_POWERTRAIN, TxNorm_TCM_POWERTRAIN, TxRedu_CPC_POWERTRAIN, POWERTRAIN], system-version=2016.17.00
    mapping XDIS_SYSTEMMAPPING
